VERSION "" hyundai_kia_generic.dbc#L1

NS_ :

BS_:

BU_: IAP ODS _4WD BCM HUD DATC MDPS AAF_Tester AEMC SMK _4WD EPB CUBIS MTS TMU EVP CGW TPMS LPI DI_BOX SPAS EMS LCA TCU IBOX FATC AFLS FPCM SCC AHLS AVM ABS SNV OPI PGS SAS AAF Dummy LDWS_LKAS LVR ESC PSB CLU ECS ACU REA

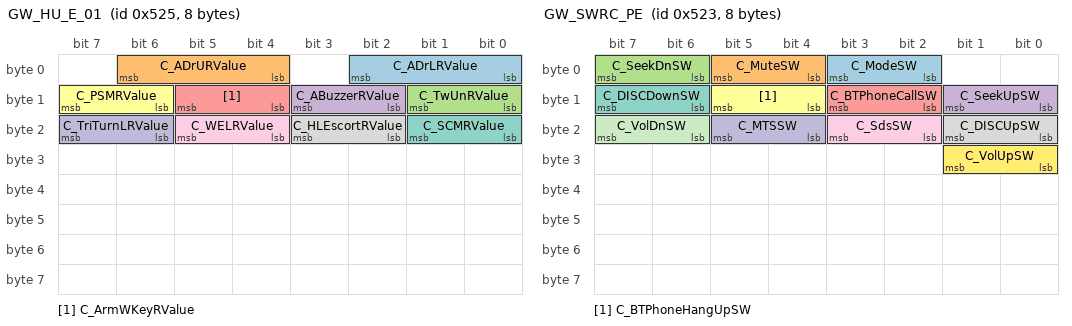
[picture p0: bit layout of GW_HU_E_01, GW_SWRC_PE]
BO_ 1317 GW_HU_E_01: 8 BCM
 SG_ C_ADrLRValue : 0|3@1+ (1.0,0.0) [0.0|7.0] ""  CLU
 SG_ C_ADrURValue : 4|3@1+ (1.0,0.0) [0.0|7.0] ""  CLU
 SG_ C_TwUnRValue : 8|2@1+ (1.0,0.0) [0.0|3.0] ""  CLU
 SG_ C_ABuzzerRValue : 10|2@1+ (1.0,0.0) [0.0|3.0] ""  CLU
 SG_ C_ArmWKeyRValue : 12|2@1+ (1.0,0.0) [0.0|3.0] ""  CLU
 SG_ C_PSMRValue : 14|2@1+ (1.0,0.0) [0.0|3.0] ""  CLU
 SG_ C_SCMRValue : 16|2@1+ (1.0,0.0) [0.0|3.0] ""  CLU
 SG_ C_HLEscortRValue : 18|2@1+ (1.0,0.0) [0.0|3.0] ""  CLU
 SG_ C_WELRValue : 20|2@1+ (1.0,0.0) [0.0|3.0] ""  CLU
 SG_ C_TriTurnLRValue : 22|2@1+ (1.0,0.0) [0.0|3.0] ""  CLU

BO_ 1316 GW_HU_E_00: 8 BCM
 SG_ C_ADrLUNValueConf : 0|2@1+ (1.0,0.0) [0.0|3.0] ""  CLU
 SG_ C_TwUnNValueConf : 2|2@1+ (1.0,0.0) [0.0|3.0] ""  CLU
 SG_ C_AlarmNValueConf : 4|2@1+ (1.0,0.0) [0.0|3.0] ""  CLU
 SG_ C_PSMNValueConf : 6|2@1+ (1.0,0.0) [0.0|3.0] ""  CLU
 SG_ C_SCMNValueConf : 8|2@1+ (1.0,0.0) [0.0|3.0] ""  CLU
 SG_ C_HLEscortNValueConf : 10|2@1+ (1.0,0.0) [0.0|3.0] ""  CLU
 SG_ C_WELNValueConf : 12|2@1+ (1.0,0.0) [0.0|3.0] ""  CLU
 SG_ C_TriTurnLNValueConf : 14|2@1+ (1.0,0.0) [0.0|3.0] ""  CLU

BO_ 1315 GW_SWRC_PE: 8 BCM
 SG_ C_ModeSW : 2|2@1+ (1.0,0.0) [0.0|3.0] ""  CLU
 SG_ C_MuteSW : 4|2@1+ (1.0,0.0) [0.0|3.0] ""  CLU
 SG_ C_SeekDnSW : 6|2@1+ (1.0,0.0) [0.0|3.0] ""  CLU
 SG_ C_SeekUpSW : 8|2@1+ (1.0,0.0) [0.0|3.0] ""  CLU
 SG_ C_BTPhoneCallSW : 10|2@1+ (1.0,0.0) [0.0|3.0] ""  CLU
 SG_ C_BTPhoneHangUpSW : 12|2@1+ (1.0,0.0) [0.0|3.0] ""  CLU
 SG_ C_DISCDownSW : 14|2@1+ (1.0,0.0) [0.0|3.0] ""  CLU
 SG_ C_DISCUpSW : 16|2@1+ (1.0,0.0) [0.0|3.0] ""  CLU
 SG_ C_SdsSW : 18|2@1+ (1.0,0.0) [0.0|3.0] ""  CLU
 SG_ C_MTSSW : 20|2@1+ (1.0,0.0) [0.0|3.0] ""  CLU
 SG_ C_VolDnSW : 22|2@1+ (1.0,0.0) [0.0|3.0] ""  CLU
 SG_ C_VolUpSW : 24|2@1+ (1.0,0.0) [0.0|3.0] ""  CLU

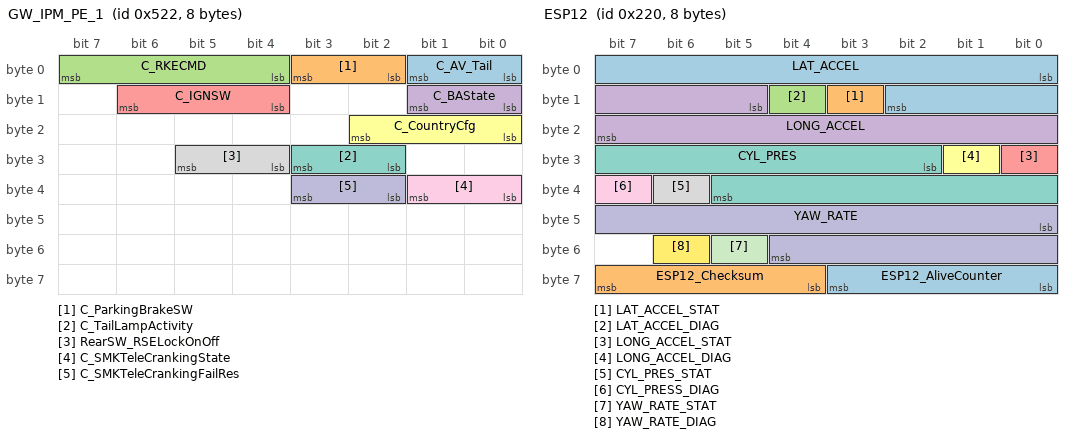
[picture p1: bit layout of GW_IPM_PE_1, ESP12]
BO_ 1314 GW_IPM_PE_1: 8 BCM
 SG_ C_AV_Tail : 0|2@1+ (1.0,0.0) [0.0|3.0] ""  CLU
 SG_ C_ParkingBrakeSW : 2|2@1+ (1.0,0.0) [0.0|3.0] ""  CLU
 SG_ C_RKECMD : 4|4@1+ (1.0,0.0) [0.0|15.0] ""  CLU
 SG_ C_BAState : 8|2@1+ (1.0,0.0) [0.0|3.0] ""  CLU
 SG_ C_IGNSW : 12|3@1+ (1.0,0.0) [0.0|7.0] ""  CLU
 SG_ C_CountryCfg : 16|3@1+ (1.0,0.0) [0.0|7.0] ""  CLU
 SG_ C_TailLampActivity : 26|2@1+ (1.0,0.0) [0.0|3.0] ""  CLU
 SG_ RearSW_RSELockOnOff : 28|2@1+ (1.0,0.0) [0.0|3.0] ""  CLU
 SG_ C_SMKTeleCrankingState : 32|2@1+ (1.0,0.0) [0.0|3.0] ""  CLU
 SG_ C_SMKTeleCrankingFailRes : 34|2@1+ (1.0,0.0) [0.0|3.0] ""  CLU

BO_ 1057 SCC12: 8 SCC
 SG_ CF_VSM_Prefill : 0|1@1+ (1,0) [0|1] "" ESC
 SG_ CF_VSM_DecCmdAct : 1|1@1+ (1,0) [0|1] "" ESC
 SG_ CF_VSM_HBACmd : 2|2@1+ (1,0) [0|3] "" ESC
 SG_ CF_VSM_Warn : 4|2@1+ (1,0) [0|3] "" CLU,ESC,IAP
 SG_ CF_VSM_Stat : 6|2@1+ (1,0) [0|3] "" CLU,ESC,PSB
 SG_ CF_VSM_BeltCmd : 8|3@1+ (1,0) [0|7] "" ESC,PSB
 SG_ ACCFailInfo : 11|2@1+ (1,0) [0|3] "" CLU,CUBIS,ESC,IBOX
 SG_ ACCMode : 13|2@1+ (1,0) [0|3] "" CLU,ESC,IBOX,TCU
 SG_ StopReq : 15|1@1+ (1,0) [0|1] "" EPB,ESC
 SG_ CR_VSM_DecCmd : 16|8@1+ (0.01,0) [0|2.55] "g" ESC
 SG_ TakeOverReq : 35|1@1+ (1,0) [0|1] "" CLU,ESC,TCU
 SG_ PreFill : 36|1@1+ (1,0) [0|1] "" ESC,TCU
 SG_ CF_VSM_ConfMode : 48|2@1+ (1,0) [0|3] "" CLU,ESC
 SG_ AEB_Failinfo : 50|2@1+ (1,0) [0|3] "" CLU,ESC
 SG_ AEB_Status : 52|2@1+ (1,0) [0|3] "" CLU,ESC
 SG_ AEB_CmdAct : 54|1@1+ (1,0) [0|1] "" ESC
 SG_ AEB_StopReq : 55|1@1+ (1,0) [0|1] "" CLU,ESC
 SG_ CR_VSM_Alive : 56|4@1+ (1,0) [0|15] "" ESC,PSB
 SG_ CR_VSM_ChkSum : 60|4@1+ (1,0) [0|15] "" ESC,PSB
 SG_ aReqValue : 37|11@1+ (0.01,-10.23) [-10.23|10.24] "m/s^2" Vector__XXX
 SG_ aReqRaw : 24|11@1+ (0.01,-10.23) [-10.23|10.24] "m/s^2" Vector__XXX

BO_ 1313 GW_DDM_PE: 8 BCM
 SG_ C_DRVDoorStatus : 0|2@1+ (1.0,0.0) [0.0|3.0] ""  CLU
 SG_ C_ASTDoorStatus : 2|2@1+ (1.0,0.0) [0.0|3.0] ""  CLU
 SG_ C_RLDoorStatus : 4|2@1+ (1.0,0.0) [0.0|3.0] ""  CLU
 SG_ C_RRDoorStatus : 6|2@1+ (1.0,0.0) [0.0|3.0] ""  CLU
 SG_ C_TrunkStatus : 8|2@1+ (1.0,0.0) [0.0|3.0] ""  CLU
 SG_ C_OSMirrorStatus : 10|2@1+ (1.0,0.0) [0.0|3.0] ""  CLU

BO_ 1056 SCC11: 8 SCC
 SG_ MainMode_ACC : 0|1@1+ (1,0) [0|1] "" CLU,EMS,ESC
 SG_ SCCInfoDisplay : 1|3@1+ (1,0) [0|7] "" CLU,ESC
 SG_ AliveCounterACC : 4|4@1+ (1,0) [0|15] "" CLU,EMS,ESC,TCU
 SG_ VSetDis : 8|8@1+ (1,0) [0|255] "km/h or MPH" CLU,ESC,TCU
 SG_ ObjValid : 16|1@1+ (1,0) [0|1] "" CLU,ESC,TCU
 SG_ DriverAlertDisplay : 17|2@1+ (1,0) [0|3] "" CLU,ESC
 SG_ TauGapSet : 19|3@1+ (1,0) [0|7] "" CLU,ESC,TCU
 SG_ Navi_SCC_Curve_Status : 56|2@1+ (1,0) [0|3] "" CLU
 SG_ Navi_SCC_Curve_Act : 58|2@1+ (1,0) [0|3] "" CLU
 SG_ Navi_SCC_Camera_Act : 60|2@1+ (1,0) [0|3] "" CLU
 SG_ Navi_SCC_Camera_Status : 62|2@1+ (1,0) [0|3] "" CLU
 SG_ ACC_ObjStatus : 22|2@1+ (1,0) [0|3] "" ABS,ESC
 SG_ ACC_ObjLatPos : 24|9@1+ (0.1,-20) [-20|31.1] "m" ABS,ESC
 SG_ ACC_ObjRelSpd : 44|12@1+ (0.1,-170) [-170|239.5] "m/s" ABS,ESC
 SG_ ACC_ObjDist : 33|11@1+ (0.1,0) [0|204.7] "m" ABS,ESC

BO_ 1312 CGW3: 8 BCM
 SG_ CR_Photosensor_LH : 0|8@1+ (78.125,0.0) [0.0|20000.0] ""  DATC,DATC
 SG_ CR_Photosensor_RH : 10|8@1+ (78.125,0.0) [0.0|20000.0] ""  DATC,DATC
 SG_ CF_Hoodsw_memory : 22|2@1+ (1.0,0.0) [0.0|3.0] ""  EMS,EMS
 SG_ C_MirOutTempSns : 24|8@1+ (0.5,-40.5) [-40.0|60.0] "deg"  AAF,CLU,DATC,EMS,SPAS,AAF,DATC,EMS,SPAS

BO_ 544 ESP12: 8 ESC
 SG_ LAT_ACCEL : 0|11@1+ (0.01,-10.23) [-10.23|10.24] "m/s^2"  _4WD,ECS,IBOX,LCA,LDWS_LKAS,MDPS,PSB,SCC,TCU
 SG_ LAT_ACCEL_STAT : 11|1@1+ (1.0,0.0) [0.0|1.0] ""  _4WD,IBOX,LDWS_LKAS,MDPS,PSB,SCC,TCU
 SG_ LAT_ACCEL_DIAG : 12|1@1+ (1.0,0.0) [0.0|1.0] ""  _4WD,IBOX,LDWS_LKAS,MDPS,PSB,SCC,TCU
 SG_ LONG_ACCEL : 13|11@1+ (0.01,-10.23) [-10.23|10.24] "m/s^2"  _4WD,ECS,EMS,EPB,IBOX,LCA,LDWS_LKAS,PSB,SCC,SPAS,TCU
 SG_ LONG_ACCEL_STAT : 24|1@1+ (1.0,0.0) [0.0|1.0] ""  _4WD,EMS,EPB,IBOX,LDWS_LKAS,PSB,SCC,SPAS,TCU
 SG_ LONG_ACCEL_DIAG : 25|1@1+ (1.0,0.0) [0.0|1.0] ""  _4WD,EMS,EPB,IBOX,LDWS_LKAS,PSB,SCC,SPAS,TCU
 SG_ CYL_PRES : 26|12@1+ (0.1,0.0) [0.0|409.5] "Bar"  _4WD,ECS,EMS,EPB,IBOX,LDWS_LKAS,PSB,SCC,TCU
 SG_ CYL_PRES_STAT : 38|1@1+ (1.0,0.0) [0.0|1.0] ""  _4WD,ECS,EMS,EPB,IBOX,LDWS_LKAS,PSB,SCC,TCU
 SG_ CYL_PRESS_DIAG : 39|1@1+ (1.0,0.0) [0.0|1.0] ""  _4WD,ECS,EMS,EPB,IBOX,PSB,SCC,TCU
 SG_ YAW_RATE : 40|13@1+ (0.01,-40.95) [-40.95|40.96] ""  _4WD,AFLS,IBOX,LCA,LDWS_LKAS,MDPS,PSB,SCC,SPAS,TCU
 SG_ YAW_RATE_STAT : 53|1@1+ (1.0,0.0) [0.0|1.0] ""  _4WD,AFLS,IBOX,LCA,LDWS_LKAS,MDPS,PSB,SCC,SPAS,TCU
 SG_ YAW_RATE_DIAG : 54|1@1+ (1.0,0.0) [0.0|1.0] ""  _4WD,AFLS,IBOX,LCA,LDWS_LKAS,MDPS,PSB,SCC,SPAS,TCU
 SG_ ESP12_AliveCounter : 56|4@1+ (1.0,0.0) [0.0|15.0] ""  _4WD,EMS,LPI,TCU,TMU
 SG_ ESP12_Checksum : 60|4@1+ (1.0,0.0) [0.0|15.0] ""  _4WD,EMS,LPI,TCU,TMU

BO_ 1307 CLU16: 8 CLU
 SG_ CF_Clu_TirePressUnitNValueSet : 0|3@1+ (1.0,0.0) [0.0|7.0] ""  TPMS
 SG_ CF_Clu_SlifNValueSet : 3|2@1+ (1.0,0.0) [0.0|3.0] ""  LDWS_LKAS
 SG_ CF_Clu_RearWiperNValueSet : 12|2@1+ (1.0,0.0) [0.0|3.0] ""  BCM

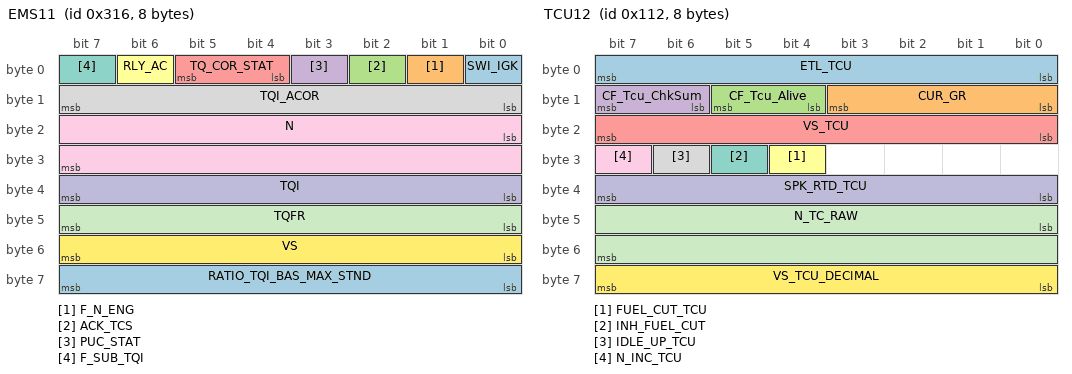
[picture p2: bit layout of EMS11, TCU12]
BO_ 790 EMS11: 8 EMS
 SG_ SWI_IGK : 0|1@1+ (1.0,0.0) [0.0|1.0] ""  _4WD,ABS,ACU,AHLS,CUBIS,DI_BOX,ECS,EPB,ESC,IBOX,LDWS_LKAS,MDPS,REA,SAS,SCC,TCU
 SG_ F_N_ENG : 1|1@1+ (1.0,0.0) [0.0|1.0] ""  _4WD,ACU,AFLS,CLU,CUBIS,DATC,ECS,EPB,ESC,IBOX,MDPS,SCC,TCU
 SG_ ACK_TCS : 2|1@1+ (1.0,0.0) [0.0|1.0] ""  ESC,IBOX
 SG_ PUC_STAT : 3|1@1+ (1.0,0.0) [0.0|1.0] ""  _4WD,CLU,DATC,IBOX,TCU
 SG_ TQ_COR_STAT : 4|2@1+ (1.0,0.0) [0.0|3.0] ""  _4WD,ESC,IBOX,TCU
 SG_ RLY_AC : 6|1@1+ (1.0,0.0) [0.0|1.0] ""  DATC,IBOX,TCU
 SG_ F_SUB_TQI : 7|1@1+ (1.0,0.0) [0.0|1.0] ""  _4WD,ECS,EPB,ESC,IBOX,TCU
 SG_ TQI_ACOR : 8|8@1+ (0.390625,0.0) [0.0|99.6094] "%"  _4WD,EPB,ESC,IBOX,TCU
 SG_ N : 16|16@1+ (0.25,0.0) [0.0|16383.75] "rpm"  _4WD,ACU,AFLS,CLU,CUBIS,DATC,ECS,EPB,ESC,FPCM,IBOX,MDPS,SCC,TCU
 SG_ TQI : 32|8@1+ (0.390625,0.0) [0.0|99.6094] "%"  _4WD,ECS,EPB,ESC,IBOX,TCU
 SG_ TQFR : 40|8@1+ (0.390625,0.0) [0.0|99.6094] "%"  _4WD,EPB,ESC,IBOX,TCU
 SG_ VS : 48|8@1+ (1.0,0.0) [0.0|254.0] "km/h"  _4WD,AAF,ACU,AHLS,BCM,CLU,DATC,ECS,EPB,IBOX,LCA,LDWS_LKAS,LVR,MDPS,ODS,SCC,SMK,SPAS,TCU,TPMS
 SG_ RATIO_TQI_BAS_MAX_STND : 56|8@1+ (0.0078,0.0) [0.0|2.0] ""  _4WD,IBOX,TCU

BO_ 1301 CLU14: 8 CLU
 SG_ CF_Clu_ADrUNValueSet : 0|3@1+ (1.0,0.0) [0.0|7.0] ""  BCM
 SG_ CF_Clu_ADrLNValueSet : 3|3@1+ (1.0,0.0) [0.0|7.0] ""  BCM
 SG_ CF_Clu_EscortHLNValueSet : 6|2@1+ (1.0,0.0) [0.0|3.0] ""  BCM
 SG_ CF_Clu_DoorLSNValueSet : 8|3@1+ (1.0,0.0) [0.0|7.0] ""  BCM
 SG_ CF_Clu_PSMNValueSet : 11|3@1+ (1.0,0.0) [0.0|7.0] ""  BCM
 SG_ CF_Clu_TTUnlockNValueSet : 14|2@1+ (1.0,0.0) [0.0|3.0] ""  BCM
 SG_ CF_Clu_PTGMNValueSet : 16|2@1+ (1.0,0.0) [0.0|3.0] ""  BCM
 SG_ CF_Clu_SCMNValueSet : 18|2@1+ (1.0,0.0) [0.0|3.0] ""  BCM
 SG_ CF_Clu_WlightNValueSet : 20|2@1+ (1.0,0.0) [0.0|3.0] ""  BCM
 SG_ CF_Clu_TempUnitNValueSet : 22|2@1+ (1.0,0.0) [0.0|3.0] ""  BCM,DATC
 SG_ CF_Clu_MoodLpNValueSet : 24|3@1+ (1.0,0.0) [0.0|7.0] ""  BCM
 SG_ CF_Clu_TrfChgSet : 27|2@1+ (1.0,0.0) [0.0|3.0] ""  AFLS
 SG_ CF_Clu_OTTurnNValueSet : 29|3@1+ (1.0,0.0) [0.0|7.0] ""  BCM
 SG_ CF_Clu_LcaNValueSet : 32|2@1+ (1.0,0.0) [0.0|3.0] ""  LCA
 SG_ CF_Clu_RctaNValueSet : 34|2@1+ (1.0,0.0) [0.0|3.0] ""  LCA
 SG_ CF_Clu_RcwNValueSet : 36|2@1+ (1.0,0.0) [0.0|3.0] ""  LCA
 SG_ CF_Clu_EscOffNValueSet : 38|3@1+ (1.0,0.0) [0.0|7.0] ""  ESC
 SG_ CF_Clu_SccNaviCrvNValueSet : 41|2@1+ (1.0,0.0) [0.0|3.0] ""  SCC
 SG_ CF_Clu_SccNaviCamNValueSet : 43|2@1+ (1.0,0.0) [0.0|3.0] ""  SCC
 SG_ CF_Clu_SccAebNValueSet : 45|2@1+ (1.0,0.0) [0.0|3.0] ""  SCC
 SG_ CF_Clu_LkasModeNValueSet : 47|2@1+ (1.0,0.0) [0.0|3.0] ""  LDWS_LKAS
 SG_ CF_Clu_FcwNValueSet : 51|2@1+ (1.0,0.0) [0.0|3.0] ""  LDWS_LKAS
 SG_ CF_Clu_PasSpkrLvNValueSet : 53|3@1+ (1.0,0.0) [0.0|7.0] ""  BCM
 SG_ CF_Clu_SccDrvModeNValueSet : 56|3@1+ (1.0,0.0) [0.0|7.0] ""  SCC
 SG_ CF_Clu_HAnBNValueSet : 59|2@1+ (1.0,0.0) [0.0|3.0] ""  BCM
 SG_ CF_Clu_HfreeTrunkTgNValueSet : 61|3@1+ (1.0,0.0) [0.0|7.0] ""  BCM

BO_ 275 TCU13: 8 TCU
 SG_ N_TGT_LUP : 0|8@1+ (10.0,500.0) [500.0|3040.0] "rpm"  EMS,IBOX
 SG_ SLOPE_TCU : 8|6@1+ (0.5,-16.0) [-16.0|15.5] "%"  CLU,CUBIS,EMS,IBOX
 SG_ CF_Tcu_InhCda : 14|1@1+ (1.0,0.0) [0.0|1.0] ""  EMS,IBOX
 SG_ CF_Tcu_IsgInhib : 15|1@1+ (1.0,0.0) [0.0|1.0] ""  EMS,IBOX
 SG_ CF_Tcu_BkeOnReq : 16|2@1+ (1.0,0.0) [0.0|3.0] ""  EMS,IBOX
 SG_ CF_Tcu_NCStat : 18|2@1+ (1.0,0.0) [0.0|3.0] ""  EMS,IBOX
 SG_ CF_Tcu_TarGr : 20|4@1+ (1.0,0.0) [0.0|15.0] ""  _4WD,CLU,DATC,EMS,EPB,ESC,IBOX,SCC
 SG_ CF_Tcu_ShfPatt : 24|4@1+ (1.0,0.0) [0.0|15.0] ""  CLU,CUBIS,EMS,IBOX
 SG_ CF_Tcu_InhVis : 28|1@1+ (1.0,0.0) [0.0|1.0] ""  EMS,IBOX
 SG_ CF_Tcu_PRelReq : 29|1@1+ (1.0,0.0) [0.0|1.0] ""  IBOX,LVR
 SG_ CF_Tcu_ITPhase : 30|1@1+ (1.0,0.0) [0.0|1.0] ""  EMS,IBOX
 SG_ CF_Tcu_ActEcoRdy : 31|1@1+ (1.0,0.0) [0.0|1.0] ""  EMS,IBOX
 SG_ CF_Tcu_TqGrdLim : 32|8@1+ (10.0,0.0) [0.0|2540.0] "Nm/s"  EMS,IBOX
 SG_ CR_Tcu_IsgTgtRPM : 40|8@1+ (20.0,0.0) [0.0|3500.0] "rpm"  EMS,IBOX
 SG_ CF_Tcu_SptRdy : 48|1@1+ (1.0,0.0) [0.0|1.0] ""  CLU,IBOX
 SG_ CF_Tcu_SbwPInfo : 56|1@1+ (1.0,0.0) [0.0|1.0] ""  EMS,IBOX
 SG_ CF_Tcu_Alive3 : 58|2@1+ (1.0,0.0) [0.0|3.0] ""  EMS,IBOX
 SG_ CF_Tcu_ChkSum3 : 60|4@1+ (1.0,0.0) [0.0|15.0] ""  EMS,IBOX

BO_ 274 TCU12: 8 TCU
 SG_ ETL_TCU : 0|8@1+ (2.0,0.0) [0.0|508.0] "Nm"  EMS,IBOX
 SG_ CUR_GR : 8|4@1+ (1.0,0.0) [0.0|15.0] ""  _4WD,EMS,ESC,IBOX,SCC,TPMS
 SG_ CF_Tcu_Alive : 12|2@1+ (1.0,0.0) [0.0|3.0] ""  EMS,ESC,IBOX,SCC
 SG_ CF_Tcu_ChkSum : 14|2@1+ (1.0,0.0) [0.0|3.0] ""  EMS,ESC,IBOX,SCC
 SG_ VS_TCU : 16|8@1+ (1.0,0.0) [0.0|254.0] "km/h"  BCM,CLU,DATC,EMS,IBOX,LCA,LVR,PGS,SMK,SNV
 SG_ FUEL_CUT_TCU : 28|1@1+ (1.0,0.0) [0.0|1.0] ""  EMS,IBOX
 SG_ INH_FUEL_CUT : 29|1@1+ (1.0,0.0) [0.0|1.0] ""  EMS,IBOX
 SG_ IDLE_UP_TCU : 30|1@1+ (1.0,0.0) [0.0|1.0] ""  EMS,IBOX
 SG_ N_INC_TCU : 31|1@1+ (1.0,0.0) [0.0|1.0] ""  EMS,IBOX
 SG_ SPK_RTD_TCU : 32|8@1+ (0.375,-23.625) [-15.0|15.0] ""  EMS,IBOX
 SG_ N_TC_RAW : 40|16@1+ (0.25,0.0) [0.0|16383.5] "rpm"  EMS,IBOX
 SG_ VS_TCU_DECIMAL : 56|8@1+ (0.0078125,0.0) [0.0|0.9921875] "km/h"  CLU,EMS,IBOX,LCA

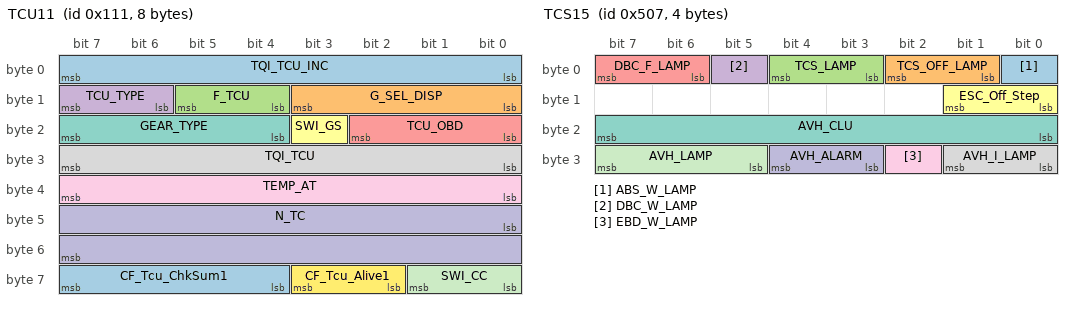
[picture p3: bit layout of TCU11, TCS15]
BO_ 273 TCU11: 8 TCU
 SG_ TQI_TCU_INC : 0|8@1+ (0.390625,0.0) [0.0|99.609375] "%"  EMS,ESC,IBOX
 SG_ G_SEL_DISP : 8|4@1+ (1.0,0.0) [0.0|15.0] ""  _4WD,AFLS,AVM,BCM,CGW,CLU,CUBIS,ECS,EMS,EPB,ESC,IAP,IBOX,LCA,LDWS_LKAS,LVR,MDPS,PGS,SCC,SMK,SNV,SPAS,TPMS
 SG_ F_TCU : 12|2@1+ (1.0,0.0) [0.0|3.0] ""  EMS,ESC,IBOX
 SG_ TCU_TYPE : 14|2@1+ (1.0,0.0) [0.0|3.0] ""  _4WD,EMS,ESC,IBOX
 SG_ TCU_OBD : 16|3@1+ (1.0,0.0) [0.0|7.0] ""  EMS,ESC,IBOX
 SG_ SWI_GS : 19|1@1+ (1.0,0.0) [0.0|1.0] ""  _4WD,EMS,EPB,ESC,IBOX,SCC
 SG_ GEAR_TYPE : 20|4@1+ (1.0,0.0) [0.0|15.0] ""  _4WD,CLU,EMS,ESC,IBOX,SCC
 SG_ TQI_TCU : 24|8@1+ (0.390625,0.0) [0.0|99.609375] "%"  EMS,ESC,IBOX
 SG_ TEMP_AT : 32|8@1+ (1.0,-40.0) [-40.0|214.0] "deg"  AAF,CLU,CUBIS,EMS,ESC,IBOX
 SG_ N_TC : 40|16@1+ (0.25,0.0) [0.0|16383.5] "rpm"  _4WD,EMS,EPB,ESC,IBOX
 SG_ SWI_CC : 56|2@1+ (1.0,0.0) [0.0|3.0] ""  _4WD,CLU,EMS,ESC,IBOX
 SG_ CF_Tcu_Alive1 : 58|2@1+ (1.0,0.0) [0.0|3.0] ""  EMS,IBOX
 SG_ CF_Tcu_ChkSum1 : 60|4@1+ (1.0,0.0) [0.0|15.0] ""  EMS,IBOX

BO_ 16 ACU13: 8 ACU
 SG_ CF_Acu_CshAct : 0|1@1+ (1.0,0.0) [0.0|1.0] ""  CUBIS,IBOX,ODS

BO_ 1040 CGW_USM1: 8 BCM
 SG_ CF_Gway_ATTurnRValue : 0|2@1+ (1.0,0.0) [0.0|3.0] ""  CLU
 SG_ CF_Gway_PTGMRValue : 2|2@1+ (1.0,0.0) [0.0|3.0] ""  CLU
 SG_ CF_Gway_EscortHLRValue : 4|2@1+ (1.0,0.0) [0.0|3.0] ""  CLU
 SG_ CF_Gway_TTUnlockRValue : 6|2@1+ (1.0,0.0) [0.0|3.0] ""  CLU
 SG_ CF_Gway_ADrLRValue : 8|3@1+ (1.0,0.0) [0.0|7.0] ""  CLU
 SG_ CF_Gway_ADrURValue : 11|3@1+ (1.0,0.0) [0.0|7.0] ""  CLU
 SG_ CF_Gway_SCMRValue : 14|2@1+ (1.0,0.0) [0.0|3.0] ""  CLU
 SG_ CF_Gway_WlightRValue : 16|2@1+ (1.0,0.0) [0.0|3.0] ""  CLU
 SG_ CF_Gway_PSMRValue : 18|3@1+ (1.0,0.0) [0.0|7.0] ""  CLU
 SG_ CF_Gway_OTTurnRValue : 21|3@1+ (1.0,0.0) [0.0|7.0] ""  CLU
 SG_ CF_Gway_DrLockSoundRValue : 24|3@1+ (1.0,0.0) [0.0|7.0] ""  CLU
 SG_ CF_Gway_HAnBRValue : 27|3@1+ (1.0,0.0) [0.0|7.0] ""  CLU
 SG_ CF_Gway_MoodLpRValue : 30|2@1+ (1.0,0.0) [0.0|3.0] ""  CLU
 SG_ CF_Gway_HfreeTrunkRValue : 32|3@1+ (1.0,0.0) [0.0|7.0] ""  CLU
 SG_ CF_Gway_AutoLightRValue : 35|3@1+ (1.0,0.0) [0.0|7.0] ""  CLU
 SG_ CF_Gway_RearWiperRValue : 38|2@1+ (1.0,0.0) [0.0|3.0] ""  CLU
 SG_ CF_Gway_PasSpkrLvRValue : 40|3@1+ (1.0,0.0) [0.0|7.0] ""  CLU

BO_ 1292 CLU13: 8 CLU
 SG_ CF_Clu_LowfuelWarn : 0|2@1+ (1.0,0.0) [0.0|3.0] ""  BCM,FPCM,IBOX
 SG_ CF_Clu_RefDetMod : 2|1@1+ (1.0,0.0) [0.0|1.0] ""  IBOX
 SG_ CF_Clu_AvgFCU : 3|2@1+ (1.0,0.0) [0.0|3.0] ""  IBOX
 SG_ CF_Clu_AvsmCur : 5|1@1+ (1.0,0.0) [0.0|1.0] ""  ESC,SCC
 SG_ CF_Clu_AvgFCI : 6|10@1+ (0.1,0.0) [0.0|102.2] ""  IBOX
 SG_ CF_Clu_DrivingModeSwi : 16|2@1+ (1.0,0.0) [0.0|3.0] ""  DATC,ECS,EMS,ESC,IAP,MDPS,TCU
 SG_ CF_Clu_FuelDispLvl : 18|5@1+ (1.0,0.0) [0.0|31.0] ""  CGW,IBOX
 SG_ CF_Clu_FlexSteerSW : 23|1@1+ (1.0,0.0) [0.0|1.0] ""  MDPS
 SG_ CF_Clu_DTE : 24|10@1+ (1.0,0.0) [0.0|1023.0] ""  DATC
 SG_ CF_Clu_TripUnit : 34|2@1+ (1.0,0.0) [0.0|3.0] ""  DATC
 SG_ CF_Clu_SWL_Stat : 36|3@1+ (1.0,0.0) [0.0|7.0] ""  ACU,EMS
 SG_ CF_Clu_ActiveEcoSW : 39|1@1+ (1.0,0.0) [0.0|1.0] ""  DATC,EMS,TCU
 SG_ CF_Clu_EcoDriveInf : 40|3@1+ (1.0,0.0) [0.0|7.0] ""  CUBIS,EMS,IAP,IBOX
 SG_ CF_Clu_IsaMainSW : 43|1@1+ (1.0,0.0) [0.0|1.0] ""  EMS
 SG_ CF_Clu_LdwsLkasSW : 56|1@1+ (1.0,0.0) [0.0|1.0] ""  LDWS_LKAS
 SG_ CF_Clu_AltLStatus : 59|1@1+ (1.0,0.0) [0.0|1.0] ""  BCM,DATC,EMS
 SG_ CF_Clu_AliveCnt2 : 60|4@1+ (1.0,0.0) [0.0|15.0] ""  EMS,LDWS_LKAS

BO_ 1290 SCC13: 8 SCC
 SG_ SCCDrvModeRValue : 0|3@1+ (1,0) [0|7] "" CLU
 SG_ SCC_Equip : 3|1@1+ (1,0) [0|1] "" ESC
 SG_ AebDrvSetStatus : 4|3@1+ (1,0) [0|7] "" CLU,ESC
 SG_ Lead_Veh_Dep_Alert_USM : 13|2@0+ (1,0) [0|3] "" XXX

BO_ 1287 TCS15: 4 ESC
 SG_ ABS_W_LAMP : 0|1@1+ (1.0,0.0) [0.0|1.0] ""  _4WD,CLU,CUBIS,IBOX
 SG_ TCS_OFF_LAMP : 1|2@1+ (1.0,0.0) [0.0|1.0] ""  _4WD,ACU,CLU
 SG_ TCS_LAMP : 3|2@1+ (1.0,0.0) [0.0|3.0] ""  _4WD,ACU,CLU,CUBIS,IBOX,SCC
 SG_ DBC_W_LAMP : 5|1@1+ (1.0,0.0) [0.0|1.0] ""  _4WD,CLU
 SG_ DBC_F_LAMP : 6|2@1+ (1.0,0.0) [0.0|3.0] ""  _4WD,CLU
 SG_ ESC_Off_Step : 8|2@1+ (1.0,0.0) [0.0|3.0] ""  CLU
 SG_ AVH_CLU : 16|8@1+ (1.0,0.0) [0.0|255.0] ""  CLU,EPB
 SG_ AVH_I_LAMP : 24|2@1+ (1.0,0.0) [0.0|3.0] ""  EPB
 SG_ EBD_W_LAMP : 26|1@1+ (1.0,0.0) [0.0|1.0] ""  _4WD,CLU
 SG_ AVH_ALARM : 27|2@1+ (1.0,0.0) [0.0|3.0] ""  CLU
 SG_ AVH_LAMP : 29|3@1+ (1.0,0.0) [0.0|7.0] ""  CLU,EPB,SPAS

BO_ 1282 TCU14: 4 TCU
 SG_ CF_TCU_WarnMsg : 0|3@1+ (1.0,0.0) [0.0|7.0] ""  CLU
 SG_ CF_TCU_WarnImg : 3|1@1+ (1.0,0.0) [0.0|1.0] ""  CLU
 SG_ CF_TCU_WarnSnd : 4|1@1+ (1.0,0.0) [0.0|1.0] ""  CLU
 SG_ CF_Tcu_GSel_BlinkReq : 5|1@1+ (1.0,0.0) [0.0|1.0] ""  CLU,LVR
 SG_ CF_Tcu_StRelStat : 12|1@1+ (1.0,0.0) [0.0|1.0] ""  CLU,EMS,ESC
 SG_ CF_Tcu_DriWarn1 : 13|3@1+ (1.0,0.0) [0.0|7.0] ""  CLU,EMS,ESC
 SG_ CF_Tcu_DriWarn2 : 16|2@1+ (1.0,0.0) [0.0|3.0] ""  CLU,EMS,ESC

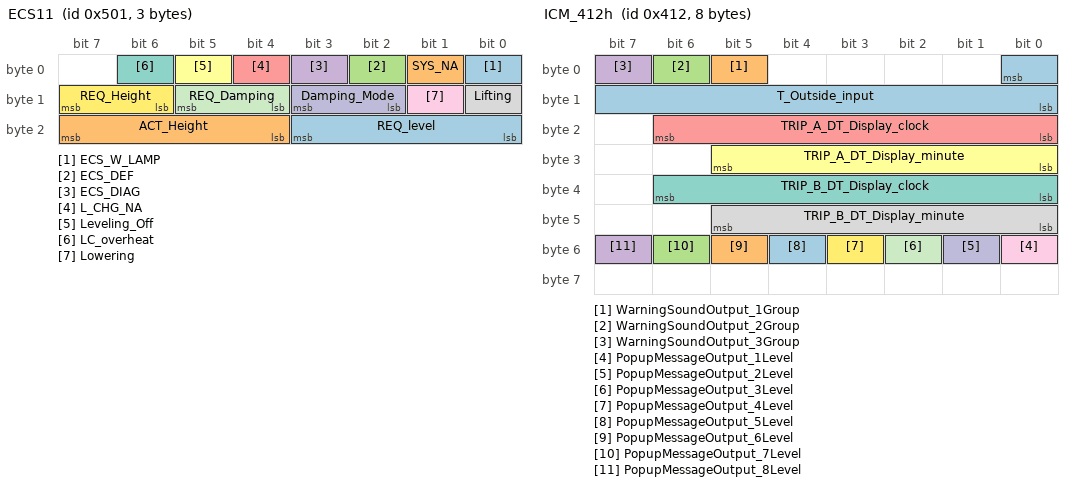
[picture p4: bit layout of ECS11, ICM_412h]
BO_ 1281 ECS11: 3 ECS
 SG_ ECS_W_LAMP : 0|1@1+ (1.0,0.0) [0.0|1.0] ""  CLU,CUBIS,IBOX
 SG_ SYS_NA : 1|1@1+ (1.0,0.0) [0.0|1.0] ""  CLU
 SG_ ECS_DEF : 2|1@1+ (1.0,0.0) [0.0|1.0] ""  CLU
 SG_ ECS_DIAG : 3|1@1+ (1.0,0.0) [0.0|1.0] ""  CLU
 SG_ L_CHG_NA : 4|1@1+ (1.0,0.0) [0.0|1.0] ""  CLU
 SG_ Leveling_Off : 5|1@1+ (1.0,0.0) [0.0|1.0] ""  CLU
 SG_ LC_overheat : 6|1@1+ (1.0,0.0) [0.0|1.0] ""  CLU
 SG_ Lifting : 8|1@1+ (1.0,0.0) [0.0|1.0] ""  CLU
 SG_ Lowering : 9|1@1+ (1.0,0.0) [0.0|1.0] ""  CLU
 SG_ Damping_Mode : 10|2@1+ (1.0,0.0) [0.0|3.0] ""  CLU
 SG_ REQ_Damping : 12|2@1+ (1.0,0.0) [0.0|3.0] ""  CLU
 SG_ REQ_Height : 14|2@1+ (1.0,0.0) [0.0|3.0] ""  CLU
 SG_ REQ_level : 16|4@1+ (1.0,0.0) [0.0|15.0] ""  CLU
 SG_ ACT_Height : 20|4@1+ (1.0,0.0) [0.0|15.0] ""  CLU

BO_ 1024 CLU_CFG11: 2 CLU
 SG_ Vehicle_Type : 0|16@1+ (1.0,0.0) [0.0|65536.0] ""  _4WD

BO_ 1280 ACU14: 1 ACU
 SG_ CF_SWL_Ind : 0|2@1+ (1.0,0.0) [0.0|3.0] ""  CLU
 SG_ CF_TTL_Ind : 2|2@1+ (1.0,0.0) [0.0|3.0] ""  CLU
 SG_ CF_SBR_Ind : 4|2@1+ (1.0,0.0) [0.0|3.0] ""  BCM,CLU

BO_ 512 EMS20: 6 EMS
 SG_ FCO : 0|16@1+ (0.128,0.0) [0.0|8388.48] "ul"  CLU,CUBIS,FPCM,IBOX
 SG_ CF_Ems_PumpTPres : 16|8@1+ (3.137254902,0.0) [0.0|800.0] "kPa"  FPCM,IBOX
 SG_ Split_Stat : 32|1@1+ (1.0,0.0) [0.0|1.0] ""  FPCM

BO_ 909 FCA11: 8 FCA
 SG_ CF_VSM_Prefill : 0|1@1+ (1,0) [0|1] "" ESC
 SG_ CF_VSM_HBACmd : 1|2@1+ (1,0) [0|3] "" ESC
 SG_ CF_VSM_Warn : 3|2@1+ (1,0) [0|3] "" ACU,CLU,ESC
 SG_ CF_VSM_BeltCmd : 5|3@1+ (1,0) [0|7] "" ESC
 SG_ CR_VSM_DecCmd : 8|8@1+ (0.01,0) [0|2.55] "g" ESC
 SG_ FCA_Status : 18|2@1+ (1,0) [0|3] "" ACU,CLU,ESC
 SG_ FCA_CmdAct : 20|1@1+ (1,0) [0|1] "" ESC
 SG_ FCA_StopReq : 21|1@1+ (1,0) [0|1] "" CLU,ESC
 SG_ FCA_DrvSetStatus : 22|3@1+ (1,0) [0|7] "" CLU,ESC
 SG_ CF_VSM_DecCmdAct : 31|1@1+ (1,0) [0|1] "" ESC
 SG_ FCA_Failinfo : 32|3@1+ (1,0) [0|7] "" ACU,CLU,ESC
 SG_ FCA_RelativeVelocity : 39|9@1+ (0.1,-25.5) [-25.5|25.5] "m/s" iBAU
 SG_ FCA_TimetoCollision : 48|8@1+ (10,0) [0|2540] "ms" iBAU
 SG_ CR_FCA_Alive : 56|4@1+ (1,0) [0|15] "" ESC
 SG_ CR_FCA_ChkSum : 60|4@1+ (1,0) [0|15] "" ESC
 SG_ Supplemental_Counter : 35|4@1+ (1,0) [0|15] "" XXX
 SG_ PAINT1_Status : 16|2@1+ (1,0) [0|1] "" XXX

BO_ 1156 HDA11_MFC: 8 XXX
 SG_ Counter : 5|4@0+ (1,0) [0|15] "" XXX
 SG_ NEW_SIGNAL_1 : 1|2@0+ (1,0) [0|255] "" XXX
 SG_ NEW_SIGNAL_2 : 7|2@0+ (1,0) [0|3] "" XXX
 SG_ NEW_SIGNAL_3 : 15|8@0+ (1,0) [0|255] "" XXX
 SG_ NEW_SIGNAL_4 : 16|2@1+ (1,0) [0|3] "" XXX
 SG_ NEW_SIGNAL_5 : 18|14@1+ (1,0) [0|63] "" XXX
 SG_ NEW_SIGNAL_6 : 33|2@0+ (1,0) [0|1] "" XXX
 SG_ NEW_SIGNAL_7 : 34|14@1+ (1,0) [0|16383] "" XXX
 SG_ NEW_SIGNAL_8 : 49|2@0+ (1,0) [0|1] "" XXX
 SG_ NEW_SIGNAL_9 : 50|14@1- (1,-4095) [0|16383] "" XXX

BO_ 1155 FCA12: 8 FCA
 SG_ FCA_USM : 0|3@1+ (1,0) [0|7] "" CGW,CLU,ESC
 SG_ FCA_DrvSetState : 3|3@1+ (1,0) [0|7] "" CGW

BO_ 1186 FRT_RADAR11: 2 FCA
 SG_ CF_FCA_Equip_Front_Radar : 0|3@1+ (1,0) [0|7] "" LDWS_LKAS,LDW_LKA,ESC

BO_ 905 SCC14: 8 SCC
 SG_ ComfortBandUpper : 0|6@1+ (0.0986,-4.14) [0|1.26] "m/s^2" ESC
 SG_ ComfortBandLower : 6|6@1+ (0.0986,-4.14) [0|1.26] "m/s^2" ESC
 SG_ JerkUpperLimit : 12|7@1+ (1,0) [0|12.7] "m/s^3" ESC
 SG_ JerkLowerLimit : 19|7@1+ (0.1,0) [0|12.7] "m/s^3" ESC
 SG_ ACCMode : 32|3@1+ (1,0) [0|7] "" CLU,HUD,LDWS_LKAS,ESC
 SG_ ObjGap : 56|8@1+ (1,0) [0|255] "" CLU,HUD,ESC

BO_ 1157 LFAHDA_MFC: 4 XXX
 SG_ HDA_USM : 0|2@1+ (1,0) [0|3] "" XXX
 SG_ ACTIVE2 : 4|2@0+ (1,0) [0|3] "" XXX
 SG_ LFA_SysWarning : 16|2@1+ (1,0) [0|3] "" XXX
 SG_ ACTIVE : 25|1@1+ (1,0) [0|3] "" XXX
 SG_ LFA_USM : 28|2@1+ (1,0) [0|3] "" XXX

BO_ 913 BCM_PO_11: 8 Vector__XXX
 SG_ BCM_Door_Dri_Status : 5|1@0+ (1,0) [0|1] "" PT_ESC_ABS
 SG_ BCM_Shift_R_MT_SW_Status : 39|2@0+ (1,0) [0|3] "" PT_ESC_ABS

BO_ 1426 LABEL11: 8 XXX
 SG_ CC_React : 34|1@1+ (1,0) [0|1] "" XXX

BO_ 910 WHL_SPD12_FS: 5 iBAU
 SG_ CRC : 0|8@1+ (1,0) [0|0] "" Vector__XXX
 SG_ WHL_SPD12_AliveCounter : 8|4@1+ (1,0) [0|15] "" Vector__XXX
 SG_ WHL_SPD_FL : 12|14@1+ (0.03125,0) [0|511.96875] "km/h" Vector__XXX
 SG_ WHL_SPD_FR : 26|14@1+ (0.03125,0) [0|511.96875] "km/h" Vector__XXX

BO_ 911 WHL_SPD13_FS: 5 iBAU
 SG_ CRC : 0|8@1+ (1,0) [0|0] "" Vector__XXX
 SG_ WHL_SPD13_AliveCounter : 8|4@1+ (1,0) [0|15] "" Vector__XXX
 SG_ WHL_SPD_RL : 12|14@1+ (0.03125,0) [0|511.96875] "km/h" Vector__XXX
 SG_ WHL_SPD_RR : 26|14@1+ (0.03125,0) [0|511.96875] "km/h" Vector__XXX

BO_ 865 ADAS_PRK_11: 8 ADAS_PRK
 SG_ CF_PCA_BrkReq : 24|1@1+ (1,0) [0|0] "" Vector__XXX
 SG_ CF_PCA_DclTrgtVal : 28|4@1+ (0.04,0) [0|0] "g" Vector__XXX
 SG_ PCA_ALIVE_CNT : 40|4@1+ (1,0) [0|0] "" Vector__XXX
 SG_ PCA_CHECK_SUM : 48|8@1+ (1,0) [0|0] "" Vector__XXX

BO_ 882 ELECT_GEAR: 8 XXX
 SG_ Elect_Gear_Shifter : 16|4@1+ (1,0) [0|7] ""  CLU

BO_ 881 E_EMS11: 8 XXX
 SG_ Brake_Pedal_Pos : 0|8@1+ (1,0) [0|127] "" XXX
 SG_ IG_Reactive_Stat : 8|3@1+ (1,0) [0|3] "" XXX
 SG_ Gear_Change : 12|1@0+ (1,0) [0|31] "" XXX
 SG_ Cruise_Limit_Status : 13|1@1+ (1,0) [0|1] "" XXX
 SG_ Cruise_Limit_Target : 23|8@1+ (1,0) [0|15] "" XXX
 SG_ Accel_Pedal_Pos : 31|8@1+ (1,0) [0|7] "" XXX

BO_ 1355 EV_PC6: 8 CGW
 SG_ CF_Vcu_SbwWarnMsg : 16|3@1+ (1,0) [0|7] "" Vector__XXX

BO_ 1430 EV_PC2: 8 CGW
 SG_ CR_Ldc_ActVol_LS_V : 32|8@1+ (0.1,0) [0|0] "V" Vector__XXX

BO_ 1535 EV_PC10: 8 CGW
 SG_ CF_Vcu_EpbRequest : 37|1@1+ (1,0) [0|0] "" Vector__XXX

BO_ 908 RSPA11: 8 RSPA
 SG_ CF_RSPA_State : 0|4@1+ (1,0) [0|15] "" XXX
 SG_ CF_RSPA_Act : 4|2@1+ (1,0) [0|3] "" XXX
 SG_ CF_RSPA_DecCmd : 6|2@1+ (1,0) [0|3] "" XXX
 SG_ CF_RSPA_Trgt_Spd : 8|10@1+ (0.01,0) [0|10.23] "km/h" XXX
 SG_ CF_RSPA_StopReq : 18|1@1+ (1,0) [0|2] "" XXX
 SG_ CR_RSPA_EPB_Req : 22|2@1+ (1,0) [0|3] "" XXX
 SG_ CF_RSPA_ACC_ACT : 50|1@1+ (1,0) [0|2] "" XXX
 SG_ CF_RSPA_AliveCounter : 52|4@1+ (1,0) [0|15] "" XXX
 SG_ CF_RSPA_CRC : 56|8@1+ (1,0) [0|255] "" XXX

BO_ 914 S_MDPS11: 8 XXX
 SG_ CF_Mdps_Stat : 0|4@1+ (1,0) [0|15] "" XXX
 SG_ CR_Mdps_DrvTq : 8|12@1+ (1,0) [0|15] "" XXX
 SG_ CR_Mdps_StrAng : 24|16@1- (1,0) [0|65535] "" XXX
 SG_ CF_Mdps_AliveCnt : 47|8@0+ (1,0) [0|255] "" XXX
 SG_ CF_Mdps_Chksum : 63|8@0+ (1,0) [0|255] "" XXX

BO_ 357 S_MDPS12: 8 XXX
 SG_ NEW_SIGNAL_1 : 0|12@1+ (1,0) [0|4095] "" XXX
 SG_ NEW_SIGNAL_2 : 12|12@1+ (1,0) [0|4095] "" XXX
 SG_ Counter : 48|4@1+ (1,0) [0|15] "" XXX
 SG_ Checksum : 63|8@0+ (1,0) [0|255] "" XXX

BO_ 352 AHB1: 8 iBAU
 SG_ CF_Ahb_SLmp : 0|2@1+ (1,0) [0|3] "" CLU
 SG_ CF_Ahb_Def : 2|2@1+ (1,0) [0|3] "" CGW
 SG_ CF_Ahb_Act : 4|2@1+ (1,0) [0|3] "" Vector__XXX
 SG_ CF_Ahb_Diag : 6|1@1+ (1,0) [0|1] "" Vector__XXX
 SG_ CF_Ahb_WLmp : 7|1@1+ (1,0) [0|1] "" CLU
 SG_ CR_Ahb_StDep_mm : 8|16@1- (0.1,0) [-3276.8|3276.7] "mm" Vector__XXX
 SG_ CF_Ahb_SnsFail : 24|1@1+ (1,0) [0|1] "" Vector__XXX
 SG_ CF_Ahb_PedalCalStat : 25|1@1+ (1,0) [0|1] "" Vector__XXX
 SG_ CF_Ahb_Bzzr : 26|1@1+ (1,0) [0|1] "" Vector__XXX
 SG_ CF_Ahb_ChkSum : 56|8@1+ (1,0) [0|255] "" Vector__XXX

BO_ 1191 4a7MFC: 8 XXX
 SG_ PAINT1 : 0|1@0+ (1,0) [0|1] "" XXX

BO_ 1162 BCA11: 8 BCW
 SG_ CF_BCA_State : 16|3@1+ (1,0) [0|7] "" CLU,iBAU
 SG_ CF_BCA_Warning : 19|2@1+ (1,0) [0|3] "" CLU,iBAU
 SG_ AliveCounter : 21|4@1+ (1,0) [0|15] "" CLU,iBAU
 SG_ RCCA_Brake_Command : 29|1@1+ (1,0) [0|1] "" iBAU
 SG_ Check_Sum : 56|8@1+ (1,0) [0|16] "" iBAU

BO_ 1136 P_STS: 6 CGW
 SG_ HCU1_STS : 6|2@1+ (1,0) [0|3] "" BCW,EPB,FCA,MDPS,SCC,iBAU
 SG_ HCU5_STS : 8|2@1+ (1,0) [0|3] "" EPB,FCA,MDPS,iBAU

BO_ 304 YRS11: 8 ACU
 SG_ CR_Yrs_Yr : 0|16@1+ (0.005,-163.84) [-163.84|163.83] "deg/s" CGW,iBAU
 SG_ CR_Yrs_LatAc : 16|16@1+ (0.000127465,-4.17677312) [-4.17677312|4.17651819] "g" iBAU
 SG_ CF_Yrs_YrStat : 32|4@1+ (1,0) [0|15] "" iBAU
 SG_ CF_Yrs_LatAcStat : 36|4@1+ (1,0) [0|15] "" iBAU
 SG_ CF_Yrs_MCUStat : 40|4@1+ (1,0) [0|15] "" iBAU
 SG_ CR_Yrs_MsgCnt1 : 48|4@1+ (1,0) [0|15] "" iBAU
 SG_ CR_Yrs_Crc1 : 56|8@1+ (1,0) [0|255] "" iBAU

BO_ 320 YRS12: 8 ACU
 SG_ CF_Yrs_LongAcStat : 16|4@1+ (1,0) [0|15] "" iBAU
 SG_ CF_IMU_ResetStat : 20|4@1+ (1,0) [0|15] "" iBAU
 SG_ YRS_Temp : 24|8@1+ (1,-68) [-68|187] "" iBAU
 SG_ YRS_TempStat : 32|4@1+ (1,0) [0|15] "" iBAU
 SG_ CF_Yrs_Type : 36|4@1+ (1,0) [0|15] "" iBAU
 SG_ CR_Yrs_MsgCnt2 : 48|4@1+ (1,0) [0|15] "" iBAU
 SG_ CR_Yrs_Crc2 : 56|8@1+ (1,0) [0|255] "" iBAU
 SG_ CR_Yrs_LongAc : 0|16@1+ (0.000127465,-4.17677312) [-4.17677312|4.17651819] "g" CGW,iBAU

BO_ 1173 YRS13: 8 ACU
 SG_ YRS_SeralNo : 16|48@1+ (1,0) [0|281474976710655] "" iBAU

BO_ 870 366_EMS: 8 EMS
 SG_ N : 7|16@0+ (1,0.25) [0|16383.75] "rpm" XXX
 SG_ EMS_Related : 23|16@0+ (1,0) [0|65535] "" XXX
 SG_ TQFR : 39|8@0+ (0.390625,0) [0|99.6094] "%" XXX
 SG_ VS : 40|8@1+ (1,0) [0|255] "km/h" MDPS
 SG_ SWI_IGK : 48|1@0+ (1,0) [0|1] "" XXX

BO_ 854 356: 8 XXX
 SG_ PAINT1 : 32|1@0+ (1,0) [0|1] "" XXX
 SG_ PAINT2 : 34|2@0+ (1,0) [0|1] "" XXX
 SG_ PAINT3 : 36|2@0+ (1,0) [0|3] "" XXX
 SG_ PAINT4 : 38|1@0+ (1,0) [0|1] "" XXX

BO_ 1042 ICM_412h: 8 ICM
 SG_ T_Outside_input : 0|9@0+ (0.01,0) [0|5] "V" Vector__XXX
 SG_ WarningSoundOutput_1Group : 5|1@0+ (1,0) [0|1] "" Vector__XXX
 SG_ WarningSoundOutput_2Group : 6|1@0+ (1,0) [0|1] "" Vector__XXX
 SG_ WarningSoundOutput_3Group : 7|1@0+ (1,0) [0|1] "" Vector__XXX
 SG_ TRIP_A_DT_Display_clock : 22|7@0+ (1,0) [0|99] "clock" Vector__XXX
 SG_ TRIP_A_DT_Display_minute : 29|6@0+ (1,0) [0|59] "minute" Vector__XXX
 SG_ TRIP_B_DT_Display_clock : 38|7@0+ (1,0) [0|99] "clock" Vector__XXX
 SG_ TRIP_B_DT_Display_minute : 45|6@0+ (1,0) [0|59] "minute" Vector__XXX
 SG_ PopupMessageOutput_1Level : 48|1@0+ (1,0) [0|1] "" Vector__XXX
 SG_ PopupMessageOutput_2Level : 49|1@0+ (1,0) [0|1] "" Vector__XXX
 SG_ PopupMessageOutput_3Level : 50|1@0+ (1,0) [0|1] "" Vector__XXX
 SG_ PopupMessageOutput_4Level : 51|1@0+ (1,0) [0|1] "" Vector__XXX
 SG_ PopupMessageOutput_5Level : 52|1@0+ (1,0) [0|1] "" Vector__XXX
 SG_ PopupMessageOutput_6Level : 53|1@0+ (1,0) [0|1] "" Vector__XXX
 SG_ PopupMessageOutput_7Level : 54|1@0+ (1,0) [0|1] "" Vector__XXX
 SG_ PopupMessageOutput_8Level : 55|1@0+ (1,0) [0|1] "" Vector__XXX

VAL_ 909 CF_VSM_Warn 2 "FCW" 3 "AEB";
############################################################################################################################################################################################################################################################################

VERSION ""  hyundai_i30_2014.dbc

NS_ :

BS_:

BU_: XXX

BO_ 160 EngFrzFrm1: 8 XXX
    SG_ PID_04h : 0|8@1+ (0.392157,0) [0|100] "%" XXX
    SG_ PID_05h : 8|8@1+ (1,-40) [-40|215] "" XXX
    SG_ PID_0Ch : 16|16@1+ (0.25,0) [0|16383.8] "rpm" XXX
    SG_ PID_0Dh : 32|8@1+ (1,0) [0|255] "km/h" XXX
    SG_ PID_11h : 40|8@1+ (0.392157,0) [0|100] "%" XXX
    SG_ PID_03h : 48|16@1+ (1,0) [0|65535] "" XXX

BO_ 161 EngFrzFrm2: 8 XXX
    SG_ PID_06h : 0|8@1+ (0.78125,-100) [-100|99.22] "%" XXX
    SG_ PID_07h : 8|8@1+ (0.78125,-100) [-100|99.22] "%" XXX
    SG_ PID_08h : 16|8@1+ (0.78125,-100) [-100|99.22] "%" XXX
    SG_ PID_09h : 24|8@1+ (0.78125,-100) [-100|99.22] "%" XXX
    SG_ PID_0Bh : 32|8@1+ (1,0) [0|255] "kPa" XXX
    SG_ PID_23h : 40|16@1+ (10,0) [0|655350] "kPa" XXX

BO_ 304 YRS1: 8 XXX
    SG_ CR_Yrs_Yr : 0|16@1+ (0.005,-163.84) [-163.84|163.83] "" XXX
    SG_ CF_Yrs_SnsStat1 : 16|4@1+ (1,0) [0|15] "" XXX
    SG_ CF_Yrs_YrStat : 20|4@1+ (1,0) [0|15] "" XXX
    SG_ CR_Yrs_LatAc : 32|16@1+ (0.000127465,-4.17677) [-4.17677|4.17652] "g" XXX
    SG_ CR_Yrs_MsgCnt1 : 48|4@1+ (1,0) [0|15] "" XXX
    SG_ CF_Yrs_LatAcStat1 : 52|4@1+ (1,0) [0|15] "" XXX
    SG_ CR_Yrs_Crc1 : 56|8@1+ (1,0) [0|255] "" XXX

BO_ 305 YRS3: 8 XXX
    SG_ CR_Yrs_YawAcc : 0|16@1+ (0.125,-4096) [-4096|4095.75] "" XXX
    SG_ CF_Yrs_YawAccStat : 20|4@1+ (1,0) [0|15] "" XXX
    SG_ CR_Yrs_Ax : 32|16@1+ (0.000127465,-4.17677) [-4.17677|4.17652] "g" XXX
    SG_ CR_Yrs_MsgCnt3 : 48|4@1+ (1,0) [0|15] "" XXX
    SG_ CF_Yrs_AxStat : 52|4@1+ (1,0) [0|15] "" XXX
    SG_ CR_Yrs_Crc3 : 56|8@1+ (1,0) [0|255] "" XXX

BO_ 320 YRS2: 8 XXX
    SG_ CF_Yrs_McuStat : 0|8@1+ (1,0) [0|255] "" XXX
    SG_ CF_Yrs_SnsStat2 : 8|8@1+ (1,0) [0|255] "" XXX
    SG_ CF_Yrs_ExtSysStat : 32|8@1+ (1,0) [0|255] "" XXX
    SG_ CR_Yrs_Diag : 40|8@1+ (1,0) [0|255] "" XXX
    SG_ CR_Yrs_MsgCnt2 : 48|4@1+ (1,0) [0|15] "" XXX
    SG_ CF_Yrs_Type : 52|4@1+ (1,0) [0|15] "" XXX
    SG_ CR_Yrs_Crc2 : 56|8@1+ (1,0) [0|255] "" XXX

BO_ 357 VSM2: 8 XXX
    SG_ CR_Mdps_StrTq : 0|12@1+ (0.01,-20.48) [-20.48|20.47] "Nm" XXX
    SG_ CR_Mdps_OutTq : 12|12@1+ (0.1,-204.8) [-204.8|204.7] "" XXX
    SG_ CF_Mdps_Def : 24|1@1+ (1,0) [0|1] "" XXX
    SG_ CF_Mdps_SErr : 25|1@1+ (1,0) [0|1] "" XXX
    SG_ CF_Mdps_AliveCnt : 48|4@1+ (1,0) [0|15] "" XXX
    SG_ CF_Mdps_Chksum : 56|8@1+ (1,0) [0|255] "" XXX

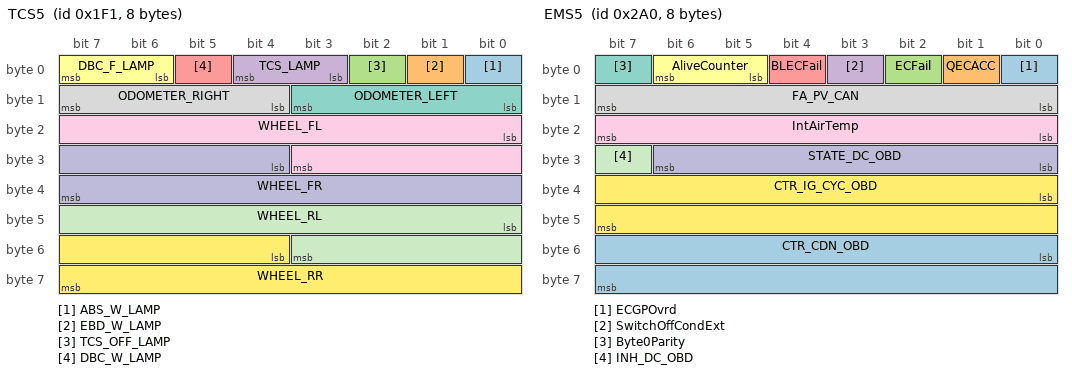
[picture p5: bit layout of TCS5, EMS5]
BO_ 497 TCS5: 8 XXX
    SG_ ABS_W_LAMP : 0|1@1+ (1,0) [0|1] "" XXX
    SG_ EBD_W_LAMP : 1|1@1+ (1,0) [0|1] "" XXX
    SG_ TCS_OFF_LAMP : 2|1@1+ (1,0) [0|1] "" XXX
    SG_ TCS_LAMP : 3|2@1+ (1,0) [0|3] "" XXX
    SG_ DBC_W_LAMP : 5|1@1+ (1,0) [0|1] "" XXX
    SG_ DBC_F_LAMP : 6|2@1+ (1,0) [0|3] "" XXX
    SG_ ODOMETER_LEFT : 8|4@1+ (1,0) [0|15] "m" XXX
    SG_ ODOMETER_RIGHT : 12|4@1+ (1,0) [0|15] "m" XXX
    SG_ WHEEL_FL : 16|12@1+ (0.125,0) [0|511.875] "km/h" XXX
    SG_ WHEEL_FR : 28|12@1+ (0.125,0) [0|511.875] "km/h" XXX
    SG_ WHEEL_RL : 40|12@1+ (0.125,0) [0|511.875] "km/h" XXX
    SG_ WHEEL_RR : 52|12@1+ (0.125,0) [0|511.875] "km/h" XXX

BO_ 544 ESP2: 8 XXX
    SG_ LAT_ACCEL : 0|11@1+ (0.01,-10.23) [-10.23|10.24] "m/s^2" XXX
    SG_ ESP2_AliveCounter_LSB : 11|3@1+ (1,0) [0|7] "" XXX
    SG_ LAT_ACCEL_STAT : 14|1@1+ (1,0) [0|1] "" XXX
    SG_ LAT_ACCEL_DIAG : 15|1@1+ (1,0) [0|1] "" XXX
    SG_ LONG_ACCEL : 16|11@1+ (0.01,-10.23) [-10.23|10.24] "m/s^2" XXX
    SG_ ESP2_AliveCounter_MSB : 27|1@1+ (1,0) [0|1] "" XXX
    SG_ ESP2_Checksum_LSB : 28|2@1+ (1,0) [0|3] "" XXX
    SG_ LONG_ACCEL_STAT : 30|1@1+ (1,0) [0|1] "" XXX
    SG_ LONG_ACCEL_DIAG : 31|1@1+ (1,0) [0|1] "" XXX
    SG_ CYL_PRES : 32|12@1+ (0.1,0) [0|409.5] "Bar" XXX
    SG_ ESP12_Checksum_MSB : 44|2@1+ (1,0) [0|3] "" XXX
    SG_ CYL_PRES_STAT : 46|1@1+ (1,0) [0|1] "" XXX
    SG_ CYL_PRESS_DIAG : 47|1@1+ (1,0) [0|1] "" XXX
    SG_ YAW_RATE : 48|13@1+ (0.01,-40.95) [-40.95|40.96] "" XXX
    SG_ CYL_PRES_FLAG : 61|1@1+ (1,0) [0|1] "" XXX
    SG_ YAW_RATE_STAT : 62|1@1+ (1,0) [0|1] "" XXX
    SG_ YAW_RATE_DIAG : 63|1@1+ (1,0) [0|1] "" XXX

BO_ 672 EMS5: 8 XXX
    SG_ ECGPOvrd : 0|1@1+ (1,0) [0|1] "" XXX
    SG_ QECACC : 1|1@1+ (1,0) [0|1] "" XXX
    SG_ ECFail : 2|1@1+ (1,0) [0|1] "" XXX
    SG_ SwitchOffCondExt : 3|1@1+ (1,0) [0|1] "" XXX
    SG_ BLECFail : 4|1@1+ (1,0) [0|1] "" XXX
    SG_ AliveCounter : 5|2@1+ (1,0) [0|3] "" XXX
    SG_ Byte0Parity : 7|1@1+ (1,0) [0|1] "" XXX
    SG_ FA_PV_CAN : 8|8@1+ (0.3906,0) [0|99.2] "%" XXX
    SG_ IntAirTemp : 16|8@1+ (0.75,-48) [-48|143.25] "" XXX
    SG_ STATE_DC_OBD : 24|7@1+ (1,0) [0|127] "" XXX
    SG_ INH_DC_OBD : 31|1@1+ (1,0) [0|1] "" XXX
    SG_ CTR_IG_CYC_OBD : 32|16@1+ (1,0) [0|65535] "" XXX
    SG_ CTR_CDN_OBD : 48|16@1+ (1,0) [0|65535] "" XXX

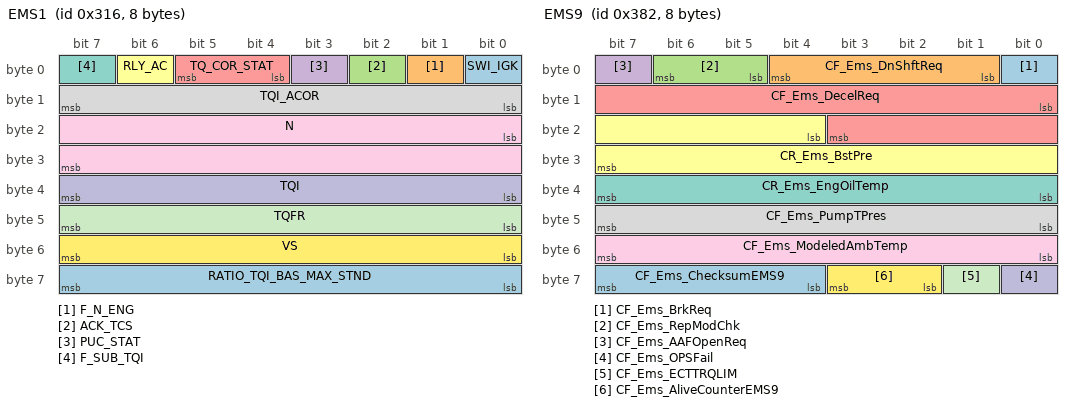
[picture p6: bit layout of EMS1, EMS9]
BO_ 790 EMS1: 8 XXX
    SG_ SWI_IGK : 0|1@1+ (1,0) [0|1] "" XXX
    SG_ F_N_ENG : 1|1@1+ (1,0) [0|1] "" XXX
    SG_ ACK_TCS : 2|1@1+ (1,0) [0|1] "" XXX
    SG_ PUC_STAT : 3|1@1+ (1,0) [0|1] "" XXX
    SG_ TQ_COR_STAT : 4|2@1+ (1,0) [0|3] "" XXX
    SG_ RLY_AC : 6|1@1+ (1,0) [0|1] "" XXX
    SG_ F_SUB_TQI : 7|1@1+ (1,0) [0|1] "" XXX
    SG_ TQI_ACOR : 8|8@1+ (0.390625,0) [0|99.6094] "%" XXX
    SG_ N : 16|16@1+ (0.25,0) [0|16383.8] "rpm" XXX
    SG_ TQI : 32|8@1+ (0.390625,0) [0|99.6094] "%" XXX
    SG_ TQFR : 40|8@1+ (0.390625,0) [0|99.6094] "%" XXX
    SG_ VS : 48|8@1+ (1,0) [0|254] "km/h" XXX
    SG_ RATIO_TQI_BAS_MAX_STND : 56|8@1+ (0.0078,0) [0|2] "" XXX

BO_ 848 FATC: 8 XXX
    SG_ CR_Fatc_TqAcnOut : 0|8@1+ (0.2,0) [0|50.8] "Nm" XXX
    SG_ CF_Fatc_AcnRqSwi : 8|1@1+ (1,0) [0|1] "" XXX
    SG_ CF_Fatc_AcnCltEnRq : 9|1@1+ (1,0) [0|1] "" XXX
    SG_ CF_Fatc_EcvFlt : 10|1@1+ (1,0) [0|1] "" XXX
    SG_ CF_Fatc_BlwrOn : 11|1@1+ (1,0) [0|1] "" XXX
    SG_ CF_FATC_Iden : 12|2@1+ (1,0) [0|3] "" XXX
    SG_ CF_Fatc_BlwrMax : 14|1@1+ (1,0) [0|1] "" XXX
    SG_ CF_Fatc_EngStartReq : 15|1@1+ (1,0) [0|1] "" XXX
    SG_ CF_Fatc_IsgStopReq : 16|1@1+ (1,0) [0|1] "" XXX
    SG_ CF_Fatc_CtrInf : 17|3@1+ (1,0) [0|7] "" XXX
    SG_ CF_Fatc_MsgCnt : 20|4@1+ (1,0) [0|15] "" XXX
    SG_ CR_Fatc_OutTemp : 24|8@1+ (0.5,-40) [-40|60] "" XXX
    SG_ CR_Fatc_OutTempSns : 32|8@1+ (0.5,-40) [-40|60] "" XXX
    SG_ CF_Fatc_Compload : 40|3@1+ (1,0) [0|7] "" XXX
    SG_ CF_Fatc_ActiveEco : 43|1@1+ (1,0) [0|1] "" XXX
    SG_ CF_Fatc_AutoActivation : 44|1@1+ (1,0) [0|1] "" XXX
    SG_ CF_Fatc_DefSw : 45|1@1+ (1,0) [0|1] "" XXX
    SG_ CF_Fatc_PtcRlyStat : 46|1@1+ (1,0) [0|1] "" XXX
    SG_ CF_Fatc_ChkSum : 56|8@1+ (1,0) [0|255] "" XXX

BO_ 880 TCU3: 8 XXX
    SG_ N_TGT_LUP : 0|8@1+ (10,500) [500|3040] "rpm" XXX
    SG_ SLOPE_TCU : 8|6@1+ (0.5,-16) [-16|15.5] "%" XXX
    SG_ CF_Tcu_InhCda : 14|1@1+ (1,0) [0|1] "" XXX
    SG_ CF_Tcu_IsgInhib : 15|1@1+ (1,0) [0|1] "" XXX
    SG_ CF_Tcu_BkeOnReq : 16|2@1+ (1,0) [0|3] "" XXX
    SG_ CF_Tcu_NCStat : 18|2@1+ (1,0) [0|3] "" XXX
    SG_ CF_Tcu_TarGr : 20|4@1+ (1,0) [0|15] "" XXX
    SG_ CF_Tcu_ShfPatt : 24|4@1+ (1,0) [0|15] "" XXX
    SG_ CF_Tcu_InhVis : 28|1@1+ (1,0) [0|1] "" XXX
    SG_ CF_Tcu_PRelReq : 29|1@1+ (1,0) [0|1] "" XXX
    SG_ CF_Tcu_ITPhase : 30|1@1+ (1,0) [0|1] "" XXX
    SG_ CF_Tcu_ActEcoRdy : 31|1@1+ (1,0) [0|1] "" XXX
    SG_ CF_Tcu_TqGrdLim : 32|8@1+ (10,0) [0|2540] "Nm/s" XXX
    SG_ CR_Tcu_IsgTgtRPM : 40|8@1+ (20,0) [0|3500] "rpm" XXX
    SG_ TQI_TCU_INC : 48|8@1+ (0.390625,0) [0|99.6094] "%" XXX
    SG_ CF_Tcu_SbwPInfo : 56|1@1+ (1,0) [0|1] "" XXX
    SG_ CF_Tcu_SptRdy : 57|1@1+ (1,0) [0|1] "" XXX
    SG_ CF_Tcu_Alive3 : 58|2@1+ (1,0) [0|3] "" XXX
    SG_ CF_Tcu_ChkSum3 : 60|4@1+ (1,0) [0|15] "" XXX

BO_ 898 EMS9: 8 XXX
    SG_ CF_Ems_BrkReq : 0|1@1+ (1,0) [0|1] "" XXX
    SG_ CF_Ems_DnShftReq : 1|4@1+ (1,0) [0|14] "" XXX
    SG_ CF_Ems_RepModChk : 5|2@1+ (1,0) [0|3] "" XXX
    SG_ CF_Ems_AAFOpenReq : 7|1@1+ (1,0) [0|1] "" XXX
    SG_ CF_Ems_DecelReq : 8|12@1+ (0.001,-4.094) [-4.094|0] "m/s^2" XXX
    SG_ CR_Ems_BstPre : 20|12@1+ (1.322,0) [0|4094] "hPa" XXX
    SG_ CR_Ems_EngOilTemp : 32|8@1+ (0.75,-40) [0|254] "" XXX
    SG_ CF_Ems_PumpTPres : 40|8@1+ (3.13725,0) [0|800] "kPa" XXX
    SG_ CF_Ems_ModeledAmbTemp : 48|8@1+ (0.5,-41) [-40|60] "" XXX
    SG_ CF_Ems_OPSFail : 56|1@1+ (1,0) [0|1] "" XXX
    SG_ CF_Ems_ECTTRQLIM : 57|1@1+ (1,0) [0|1] "" XXX
    SG_ CF_Ems_AliveCounterEMS9 : 58|2@1+ (1,0) [0|3] "" XXX
    SG_ CF_Ems_ChecksumEMS9 : 60|4@1+ (1,0) [0|15] "" XXX

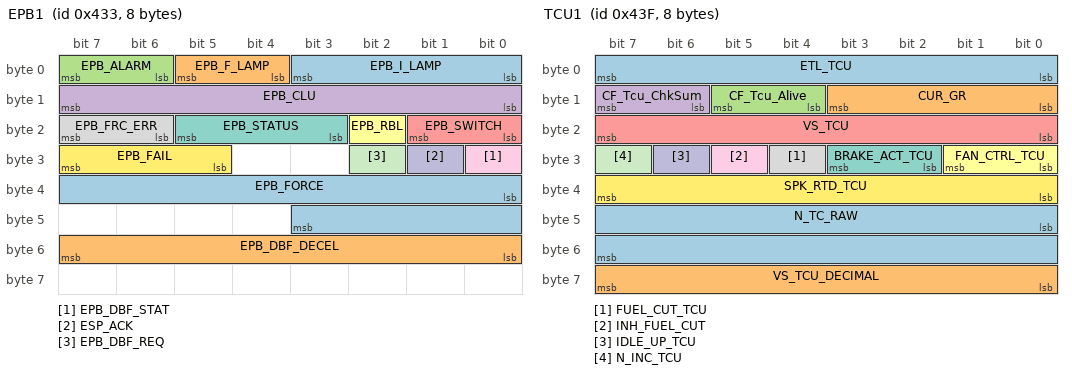
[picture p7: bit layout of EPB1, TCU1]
BO_ 1075 EPB1: 8 XXX
    SG_ EPB_I_LAMP : 0|4@1+ (1,0) [0|15] "" XXX
    SG_ EPB_F_LAMP : 4|2@1+ (1,0) [0|3] "" XXX
    SG_ EPB_ALARM : 6|2@1+ (1,0) [0|3] "" XXX
    SG_ EPB_CLU : 8|8@1+ (1,0) [0|255] "" XXX
    SG_ EPB_SWITCH : 16|2@1+ (1,0) [0|3] "" XXX
    SG_ EPB_RBL : 18|1@1+ (1,0) [0|1] "" XXX
    SG_ EPB_STATUS : 19|3@1+ (1,0) [0|7] "" XXX
    SG_ EPB_FRC_ERR : 22|2@1+ (1,0) [0|3] "" XXX
    SG_ EPB_DBF_STAT : 24|1@1+ (1,0) [0|1] "" XXX
    SG_ ESP_ACK : 25|1@1+ (1,0) [0|1] "" XXX
    SG_ EPB_DBF_REQ : 26|1@1+ (1,0) [0|1] "" XXX
    SG_ EPB_FAIL : 29|3@1+ (1,0) [0|7] "" XXX
    SG_ EPB_FORCE : 32|12@1+ (1,-1000) [-1000|3000] "" XXX
    SG_ EPB_DBF_DECEL : 48|8@1+ (0.01,0) [0|2.54] "g" XXX

BO_ 1087 TCU1: 8 XXX
    SG_ ETL_TCU : 0|8@1+ (2,0) [0|508] "Nm" XXX
    SG_ CUR_GR : 8|4@1+ (1,0) [0|15] "" XXX
    SG_ CF_Tcu_Alive : 12|2@1+ (1,0) [0|3] "" XXX
    SG_ CF_Tcu_ChkSum : 14|2@1+ (1,0) [0|3] "" XXX
    SG_ VS_TCU : 16|8@1+ (1,0) [0|254] "km/h" XXX
    SG_ FAN_CTRL_TCU : 24|2@1+ (1,0) [0|3] "" XXX
    SG_ BRAKE_ACT_TCU : 26|2@1+ (1,0) [0|3] "" XXX
    SG_ FUEL_CUT_TCU : 28|1@1+ (1,0) [0|1] "" XXX
    SG_ INH_FUEL_CUT : 29|1@1+ (1,0) [0|1] "" XXX
    SG_ IDLE_UP_TCU : 30|1@1+ (1,0) [0|1] "" XXX
    SG_ N_INC_TCU : 31|1@1+ (1,0) [0|1] "" XXX
    SG_ SPK_RTD_TCU : 32|8@1+ (0.375,-23.625) [-15|15] "" XXX
    SG_ N_TC_RAW : 40|16@1+ (0.25,0) [0|16383.5] "rpm" XXX
    SG_ VS_TCU_DECIMAL : 56|8@1+ (0.0078125,0) [0|0.992188] "km/h" XXX

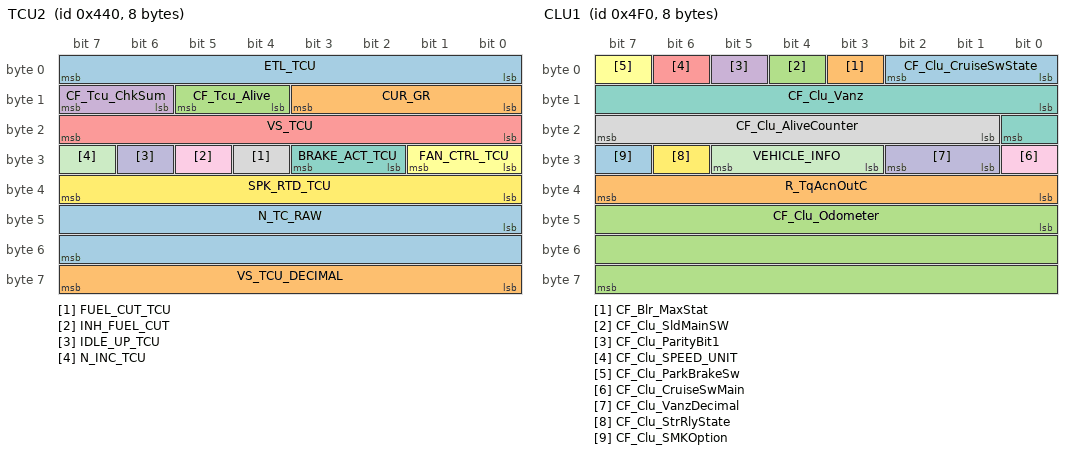
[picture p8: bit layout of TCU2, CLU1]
BO_ 1088 TCU2: 8 XXX
    SG_ ETL_TCU : 0|8@1+ (2,0) [0|508] "Nm" XXX
    SG_ CUR_GR : 8|4@1+ (1,0) [0|15] "" XXX
    SG_ CF_Tcu_Alive : 12|2@1+ (1,0) [0|3] "" XXX
    SG_ CF_Tcu_ChkSum : 14|2@1+ (1,0) [0|3] "" XXX
    SG_ VS_TCU : 16|8@1+ (1,0) [0|254] "km/h" XXX
    SG_ FAN_CTRL_TCU : 24|2@1+ (1,0) [0|3] "" XXX
    SG_ BRAKE_ACT_TCU : 26|2@1+ (1,0) [0|3] "" XXX
    SG_ FUEL_CUT_TCU : 28|1@1+ (1,0) [0|1] "" XXX
    SG_ INH_FUEL_CUT : 29|1@1+ (1,0) [0|1] "" XXX
    SG_ IDLE_UP_TCU : 30|1@1+ (1,0) [0|1] "" XXX
    SG_ N_INC_TCU : 31|1@1+ (1,0) [0|1] "" XXX
    SG_ SPK_RTD_TCU : 32|8@1+ (0.375,-23.625) [-15|15] "" XXX
    SG_ N_TC_RAW : 40|16@1+ (0.25,0) [0|16383.5] "rpm" XXX
    SG_ VS_TCU_DECIMAL : 56|8@1+ (0.0078125,0) [0|0.992188] "km/h" XXX

BO_ 1200 WHL_SPD: 8 XXX
    SG_ WHL_SPD_FL : 0|14@1+ (0.03125,0) [0|511.969] "km/h" XXX
    SG_ WHL_SPD_FR : 16|14@1+ (0.03125,0) [0|511.969] "km/h" XXX
    SG_ WHL_SPD_RL : 32|14@1+ (0.03125,0) [0|511.969] "km/h" XXX
    SG_ WHL_SPD_RR : 48|14@1+ (0.03125,0) [0|511.969] "km/h" XXX

BO_ 1201 WHL_PUL: 8 XXX
    SG_ WHL_PUL_FL : 0|8@1+ (0.5,0) [0|127.5] "pulse count" XXX
    SG_ WHL_PUL_FR : 8|8@1+ (0.5,0) [0|127.5] "pulse count" XXX
    SG_ WHL_PUL_RL : 16|8@1+ (0.5,0) [0|127.5] "pulse count" XXX
    SG_ WHL_PUL_RR : 24|8@1+ (0.5,0) [0|127.5] "pulse count" XXX
    SG_ WHL_DIR_FL : 32|2@1+ (1,0) [0|3] "" XXX
    SG_ WHL_DIR_FR : 34|2@1+ (1,0) [0|3] "" XXX
    SG_ WHL_DIR_RL : 36|2@1+ (1,0) [0|3] "" XXX
    SG_ WHL_DIR_RR : 38|2@1+ (1,0) [0|3] "" XXX
    SG_ WHL_PUL_Chksum : 56|8@1+ (1,0) [0|255] "" XXX

BO_ 1264 CLU1: 8 XXX
    SG_ CF_Clu_CruiseSwState : 0|3@1+ (1,0) [0|7] "" XXX
    SG_ CF_Blr_MaxStat : 3|1@1+ (1,0) [0|1] "" XXX
    SG_ CF_Clu_SldMainSW : 4|1@1+ (1,0) [0|1] "" XXX
    SG_ CF_Clu_ParityBit1 : 5|1@1+ (1,0) [0|1] "pulse count" XXX
    SG_ CF_Clu_SPEED_UNIT : 6|1@1+ (1,0) [0|1] "" XXX
    SG_ CF_Clu_ParkBrakeSw : 7|1@1+ (1,0) [0|1] "" XXX
    SG_ CF_Clu_Vanz : 8|9@1+ (0.5,0) [0|255.5] "km/h or MPH" XXX
    SG_ CF_Clu_AliveCounter : 17|7@1+ (1,0) [0|127] "" XXX
    SG_ CF_Clu_CruiseSwMain : 24|1@1+ (1,0) [0|1] "" XXX
    SG_ CF_Clu_VanzDecimal : 25|2@1+ (1,0) [0|0.375] "" XXX
    SG_ VEHICLE_INFO : 27|3@1+ (1,0) [0|7] "" XXX
    SG_ CF_Clu_StrRlyState : 30|1@1+ (1,0) [0|1] "" XXX
    SG_ CF_Clu_SMKOption : 31|1@1+ (1,0) [0|1] "" XXX
    SG_ R_TqAcnOutC : 32|8@1+ (1,0) [0|51] "Nm" XXX
    SG_ CF_Clu_Odometer : 40|24@1+ (0.1,0) [0|1.67772e+006] "km" XXX

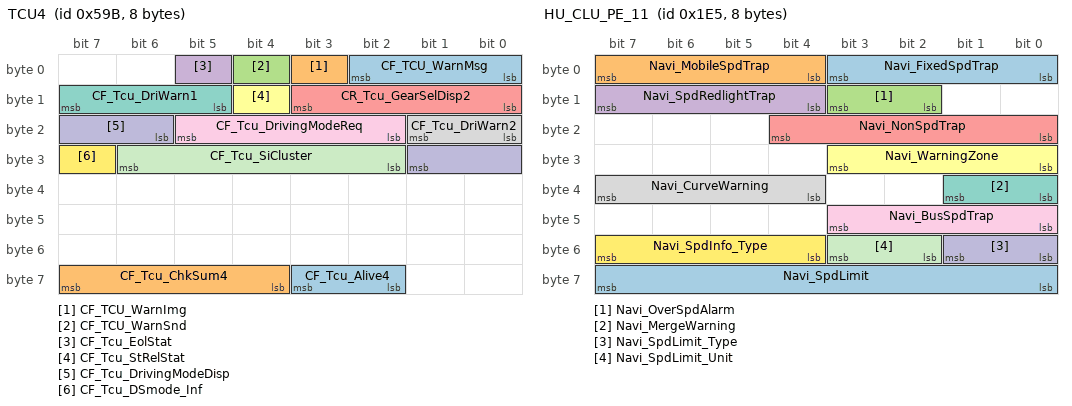
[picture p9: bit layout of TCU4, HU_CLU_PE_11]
BO_ 1435 TCU4: 8 XXX
    SG_ CF_TCU_WarnMsg : 0|3@1+ (1,0) [0|7] "" XXX
    SG_ CF_TCU_WarnImg : 3|1@1+ (1,0) [0|1] "" XXX
    SG_ CF_TCU_WarnSnd : 4|1@1+ (1,0) [0|1] "" XXX
    SG_ CF_Tcu_EolStat : 5|1@1+ (1,0) [0|1] "" XXX
    SG_ CR_Tcu_GearSelDisp2 : 8|4@1+ (1,0) [0|15] "" XXX
    SG_ CF_Tcu_StRelStat : 12|1@1+ (1,0) [0|1] "" XXX
    SG_ CF_Tcu_DriWarn1 : 13|3@1+ (1,0) [0|7] "" XXX
    SG_ CF_Tcu_DriWarn2 : 16|2@1+ (1,0) [0|3] "" XXX
    SG_ CF_Tcu_DrivingModeReq : 18|4@1+ (1,0) [0|0] "" XXX
    SG_ CF_Tcu_DrivingModeDisp : 22|4@1+ (1,0) [0|0] "" XXX
    SG_ CF_Tcu_SiCluster : 26|5@1+ (1,0) [0|0] "" XXX
    SG_ CF_Tcu_DSmode_Inf : 31|1@1+ (1,0) [0|1] "" XXX
    SG_ CF_Tcu_Alive4 : 58|2@1+ (1,0) [0|3] "" XXX
    SG_ CF_Tcu_ChkSum4 : 60|4@1+ (1,0) [0|15] "" XXX

BO_ 1508 MDPS1: 8 XXX
    SG_ CF_Mdps_WLmp : 1|2@1+ (1,0) [0|3] "" XXX
    SG_ CF_Mdps_ALTRequest : 5|1@1+ (1,0) [0|1] "" XXX
    SG_ CF_Mdps_Flex : 8|3@1+ (1,0) [0|7] "" XXX
    SG_ CF_Mdps_FlexDisp : 11|1@1+ (1,0) [0|1] "" XXX
    SG_ CF_Mdps_CurrMode : 12|2@1+ (1,0) [0|3] "" XXX

BO_ 1680 CLU2: 8 XXX
    SG_ CF_Clu_IGNSw : 0|3@1+ (1,0) [0|7] "" XXX
    SG_ RKE_CMD : 3|3@1+ (1,0) [0|7] "" XXX
    SG_ CF_Clu_DrvDrSw : 6|2@1+ (1,0) [0|3] "" XXX
    SG_ CF_Clu_DrvKeyLockSw : 8|1@1+ (1,0) [0|1] "" XXX
    SG_ CF_Clu_DrvKeyUnlockSw : 9|1@1+ (1,0) [0|1] "" XXX
    SG_ PIC_Lock : 10|3@1+ (1,0) [0|7] "" XXX
    SG_ PIC_Unlock : 13|3@1+ (1,0) [0|7] "" XXX
    SG_ CF_Clu_DrvSeatBeltSw : 16|2@1+ (1,0) [0|3] "" XXX
    SG_ CF_Clu_TrunkTgSw : 18|2@1+ (1,0) [0|3] "" XXX
    SG_ CF_Clu_AstSeatBeltSw : 20|2@1+ (1,0) [0|3] "" XXX
    SG_ CF_Clu_HoodSw : 22|2@1+ (1,0) [0|3] "" XXX
    SG_ CF_Clu_TurnSigLh : 24|1@1+ (1,0) [0|1] "" XXX
    SG_ CF_Clu_TurnSigRh : 25|1@1+ (1,0) [0|1] "" XXX
    SG_ CF_Clu_LdwsLkasSW : 26|1@1+ (1,0) [0|1] "" XXX
    SG_ CF_Clu_WiperIntT : 27|3@1+ (1,0) [0|7] "" XXX
    SG_ CF_Clu_WiperIntSW : 30|1@1+ (1,0) [0|1] "" XXX
    SG_ CF_Clu_WiperLow : 31|1@1+ (1,0) [0|1] "" XXX
    SG_ CF_Clu_WiperHigh : 32|1@1+ (1,0) [0|1] "" XXX
    SG_ CF_Clu_WiperAuto : 33|1@1+ (1,0) [0|1] "" XXX
    SG_ CF_Clu_RainSnsStat : 34|3@1+ (1,0) [0|7] "" XXX
    SG_ CF_Clu_HeadLampLow : 37|1@1+ (1,0) [0|1] "" XXX
    SG_ CF_Clu_HeadLampHigh : 38|1@1+ (1,0) [0|1] "" XXX
    SG_ CF_Clu_AltLStatus : 39|1@1+ (1,0) [0|1] "" XXX
    SG_ CF_Clu_EcoDriveInf : 40|3@1+ (1,0) [0|7] "" XXX
    SG_ CF_Clu_SwiGearR : 43|2@1+ (1,0) [0|3] "" XXX
    SG_ CF_Clu_SWL_Stat : 45|3@1+ (1,0) [0|7] "" XXX
    SG_ CF_Clu_ActiveEcoSW : 48|1@1+ (1,0) [0|1] "" XXX
    SG_ CF_Clu_HazardSW : 49|1@1+ (1,0) [0|1] "" XXX
    SG_ CF_Clu_AliveCnt2 : 50|4@1+ (1,0) [0|15] "" XXX
    SG_ CF_Clu_AstDrSw : 54|2@1+ (1,0) [0|3] "" XXX
    SG_ CF_Clu_LkasDispMode : 56|2@1+ (1,0) [0|3] "" XXX
    SG_ CF_Clu_AutoLightLevel : 58|2@1+ (1,0) [0|3] "" XXX
    SG_ CF_Clu_SunRoofOpenState : 60|1@1+ (1,0) [0|1] "" XXX
####################################################################################################################################################################################################################################################

VERSION ""  hyundai_2015_mcan.dbc

NS_ :

BS_:

BU_: CLOCK HUD H_U DATC CCP KMA_TMU CUBIS TMU IPM RSE_R RRC CGW RSE_L AMP EDT SWRC IBOX CLU FHCU ASD MON AVM KBD

BO_ 3221225472 VECTOR__INDEPENDENT_SIG_MSG: 0 Vector__XXX
 SG_ C_WHEEL_FL : 0|12@0+ (1,0) [0|0] "" Vector__XXX
 SG_ C_WHEEL_FR : 0|12@0+ (1,0) [0|0] "" Vector__XXX
 SG_ C_WHEEL_RL : 0|12@0+ (1,0) [0|0] "" Vector__XXX
 SG_ C_WHEEL_RR : 0|12@0+ (1,0) [0|0] "" Vector__XXX

BO_ 2046 TP_EDT_AMP: 8 EDT
 SG_ Byte0_TCP_7FE : 7|8@0+ (1,0) [0|0] ""  AMP
 SG_ Byte1_Data_7FE : 15|8@0+ (1,0) [0|0] ""  AMP
 SG_ Byte2_Data_7FE : 23|8@0+ (1,0) [0|0] ""  AMP
 SG_ Byte3_Data_7FE : 31|8@0+ (1,0) [0|0] ""  AMP
 SG_ Byte4_Data_7FE : 39|8@0+ (1,0) [0|0] ""  AMP
 SG_ Byte5_Data_7FE : 47|8@0+ (1,0) [0|0] ""  AMP
 SG_ Byte6_Data_7FE : 55|8@0+ (1,0) [0|0] ""  AMP
 SG_ Byte7_Data_7FE : 63|8@0+ (1,0) [0|0] ""  AMP

BO_ 251 HU_TMU_E_02: 8 H_U
 SG_ HU_GPS_Year : 7|8@0+ (1,0) [0|0] ""  CUBIS,TMU
 SG_ HU_GPS_Month : 15|8@0+ (1,0) [0|0] ""  CUBIS,TMU
 SG_ HU_GPS_Day : 23|8@0+ (1,0) [0|0] ""  CUBIS,TMU
 SG_ HU_GPS_Hour : 31|8@0+ (1,0) [0|0] ""  CUBIS,TMU
 SG_ HU_GPS_Minute : 39|8@0+ (1,0) [0|0] ""  CUBIS,TMU
 SG_ HU_GPS_Second : 47|8@0+ (1,0) [0|0] ""  CUBIS,TMU

BO_ 250 HU_TMU_E_01: 8 H_U
 SG_ HU_VoiceRecCom : 2|3@0+ (1,0) [0|0] ""  TMU
 SG_ HU_LangChgCom : 5|3@0+ (1,0) [0|0] ""  TMU
 SG_ HU_CallEndCmd : 9|2@0+ (1,0) [0|0] ""  TMU
 SG_ HU_ServiceReqtID : 13|4@0+ (1,0) [0|0] ""  TMU
 SG_ HU_MicReqCmd : 15|2@0+ (1,0) [0|0] ""  TMU
 SG_ HU_SeviceAction : 18|3@0+ (1,0) [0|0] ""  TMU
 SG_ HU_eCallStatus : 20|2@0+ (1,0) [0|0] ""  TMU

BO_ 1269 TP_CLU_ANDAUTO_HU: 8 CLU
 SG_ Byte0_TCP_4F5 : 7|8@0+ (1,0) [0|0] ""  H_U
 SG_ Byte1_Data_4F5 : 15|8@0+ (1,0) [0|0] ""  H_U
 SG_ Byte2_Data_4F5 : 23|8@0+ (1,0) [0|0] ""  H_U
 SG_ Byte3_Data_4F5 : 31|8@0+ (1,0) [0|0] ""  H_U
 SG_ Byte4_Data_4F5 : 39|8@0+ (1,0) [0|0] ""  H_U
 SG_ Byte5_Data_4F5 : 47|8@0+ (1,0) [0|0] ""  H_U
 SG_ Byte6_Data_4F5 : 55|8@0+ (1,0) [0|0] ""  H_U
 SG_ Byte7_Data_4F5 : 63|8@0+ (1,0) [0|0] ""  H_U

BO_ 1267 TP_CLU_CARPLAY_HU: 8 CLU
 SG_ Byte0_TCP_4F3 : 7|8@0+ (1,0) [0|0] ""  H_U
 SG_ Byte1_Data_4F3 : 15|8@0+ (1,0) [0|0] ""  H_U
 SG_ Byte2_Data_4F3 : 23|8@0+ (1,0) [0|0] ""  H_U
 SG_ Byte3_Data_4F3 : 31|8@0+ (1,0) [0|0] ""  H_U
 SG_ Byte4_Data_4F3 : 39|8@0+ (1,0) [0|0] ""  H_U
 SG_ Byte5_Data_4F3 : 47|8@0+ (1,0) [0|0] ""  H_U
 SG_ Byte6_Data_4F3 : 55|8@0+ (1,0) [0|0] ""  H_U
 SG_ Byte7_Data_4F3 : 63|8@0+ (1,0) [0|0] ""  H_U

BO_ 1266 TP_HU_CARPLAY_CLU: 8 H_U
 SG_ Byte0_TCP_4F2 : 7|8@0+ (1,0) [0|0] ""  CLU
 SG_ Byte1_Data_4F2 : 15|8@0+ (1,0) [0|0] ""  CLU
 SG_ Byte2_Data_4F2 : 23|8@0+ (1,0) [0|0] ""  CLU
 SG_ Byte3_Data_4F2 : 31|8@0+ (1,0) [0|0] ""  CLU
 SG_ Byte4_Data_4F2 : 39|8@0+ (1,0) [0|0] ""  CLU
 SG_ Byte5_Data_4F2 : 47|8@0+ (1,0) [0|0] ""  CLU
 SG_ Byte6_Data_4F2 : 55|8@0+ (1,0) [0|0] ""  CLU
 SG_ Byte7_Data_4F2 : 63|8@0+ (1,0) [0|0] ""  CLU

BO_ 1263 TP_CLU_IBOX_HU: 8 CLU
 SG_ Byte0_TCP_4EF : 7|8@0+ (1,0) [0|0] ""  H_U
 SG_ Byte1_Data_4EF : 15|8@0+ (1,0) [0|0] ""  H_U
 SG_ Byte2_Data_4EF : 23|8@0+ (1,0) [0|0] ""  H_U
 SG_ Byte3_Data_4EF : 31|8@0+ (1,0) [0|0] ""  H_U
 SG_ Byte4_Data_4EF : 39|8@0+ (1,0) [0|0] ""  H_U
 SG_ Byte5_Data_4EF : 47|8@0+ (1,0) [0|0] ""  H_U
 SG_ Byte6_Data_4EF : 55|8@0+ (1,0) [0|0] ""  H_U
 SG_ Byte7_Data_4EF : 63|8@0+ (1,0) [0|0] ""  H_U

BO_ 1262 TP_HU_IBOX_CLU: 8 H_U
 SG_ Byte0_TCP_4EE : 7|8@0+ (1,0) [0|0] ""  CLU
 SG_ Byte1_Data_4EE : 15|8@0+ (1,0) [0|0] ""  CLU
 SG_ Byte2_Data_4EE : 23|8@0+ (1,0) [0|0] ""  CLU
 SG_ Byte3_Data_4EE : 31|8@0+ (1,0) [0|0] ""  CLU
 SG_ Byte4_Data_4EE : 39|8@0+ (1,0) [0|0] ""  CLU
 SG_ Byte5_Data_4EE : 47|8@0+ (1,0) [0|0] ""  CLU
 SG_ Byte6_Data_4EE : 55|8@0+ (1,0) [0|0] ""  CLU
 SG_ Byte7_Data_4EE : 63|8@0+ (1,0) [0|0] ""  CLU

BO_ 1261 TP_CLU_DLNA_HU: 8 CLU
 SG_ Byte0_TCP_4ED : 7|8@0+ (1,0) [0|0] ""  H_U
 SG_ Byte1_Data_4ED : 15|8@0+ (1,0) [0|0] ""  H_U
 SG_ Byte2_Data_4ED : 23|8@0+ (1,0) [0|0] ""  H_U
 SG_ Byte3_Data_4ED : 31|8@0+ (1,0) [0|0] ""  H_U
 SG_ Byte4_Data_4ED : 39|8@0+ (1,0) [0|0] ""  H_U
 SG_ Byte5_Data_4ED : 47|8@0+ (1,0) [0|0] ""  H_U
 SG_ Byte6_Data_4ED : 55|8@0+ (1,0) [0|0] ""  H_U
 SG_ Byte7_Data_4ED : 63|8@0+ (1,0) [0|0] ""  H_U

BO_ 1260 TP_HU_DLNA_CLU: 8 H_U
 SG_ Byte0_TCP_4EC : 7|8@0+ (1,0) [0|0] ""  CLU
 SG_ Byte1_Data_4EC : 15|8@0+ (1,0) [0|0] ""  CLU
 SG_ Byte2_Data_4EC : 23|8@0+ (1,0) [0|0] ""  CLU
 SG_ Byte3_Data_4EC : 31|8@0+ (1,0) [0|0] ""  CLU
 SG_ Byte4_Data_4EC : 39|8@0+ (1,0) [0|0] ""  CLU
 SG_ Byte5_Data_4EC : 47|8@0+ (1,0) [0|0] ""  CLU
 SG_ Byte6_Data_4EC : 55|8@0+ (1,0) [0|0] ""  CLU
 SG_ Byte7_Data_4EC : 63|8@0+ (1,0) [0|0] ""  CLU

BO_ 491 GW_DDM_PE: 8 CLU
 SG_ C_DRVDoorStatus : 1|2@0+ (1,0) [0|0] ""  AMP,ASD,AVM,CCP,CGW,CLOCK,CUBIS,DATC,EDT,FHCU,HUD,H_U,IBOX,IPM,KBD,KMA_TMU,MON,RRC,RSE_L,RSE_R,SWRC,TMU
 SG_ C_ASTDoorStatus : 3|2@0+ (1,0) [0|0] ""  AMP,ASD,AVM,CCP,CGW,CLOCK,CUBIS,DATC,EDT,FHCU,HUD,H_U,IBOX,IPM,KBD,KMA_TMU,MON,RRC,RSE_L,RSE_R,SWRC,TMU
 SG_ C_RLDoorStatus : 5|2@0+ (1,0) [0|0] ""  AMP,ASD,AVM,CCP,CGW,CLOCK,CUBIS,DATC,EDT,FHCU,HUD,H_U,IBOX,IPM,KBD,KMA_TMU,MON,RRC,RSE_L,RSE_R,SWRC,TMU
 SG_ C_RRDoorStatus : 7|2@0+ (1,0) [0|0] ""  AMP,ASD,AVM,CCP,CGW,CLOCK,CUBIS,DATC,EDT,FHCU,HUD,H_U,IBOX,IPM,KBD,KMA_TMU,MON,RRC,RSE_L,RSE_R,SWRC,TMU
 SG_ C_TrunkStatus : 9|2@0+ (1,0) [0|0] ""  AMP,ASD,AVM,CCP,CGW,CLOCK,CUBIS,DATC,EDT,FHCU,HUD,H_U,IBOX,IPM,KBD,KMA_TMU,MON,RRC,RSE_L,RSE_R,SWRC,TMU
 SG_ C_OSMirrorStatus : 11|2@0+ (1,0) [0|0] ""  AMP,ASD,AVM,CCP,CGW,CLOCK,CUBIS,DATC,EDT,FHCU,HUD,H_U,IBOX,IPM,KBD,KMA_TMU,MON,RRC,RSE_L,RSE_R,SWRC,TMU

BO_ 1259 TP_CLU_MP_HU: 8 CLU
 SG_ Byte0_TCP_4EB : 7|8@0+ (1,0) [0|0] ""  H_U
 SG_ Byte1_Data_4EB : 15|8@0+ (1,0) [0|0] ""  H_U
 SG_ Byte2_Data_4EB : 23|8@0+ (1,0) [0|0] ""  H_U
 SG_ Byte3_Data_4EB : 31|8@0+ (1,0) [0|0] ""  H_U
 SG_ Byte4_Data_4EB : 39|8@0+ (1,0) [0|0] ""  H_U
 SG_ Byte5_Data_4EB : 47|8@0+ (1,0) [0|0] ""  H_U
 SG_ Byte6_Data_4EB : 55|8@0+ (1,0) [0|0] ""  H_U
 SG_ Byte7_Data_4EB : 63|8@0+ (1,0) [0|0] ""  H_U

BO_ 1258 TP_HU_MP_CLU: 8 H_U
 SG_ Byte0_TCP_4EA : 7|8@0+ (1,0) [0|0] ""  CLU
 SG_ Byte1_Data_4EA : 15|8@0+ (1,0) [0|0] ""  CLU
 SG_ Byte2_Data_4EA : 23|8@0+ (1,0) [0|0] ""  CLU
 SG_ Byte3_Data_4EA : 31|8@0+ (1,0) [0|0] ""  CLU
 SG_ Byte4_Data_4EA : 39|8@0+ (1,0) [0|0] ""  CLU
 SG_ Byte5_Data_4EA : 47|8@0+ (1,0) [0|0] ""  CLU
 SG_ Byte6_Data_4EA : 55|8@0+ (1,0) [0|0] ""  CLU
 SG_ Byte7_Data_4EA : 63|8@0+ (1,0) [0|0] ""  CLU

BO_ 1257 TP_CLU_FM_HU: 8 CLU
 SG_ Byte0_TCP_4E9 : 7|8@0+ (1,0) [0|0] ""  H_U
 SG_ Byte1_Data_4E9 : 15|8@0+ (1,0) [0|0] ""  H_U
 SG_ Byte2_Data_4E9 : 23|8@0+ (1,0) [0|0] ""  H_U
 SG_ Byte3_Data_4E9 : 31|8@0+ (1,0) [0|0] ""  H_U
 SG_ Byte4_Data_4E9 : 39|8@0+ (1,0) [0|0] ""  H_U
 SG_ Byte5_Data_4E9 : 47|8@0+ (1,0) [0|0] ""  H_U
 SG_ Byte6_Data_4E9 : 55|8@0+ (1,0) [0|0] ""  H_U
 SG_ Byte7_Data_4E9 : 63|8@0+ (1,0) [0|0] ""  H_U

BO_ 1256 TP_HU_FM_CLU: 8 H_U
 SG_ Byte0_TCP_4E8 : 7|8@0+ (1,0) [0|0] ""  CLU
 SG_ Byte1_Data_4E8 : 15|8@0+ (1,0) [0|0] ""  CLU
 SG_ Byte2_Data_4E8 : 23|8@0+ (1,0) [0|0] ""  CLU
 SG_ Byte3_Data_4E8 : 31|8@0+ (1,0) [0|0] ""  CLU
 SG_ Byte4_Data_4E8 : 39|8@0+ (1,0) [0|0] ""  CLU
 SG_ Byte5_Data_4E8 : 47|8@0+ (1,0) [0|0] ""  CLU
 SG_ Byte6_Data_4E8 : 55|8@0+ (1,0) [0|0] ""  CLU
 SG_ Byte7_Data_4E8 : 63|8@0+ (1,0) [0|0] ""  CLU

BO_ 1255 TP_CLU_MLT_HU: 8 CLU
 SG_ Byte0_TCP_4E7 : 7|8@0+ (1,0) [0|0] ""  H_U
 SG_ Byte1_Data_4E7 : 15|8@0+ (1,0) [0|0] ""  H_U
 SG_ Byte2_Data_4E7 : 23|8@0+ (1,0) [0|0] ""  H_U
 SG_ Byte3_Data_4E7 : 31|8@0+ (1,0) [0|0] ""  H_U
 SG_ Byte4_Data_4E7 : 39|8@0+ (1,0) [0|0] ""  H_U
 SG_ Byte5_Data_4E7 : 47|8@0+ (1,0) [0|0] ""  H_U
 SG_ Byte6_Data_4E7 : 55|8@0+ (1,0) [0|0] ""  H_U
 SG_ Byte7_Data_4E7 : 63|8@0+ (1,0) [0|0] ""  H_U

BO_ 487 HU_CLU_PE_13: 8 H_U
 SG_ Navi_DistToPoint1_F : 11|4@0+ (1,0) [0|0] ""  CLU,HUD
 SG_ Navi_DistToPoint1_I : 7|12@0+ (1,0) [0|0] ""  CLU,HUD
 SG_ Navi_DistToPoint1_U : 23|4@0+ (1,0) [0|0] ""  CLU,HUD
 SG_ Navi_DistToPoint2_I : 19|12@0+ (1,0) [0|0] ""  CLU,HUD
 SG_ Navi_DistToPoint2_F : 35|4@0+ (1,0) [0|0] ""  CLU,HUD
 SG_ Navi_DistToPoint2_U : 39|4@0+ (1,0) [0|0] ""  CLU,HUD
 SG_ Navi_DistToPoint3_F : 51|4@0+ (1,0) [0|0] ""  CLU,HUD
 SG_ Navi_DistToPoint3_I : 47|12@0+ (1,0) [0|0] ""  CLU,HUD
 SG_ Navi_DistToPoint3_U : 63|4@0+ (1,0) [0|0] ""  CLU,HUD

BO_ 1254 TP_HU_MLT_CLU: 8 H_U
 SG_ Byte0_TCP_4E6 : 7|8@0+ (1,0) [0|0] ""  CLU
 SG_ Byte1_Data_4E6 : 15|8@0+ (1,0) [0|0] ""  CLU
 SG_ Byte2_Data_4E6 : 23|8@0+ (1,0) [0|0] ""  CLU
 SG_ Byte3_Data_4E6 : 31|8@0+ (1,0) [0|0] ""  CLU
 SG_ Byte4_Data_4E6 : 39|8@0+ (1,0) [0|0] ""  CLU
 SG_ Byte5_Data_4E6 : 47|8@0+ (1,0) [0|0] ""  CLU
 SG_ Byte6_Data_4E6 : 55|8@0+ (1,0) [0|0] ""  CLU
 SG_ Byte7_Data_4E6 : 63|8@0+ (1,0) [0|0] ""  CLU

BO_ 486 HU_CLU_PE_12: 8 H_U
 SG_ Navi_DistToDest_I : 7|16@0+ (1,0) [0|0] ""  CLU,HUD
 SG_ Navi_DistToDest_F : 19|4@0+ (1,0) [0|0] ""  CLU,HUD
 SG_ Navi_DistToDest_U : 23|4@0+ (1,0) [0|0] ""  CLU,HUD
 SG_ Navi_EstimHour : 31|8@0+ (1,0) [0|254] "hh"  CLU,HUD
 SG_ Navi_EstimMin : 37|6@0+ (1,0) [0|59] "mm"  CLU,HUD
 SG_ Navi_EstimTimeType : 39|2@0+ (1,0) [0|0] ""  CLU,HUD
 SG_ Navi_Compass : 45|6@0+ (7.5,-7.5) [0|352.5] "Degree"  CLU,HUD

BO_ 229 HU_SYS_E_00: 8 H_U
 SG_ SYS_SW_Ver_Req : 1|2@0+ (1,0) [0|0] ""  AMP,CCP,CGW,CLOCK,CLU,HUD,IBOX,RRC,RSE_L
 SG_ SYS_CAN_Ver_Req : 3|2@0+ (1,0) [0|0] ""  AMP,CCP,CGW,CLOCK,CLU,HUD,IBOX,RRC,RSE_L
 SG_ SYS_HW_Ver_Req : 5|2@0+ (1,0) [0|0] ""  AMP,CCP,CGW,CLOCK,CLU,IBOX,RRC
 SG_ SYS_RBD_Req : 9|2@0+ (1,0) [0|0] ""  AMP,IBOX
 SG_ SYS_MOSTErrorDiag_Req : 11|2@0+ (1,0) [0|0] ""  AMP,IBOX
 SG_ SYS_Reset_Req : 17|2@0+ (1,0) [0|0] ""  AMP,IBOX

BO_ 1253 TP_CLU_VCDC_HU: 8 CLU
 SG_ Byte0_TCP_4E5 : 7|8@0+ (1,0) [0|0] ""  H_U
 SG_ Byte1_Data_4E5 : 15|8@0+ (1,0) [0|0] ""  H_U
 SG_ Byte2_Data_4E5 : 23|8@0+ (1,0) [0|0] ""  H_U
 SG_ Byte3_Data_4E5 : 31|8@0+ (1,0) [0|0] ""  H_U
 SG_ Byte4_Data_4E5 : 39|8@0+ (1,0) [0|0] ""  H_U
 SG_ Byte5_Data_4E5 : 47|8@0+ (1,0) [0|0] ""  H_U
 SG_ Byte6_Data_4E5 : 55|8@0+ (1,0) [0|0] ""  H_U
 SG_ Byte7_Data_4E5 : 63|8@0+ (1,0) [0|0] ""  H_U

BO_ 485 HU_CLU_PE_11: 8 H_U
 SG_ Navi_FixedSpdTrap : 3|4@0+ (10,0) [10|110] "Km/h"  CLU,HUD
 SG_ Navi_MobileSpdTrap : 7|4@0+ (10,0) [10|110] "Km/h"  CLU,HUD
 SG_ Navi_OverSpdAlarm : 11|2@0+ (1,0) [0|0] ""  CGW,CLU,HUD
 SG_ Navi_SpdRedlightTrap : 15|4@0+ (10,0) [10|110] "Km/h"  CLU,HUD
 SG_ Navi_NonSpdTrap : 20|5@0+ (1,0) [0|0] ""  CLU,HUD
 SG_ Navi_WarningZone : 27|4@0+ (1,0) [0|0] ""  CLU,HUD
 SG_ Navi_MergeWarning : 33|2@0+ (1,0) [0|0] ""  CLU,HUD
 SG_ Navi_CurveWarning : 39|4@0+ (1,0) [0|0] ""  CLU,HUD
 SG_ Navi_BusSpdTrap : 43|4@0+ (10,0) [10|110] "Km/h"  CLU,HUD
 SG_ Navi_SpdLimit_Type : 49|2@0+ (1,0) [0|0] ""  CLU,HUD
 SG_ Navi_SpdLimit_Unit : 51|2@0+ (1,0) [0|0] ""  CLU,HUD
 SG_ Navi_SpdInfo_Type : 55|4@0+ (1,0) [0|0] ""  CLU,HUD
 SG_ Navi_SpdLimit : 63|8@0+ (1,0) [1|254] ""  CLU,HUD

BO_ 1252 TP_HU_VCDC_CLU: 8 H_U
 SG_ Byte0_TCP_4E4 : 7|8@0+ (1,0) [0|0] ""  CLU
 SG_ Byte1_Data_4E4 : 15|8@0+ (1,0) [0|0] ""  CLU
 SG_ Byte2_Data_4E4 : 23|8@0+ (1,0) [0|0] ""  CLU
 SG_ Byte3_Data_4E4 : 31|8@0+ (1,0) [0|0] ""  CLU
 SG_ Byte4_Data_4E4 : 39|8@0+ (1,0) [0|0] ""  CLU
 SG_ Byte5_Data_4E4 : 47|8@0+ (1,0) [0|0] ""  CLU
 SG_ Byte6_Data_4E4 : 55|8@0+ (1,0) [0|0] ""  CLU
 SG_ Byte7_Data_4E4 : 63|8@0+ (1,0) [0|0] ""  CLU

BO_ 1251 TP_CLU_JB_HU: 8 CLU
 SG_ Byte0_TCP_4E3 : 7|8@0+ (1,0) [0|0] ""  H_U
 SG_ Byte1_Data_4E3 : 15|8@0+ (1,0) [0|0] ""  H_U
 SG_ Byte2_Data_4E3 : 23|8@0+ (1,0) [0|0] ""  H_U
 SG_ Byte3_Data_4E3 : 31|8@0+ (1,0) [0|0] ""  H_U
 SG_ Byte4_Data_4E3 : 39|8@0+ (1,0) [0|0] ""  H_U
 SG_ Byte5_Data_4E3 : 47|8@0+ (1,0) [0|0] ""  H_U
 SG_ Byte6_Data_4E3 : 55|8@0+ (1,0) [0|0] ""  H_U
 SG_ Byte7_Data_4E3 : 63|8@0+ (1,0) [0|0] ""  H_U

BO_ 1250 TP_HU_JB_CLU: 8 H_U
 SG_ Byte0_TCP_4E2 : 7|8@0+ (1,0) [0|0] ""  CLU
 SG_ Byte1_Data_4E2 : 15|8@0+ (1,0) [0|0] ""  CLU
 SG_ Byte2_Data_4E2 : 23|8@0+ (1,0) [0|0] ""  CLU
 SG_ Byte3_Data_4E2 : 31|8@0+ (1,0) [0|0] ""  CLU
 SG_ Byte4_Data_4E2 : 39|8@0+ (1,0) [0|0] ""  CLU
 SG_ Byte5_Data_4E2 : 47|8@0+ (1,0) [0|0] ""  CLU
 SG_ Byte6_Data_4E2 : 55|8@0+ (1,0) [0|0] ""  CLU
 SG_ Byte7_Data_4E2 : 63|8@0+ (1,0) [0|0] ""  CLU

BO_ 1248 TP_TMU_HU: 8 TMU
 SG_ Byte0_TCP_4E0 : 7|8@0+ (1,0) [0|0] ""  H_U
 SG_ Byte1_Data_4E0 : 15|8@0+ (1,0) [0|0] ""  H_U
 SG_ Byte2_Data_4E0 : 23|8@0+ (1,0) [0|0] ""  H_U
 SG_ Byte3_Data_4E0 : 31|8@0+ (1,0) [0|0] ""  H_U
 SG_ Byte4_Data_4E0 : 39|8@0+ (1,0) [0|0] ""  H_U
 SG_ Byte5_Data_4E0 : 47|8@0+ (1,0) [0|0] ""  H_U
 SG_ Byte6_Data_4E0 : 55|8@0+ (1,0) [0|0] ""  H_U
 SG_ Byte7_Data_4E0 : 63|8@0+ (1,0) [0|0] ""  H_U

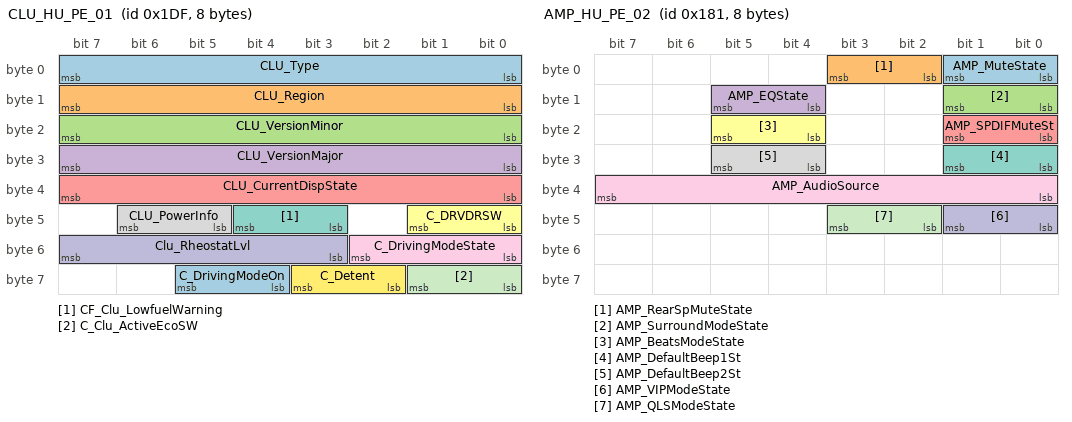
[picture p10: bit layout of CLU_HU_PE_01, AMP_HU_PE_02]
BO_ 479 CLU_HU_PE_01: 8 CLU
 SG_ CLU_Type : 7|8@0+ (1,0) [0|0] ""  H_U
 SG_ CLU_Region : 15|8@0+ (1,0) [0|0] ""  H_U
 SG_ CLU_VersionMinor : 23|8@0+ (1,0) [0|0] ""  H_U
 SG_ CLU_VersionMajor : 31|8@0+ (1,0) [0|0] ""  H_U
 SG_ CLU_CurrentDispState : 39|8@0+ (1,0) [0|0] ""  H_U
 SG_ C_DRVDRSW : 41|2@0+ (1,0) [0|0] ""  H_U
 SG_ CF_Clu_LowfuelWarning : 44|2@0+ (1,0) [0|0] ""  H_U
 SG_ CLU_PowerInfo : 46|2@0+ (1,0) [0|0] ""  H_U
 SG_ C_DrivingModeState : 50|3@0+ (1,0) [0|0] ""  H_U
 SG_ Clu_RheostatLvl : 55|5@0+ (1,0) [0|0] ""  H_U,MON,SWRC
 SG_ C_Clu_ActiveEcoSW : 57|2@0+ (1,0) [0|0] ""  H_U
 SG_ C_Detent : 59|2@0+ (1,0) [0|0] ""  CCP,CLOCK,H_U,KBD,MON,RRC,RSE_L,RSE_R
 SG_ C_DrivingModeOn : 61|2@0+ (1,0) [0|0] ""  H_U

BO_ 2015 TP_EDT_All_Req: 8 EDT
 SG_ Byte0_TCP_7DF : 7|8@0+ (1,0) [0|0] ""  AMP,ASD,AVM,CCP,CGW,CLOCK,CLU,CUBIS,DATC,FHCU,HUD,H_U,IBOX,IPM,KBD,KMA_TMU,MON,RRC,RSE_L,RSE_R,TMU
 SG_ Byte1_Data_7DF : 15|8@0+ (1,0) [0|0] ""  AMP,ASD,AVM,CCP,CGW,CLOCK,CLU,CUBIS,DATC,FHCU,HUD,H_U,IBOX,IPM,KBD,KMA_TMU,MON,RRC,RSE_L,RSE_R,TMU
 SG_ Byte2_Data_7DF : 23|8@0+ (1,0) [0|0] ""  AMP,ASD,AVM,CCP,CGW,CLOCK,CLU,CUBIS,DATC,FHCU,HUD,H_U,IBOX,IPM,KBD,KMA_TMU,MON,RRC,RSE_L,RSE_R,TMU
 SG_ Byte3_Data_7DF : 31|8@0+ (1,0) [0|0] ""  AMP,ASD,AVM,CCP,CGW,CLOCK,CLU,CUBIS,DATC,FHCU,HUD,H_U,IBOX,IPM,KBD,KMA_TMU,MON,RRC,RSE_L,RSE_R,TMU
 SG_ Byte4_Data_7DF : 39|8@0+ (1,0) [0|0] ""  AMP,ASD,AVM,CCP,CGW,CLOCK,CLU,CUBIS,DATC,FHCU,HUD,H_U,IBOX,IPM,KBD,KMA_TMU,MON,RRC,RSE_L,RSE_R,TMU
 SG_ Byte5_Data_7DF : 47|8@0+ (1,0) [0|0] ""  AMP,ASD,AVM,CCP,CGW,CLOCK,CLU,CUBIS,DATC,FHCU,HUD,H_U,IBOX,IPM,KBD,KMA_TMU,MON,RRC,RSE_L,RSE_R,TMU
 SG_ Byte6_Data_7DF : 55|8@0+ (1,0) [0|0] ""  AMP,ASD,AVM,CCP,CGW,CLOCK,CLU,CUBIS,DATC,FHCU,HUD,H_U,IBOX,IPM,KBD,KMA_TMU,MON,RRC,RSE_L,RSE_R,TMU
 SG_ Byte7_Data_7DF : 63|8@0+ (1,0) [0|0] ""  AMP,ASD,AVM,CCP,CGW,CLOCK,CLU,CUBIS,DATC,FHCU,HUD,H_U,IBOX,IPM,KBD,KMA_TMU,MON,RRC,RSE_L,RSE_R,TMU

BO_ 474 CLU_HU_PE_02: 8 CLU
 SG_ CF_Clu_AvgFCU : 1|2@0+ (1,0) [0|0] ""  H_U
 SG_ CF_Clu_AvgFCL : 9|10@0+ (1,0) [0|0] ""  H_U
 SG_ CF_Clu_TermAvgSync : 25|2@0+ (1,0) [0|0] ""  H_U
 SG_ CF_Clu_EcoDriveInf : 36|3@0+ (1,0) [0|0] ""  H_U
 SG_ CR_Clu_TermAvgFCI : 33|10@0+ (1,0) [0|0] ""  H_U
 SG_ CF_CLU_EcoScore : 55|16@0+ (1,0) [0|0] ""  H_U

BO_ 1495 CLU_HU_P_05: 8 CLU
 SG_ Clu_TripUnit : 9|2@0+ (1,0) [0|0] ""  H_U,IBOX
 SG_ Clu_DTEWarn : 11|2@0+ (1,0) [0|0] ""  H_U,IBOX
 SG_ Clu_DTE : 7|12@0+ (1,0) [0|1500] "km"  H_U,IBOX
 SG_ Clu_AFC : 23|10@0+ (0.1,0) [0|99.9] ""  H_U,IBOX
 SG_ Clu_IFC : 29|10@0+ (0.1,0) [0|99.9] ""  H_U,IBOX
 SG_ Clu_Odometer : 47|24@0+ (1,0) [0|999999] ""  H_U,IBOX

BO_ 1494 CLU_HU_P_01: 8 CLU
 SG_ CF_TripUnit : 13|2@0+ (1,0) [0|0] ""  H_U
 SG_ CF_DTE : 7|10@0+ (1,0) [0|0] ""  H_U

BO_ 214 AMP_HU_E_SYS: 8 AMP
 SG_ AMP_SWVerMajor : 7|8@0+ (1,0) [0|254] ""  H_U,IBOX
 SG_ AMP_SWVerMinor : 15|8@0+ (1,0) [0|254] ""  H_U,IBOX
 SG_ AMP_CANVerMajor : 23|8@0+ (1,0) [0|254] ""  H_U,IBOX
 SG_ AMP_CANVerMinor : 31|8@0+ (1,0) [0|254] ""  H_U,IBOX
 SG_ AMP_RBDResult : 34|3@0+ (1,0) [0|0] ""  H_U
 SG_ AMP_MOSTErrorDiagResult : 38|3@0+ (1,0) [0|0] ""  H_U
 SG_ AMP_HWVerMajor : 55|8@0+ (1,0) [0|254] ""  H_U,IBOX
 SG_ AMP_HWVerMinor : 63|8@0+ (1,0) [0|254] ""  H_U,IBOX

BO_ 1489 DATC_P_B_01: 8 CLU
 SG_ C_InhibitR_DATC : 51|1@0+ (1,0) [0|0] "" Vector__XXX
 SG_ C_InhibitP_DATC : 50|1@0+ (1,0) [0|0] "" Vector__XXX
 SG_ C_InhibitN_DATC : 49|1@0+ (1,0) [0|0] "" Vector__XXX
 SG_ C_InhibitD_DATC : 48|1@0+ (1,0) [0|0] "" Vector__XXX

BO_ 465 CLU_HU_PE_03: 8 CLU
 SG_ CF_Clu_EVDTEDisp : 0|9@0+ (1,0) [0|0] ""  H_U,IBOX
 SG_ CF_Clu_GasDTEDisp : 17|10@0+ (1,0) [0|0] ""  H_U,IBOX
 SG_ MM_CR_Clu_TotalDTEDisp : 34|11@0+ (1,0) [0|0] ""  H_U,IBOX
 SG_ CF_Clu_TripUnit : 49|2@0+ (1,0) [0|0] ""  H_U,IBOX

BO_ 1232 TP_HU_TMU: 8 H_U
 SG_ Byte0_TCP_4D0 : 7|8@0+ (1,0) [0|0] ""  TMU
 SG_ Byte1_Data_4D0 : 15|8@0+ (1,0) [0|0] ""  TMU
 SG_ Byte2_Data_4D0 : 23|8@0+ (1,0) [0|0] ""  TMU
 SG_ Byte3_Data_4D0 : 31|8@0+ (1,0) [0|0] ""  TMU
 SG_ Byte4_Data_4D0 : 39|8@0+ (1,0) [0|0] ""  TMU
 SG_ Byte5_Data_4D0 : 47|8@0+ (1,0) [0|0] ""  TMU
 SG_ Byte6_Data_4D0 : 55|8@0+ (1,0) [0|0] ""  TMU
 SG_ Byte7_Data_4D0 : 63|8@0+ (1,0) [0|0] ""  TMU

BO_ 1488 CLU_HU_P_00: 8 CLU
 SG_ MM_CR_Mcu_VehSpd_Kph : 7|8@0+ (1,0) [0|0] ""  H_U
 SG_ MM_CR_Mcu_VehSpdDec_Kph : 15|8@0+ (1,0) [0|0] ""  H_U
 SG_ MM_CR_Bms_Soc_Pc : 23|8@0+ (1,0) [0|0] ""  H_U
 SG_ MM_CR_Vcu_TqMotClu_Pc : 31|8@0+ (1,-127) [0|0] ""  H_U
 SG_ MM_CR_Bms_DrvEnaDist : 39|8@0+ (1,0) [0|0] ""  H_U
 SG_ MM_CR_Clu_Soc_Seg : 44|5@0+ (1,0) [0|0] ""  H_U,IBOX

BO_ 208 CLU_HU_E_SYS: 8 CLU
 SG_ CLU_SWVerMajor : 7|8@0+ (1,0) [0|254] ""  H_U
 SG_ CLU_SWVerMinor : 15|8@0+ (1,0) [0|254] ""  H_U
 SG_ CLU_CANVerMajor : 23|8@0+ (1,0) [0|254] ""  H_U
 SG_ CLU_CANVerMinor : 31|8@0+ (1,0) [0|254] ""  H_U
 SG_ CLU_HWVerMajor : 55|8@0+ (1,0) [0|254] ""  H_U
 SG_ CLU_HWVerMinor : 63|8@0+ (1,0) [0|254] ""  H_U

BO_ 448 HU_DATC_PE_00: 8 H_U
 SG_ DATC_AqsLevelChg : 3|4@0+ (1,0) [0|0] ""  CGW,CLU,DATC,IPM
 SG_ RSELockOnOff : 7|2@0+ (1,0) [0|0] ""  CGW,DATC,IPM,RRC
 SG_ DATC_AqsMode : 9|2@0+ (1,0) [0|0] ""  CGW,CLU,DATC,IPM
 SG_ HU_Graphreset_Info : 17|2@0+ (1,0) [0|0] ""  CGW,CLU,DATC,IPM
 SG_ HU_VRActivity : 33|2@0+ (1,0) [0|0] ""  CGW,CLU,DATC,IPM
 SG_ HU_PhoneActivity : 35|2@0+ (1,0) [0|0] ""  CGW,CLU,DATC,IPM
 SG_ BlowerNoiseControl : 37|2@0+ (1,0) [0|0] ""  CGW,CLU,DATC,IPM

BO_ 1211 TP_HU_TBT_CLU: 8 H_U
 SG_ Byte0_TCP_4BB : 7|8@0+ (1,0) [0|0] ""  CLU
 SG_ Byte1_Data_4BB : 15|8@0+ (1,0) [0|0] ""  CLU
 SG_ Byte2_Data_4BB : 23|8@0+ (1,0) [0|0] ""  CLU
 SG_ Byte3_Data_4BB : 31|8@0+ (1,0) [0|0] ""  CLU
 SG_ Byte4_Data_4BB : 39|8@0+ (1,0) [0|0] ""  CLU
 SG_ Byte5_Data_4BB : 47|8@0+ (1,0) [0|0] ""  CLU
 SG_ Byte6_Data_4BB : 55|8@0+ (1,0) [0|0] ""  CLU
 SG_ Byte7_Data_4BB : 63|8@0+ (1,0) [0|0] ""  CLU

BO_ 1207 TP_HU_DAB_CLU: 8 H_U
 SG_ Byte0_TCP_4B7 : 7|8@0+ (1,0) [0|0] ""  CLU
 SG_ Byte1_Data_4B7 : 15|8@0+ (1,0) [0|0] ""  CLU
 SG_ Byte2_Data_4B7 : 23|8@0+ (1,0) [0|0] ""  CLU
 SG_ Byte3_Data_4B7 : 31|8@0+ (1,0) [0|0] ""  CLU
 SG_ Byte4_Data_4B7 : 39|8@0+ (1,0) [0|0] ""  CLU
 SG_ Byte5_Data_4B7 : 47|8@0+ (1,0) [0|0] ""  CLU
 SG_ Byte6_Data_4B7 : 55|8@0+ (1,0) [0|0] ""  CLU
 SG_ Byte7_Data_4B7 : 63|8@0+ (1,0) [0|0] ""  CLU

BO_ 1206 TP_HU_XM_CLU: 8 H_U
 SG_ Byte0_TCP_4B6 : 7|8@0+ (1,0) [0|0] ""  CLU
 SG_ Byte1_Data_4B6 : 15|8@0+ (1,0) [0|0] ""  CLU
 SG_ Byte2_Data_4B6 : 23|8@0+ (1,0) [0|0] ""  CLU
 SG_ Byte3_Data_4B6 : 31|8@0+ (1,0) [0|0] ""  CLU
 SG_ Byte4_Data_4B6 : 39|8@0+ (1,0) [0|0] ""  CLU
 SG_ Byte5_Data_4B6 : 47|8@0+ (1,0) [0|0] ""  CLU
 SG_ Byte6_Data_4B6 : 55|8@0+ (1,0) [0|0] ""  CLU
 SG_ Byte7_Data_4B6 : 63|8@0+ (1,0) [0|0] ""  CLU

BO_ 1204 TP_HU_DMB_CLU: 8 H_U
 SG_ Byte0_TCP_4B4 : 7|8@0+ (1,0) [0|0] ""  CLU
 SG_ Byte1_Data_4B4 : 15|8@0+ (1,0) [0|0] ""  CLU
 SG_ Byte2_Data_4B4 : 23|8@0+ (1,0) [0|0] ""  CLU
 SG_ Byte3_Data_4B4 : 31|8@0+ (1,0) [0|0] ""  CLU
 SG_ Byte4_Data_4B4 : 39|8@0+ (1,0) [0|0] ""  CLU
 SG_ Byte5_Data_4B4 : 47|8@0+ (1,0) [0|0] ""  CLU
 SG_ Byte6_Data_4B4 : 55|8@0+ (1,0) [0|0] ""  CLU
 SG_ Byte7_Data_4B4 : 63|8@0+ (1,0) [0|0] ""  CLU

BO_ 432 TMU_GW_PE_01: 8 TMU
 SG_ C_DATCOnOffReq : 1|2@0+ (1,0) [0|0] ""  CGW,CLU,DATC,H_U,IPM
 SG_ C_DATCTempUnit : 3|2@0+ (1,0) [0|0] ""  CGW,CLU,DATC,H_U,IPM
 SG_ C_DATCTempSet : 15|8@0+ (1,0) [0|0] ""  CGW,CLU,DATC,H_U,IPM
 SG_ TMU_IVRActivity : 33|2@0+ (1,0) [0|0] ""  CGW,CLU,DATC,H_U,IPM
 SG_ TMU_PhoneActivity : 35|2@0+ (1,0) [0|0] ""  CGW,CLU,DATC,H_U,IPM

BO_ 1195 TP_CLU_TBT_HU: 8 CLU
 SG_ Byte0_TCP_4AB : 7|8@0+ (1,0) [0|0] ""  H_U
 SG_ Byte1_Data_4AB : 15|8@0+ (1,0) [0|0] ""  H_U
 SG_ Byte2_Data_4AB : 23|8@0+ (1,0) [0|0] ""  H_U
 SG_ Byte3_Data_4AB : 31|8@0+ (1,0) [0|0] ""  H_U
 SG_ Byte4_Data_4AB : 39|8@0+ (1,0) [0|0] ""  H_U
 SG_ Byte5_Data_4AB : 47|8@0+ (1,0) [0|0] ""  H_U
 SG_ Byte6_Data_4AB : 55|8@0+ (1,0) [0|0] ""  H_U
 SG_ Byte7_Data_4AB : 63|8@0+ (1,0) [0|0] ""  H_U

BO_ 1191 TP_CLU_DAB_HU: 8 CLU
 SG_ Byte0_TCP_4A7 : 7|8@0+ (1,0) [0|0] ""  H_U
 SG_ Byte1_Data_4A7 : 15|8@0+ (1,0) [0|0] ""  H_U
 SG_ Byte2_Data_4A7 : 23|8@0+ (1,0) [0|0] ""  H_U
 SG_ Byte3_Data_4A7 : 31|8@0+ (1,0) [0|0] ""  H_U
 SG_ Byte4_Data_4A7 : 39|8@0+ (1,0) [0|0] ""  H_U
 SG_ Byte5_Data_4A7 : 47|8@0+ (1,0) [0|0] ""  H_U
 SG_ Byte6_Data_4A7 : 55|8@0+ (1,0) [0|0] ""  H_U
 SG_ Byte7_Data_4A7 : 63|8@0+ (1,0) [0|0] ""  H_U

BO_ 1190 TP_CLU_XM_HU: 8 CLU
 SG_ Byte0_TCP_4A6 : 7|8@0+ (1,0) [0|0] ""  H_U
 SG_ Byte1_Data_4A6 : 15|8@0+ (1,0) [0|0] ""  H_U
 SG_ Byte2_Data_4A6 : 23|8@0+ (1,0) [0|0] ""  H_U
 SG_ Byte3_Data_4A6 : 31|8@0+ (1,0) [0|0] ""  H_U
 SG_ Byte4_Data_4A6 : 39|8@0+ (1,0) [0|0] ""  H_U
 SG_ Byte5_Data_4A6 : 47|8@0+ (1,0) [0|0] ""  H_U
 SG_ Byte6_Data_4A6 : 55|8@0+ (1,0) [0|0] ""  H_U
 SG_ Byte7_Data_4A6 : 63|8@0+ (1,0) [0|0] ""  H_U

BO_ 1188 TP_CLU_DMB_HU: 8 CLU
 SG_ Byte0_TCP_4A4 : 7|8@0+ (1,0) [0|0] ""  H_U
 SG_ Byte1_Data_4A4 : 15|8@0+ (1,0) [0|0] ""  H_U
 SG_ Byte2_Data_4A4 : 23|8@0+ (1,0) [0|0] ""  H_U
 SG_ Byte3_Data_4A4 : 31|8@0+ (1,0) [0|0] ""  H_U
 SG_ Byte4_Data_4A4 : 39|8@0+ (1,0) [0|0] ""  H_U
 SG_ Byte5_Data_4A4 : 47|8@0+ (1,0) [0|0] ""  H_U
 SG_ Byte6_Data_4A4 : 55|8@0+ (1,0) [0|0] ""  H_U
 SG_ Byte7_Data_4A4 : 63|8@0+ (1,0) [0|0] ""  H_U

BO_ 1179 TP_HU_NAVI_CLU: 8 H_U
 SG_ Byte0_TCP_49B : 7|8@0+ (1,0) [0|0] ""  CLU
 SG_ Byte1_Data_49B : 15|8@0+ (1,0) [0|0] ""  CLU
 SG_ Byte2_Data_49B : 23|8@0+ (1,0) [0|0] ""  CLU
 SG_ Byte3_Data_49B : 31|8@0+ (1,0) [0|0] ""  CLU
 SG_ Byte4_Data_49B : 39|8@0+ (1,0) [0|0] ""  CLU
 SG_ Byte5_Data_49B : 47|8@0+ (1,0) [0|0] ""  CLU
 SG_ Byte6_Data_49B : 55|8@0+ (1,0) [0|0] ""  CLU
 SG_ Byte7_Data_49B : 63|8@0+ (1,0) [0|0] ""  CLU

BO_ 1178 TP_CLU_Ipod_HU: 8 CLU
 SG_ Byte0_TCP_49A : 7|8@0+ (1,0) [0|0] ""  H_U
 SG_ Byte1_Data_49A : 15|8@0+ (1,0) [0|0] ""  H_U
 SG_ Byte2_Data_49A : 23|8@0+ (1,0) [0|0] ""  H_U
 SG_ Byte3_Data_49A : 31|8@0+ (1,0) [0|0] ""  H_U
 SG_ Byte4_Data_49A : 39|8@0+ (1,0) [0|0] ""  H_U
 SG_ Byte5_Data_49A : 47|8@0+ (1,0) [0|0] ""  H_U
 SG_ Byte6_Data_49A : 55|8@0+ (1,0) [0|0] ""  H_U
 SG_ Byte7_Data_49A : 63|8@0+ (1,0) [0|0] ""  H_U

BO_ 410 HU_CLU_PE_08: 8 H_U
 SG_ VCDC_SelDiscNo : 11|4@0+ (1,0) [0|0] ""  CLU
 SG_ VCDC_TrackChapterNo : 7|10@0+ (1,0) [0|0] ""  CLU
 SG_ VCDC_PlayTime : 23|24@0+ (1,0) [0|0] ""  CLU
 SG_ MLT_PlayTime : 47|24@0+ (1,0) [0|0] ""  CLU

BO_ 1176 TP_CLU_DVD_HU: 8 CLU
 SG_ Byte0_TCP_498 : 7|8@0+ (1,0) [0|0] ""  H_U
 SG_ Byte1_Data_498 : 15|8@0+ (1,0) [0|0] ""  H_U
 SG_ Byte2_Data_498 : 23|8@0+ (1,0) [0|0] ""  H_U
 SG_ Byte3_Data_498 : 31|8@0+ (1,0) [0|0] ""  H_U
 SG_ Byte4_Data_498 : 39|8@0+ (1,0) [0|0] ""  H_U
 SG_ Byte5_Data_498 : 47|8@0+ (1,0) [0|0] ""  H_U
 SG_ Byte6_Data_498 : 55|8@0+ (1,0) [0|0] ""  H_U
 SG_ Byte7_Data_498 : 63|8@0+ (1,0) [0|0] ""  H_U

BO_ 1175 TP_CLU_USB_HU: 8 CLU
 SG_ Byte0_TCP_497 : 7|8@0+ (1,0) [0|0] ""  H_U
 SG_ Byte1_Data_497 : 15|8@0+ (1,0) [0|0] ""  H_U
 SG_ Byte2_Data_497 : 23|8@0+ (1,0) [0|0] ""  H_U
 SG_ Byte3_Data_497 : 31|8@0+ (1,0) [0|0] ""  H_U
 SG_ Byte4_Data_497 : 39|8@0+ (1,0) [0|0] ""  H_U
 SG_ Byte5_Data_497 : 47|8@0+ (1,0) [0|0] ""  H_U
 SG_ Byte6_Data_497 : 55|8@0+ (1,0) [0|0] ""  H_U
 SG_ Byte7_Data_497 : 63|8@0+ (1,0) [0|0] ""  H_U

BO_ 407 HU_CLU_PE_05: 8 H_U
 SG_ HU_LanguageInfo : 7|8@0+ (1,0) [0|0] ""  CLU,HUD
 SG_ HU_MuteStatus : 9|2@0+ (1,0) [0|0] ""  CLU,HUD
 SG_ HU_VolumeStatus : 15|6@0+ (1,0) [0|0] ""  CLU,HUD
 SG_ HU_NaviDisp : 17|2@0+ (1,0) [0|0] ""  CLU,HUD
 SG_ HU_NaviStatus : 19|2@0+ (1,0) [0|0] ""  CGW,CLU,HUD,IPM
 SG_ HU_DistanceUnit : 21|2@0+ (1,0) [0|0] ""  CLU,HUD
 SG_ HU_Navigation_On_Off : 23|2@0+ (1,0) [0|0] ""  AVM,CGW,CLU,DATC,HUD,IPM

BO_ 1942 TP_AMP_HU_DiagRes: 8 AMP
 SG_ Byte0_TCP_796 : 7|8@0+ (1,0) [0|0] ""  H_U
 SG_ Byte1_Data_796 : 15|8@0+ (1,0) [0|0] ""  H_U
 SG_ Byte2_Data_796 : 23|8@0+ (1,0) [0|0] ""  H_U
 SG_ Byte3_Data_796 : 31|8@0+ (1,0) [0|0] ""  H_U
 SG_ Byte4_Data_796 : 39|8@0+ (1,0) [0|0] ""  H_U
 SG_ Byte5_Data_796 : 47|8@0+ (1,0) [0|0] ""  H_U
 SG_ Byte6_Data_796 : 55|8@0+ (1,0) [0|0] ""  H_U
 SG_ Byte7_Data_796 : 63|8@0+ (1,0) [0|0] ""  H_U

BO_ 406 HU_CLU_PE_04: 8 H_U
 SG_ C_SDARS_ChannelNo : 7|8@0+ (1,0) [0|0] ""  CLU
 SG_ C_NaviRouteGuidance : 11|2@0+ (1,0) [0|0] ""  CLU
 SG_ HD_SPS_ChannelNo : 15|4@0+ (1,0) [0|0] ""  CLU
 SG_ C_SDARS_PresetNo : 19|4@0+ (1,0) [0|0] ""  CLU
 SG_ DAB_ServiceFollowing : 21|2@0+ (1,0) [0|0] ""  CLU
 SG_ SXM_ChannelNo : 25|10@0+ (1,0) [0|999] ""  AMP,CLU,HUD

BO_ 1941 TP_HU_AMP_DiagReq: 8 H_U
 SG_ Byte0_TCP_795 : 7|8@0+ (1,0) [0|0] ""  AMP
 SG_ Byte1_Data_795 : 15|8@0+ (1,0) [0|0] ""  AMP
 SG_ Byte2_Data_795 : 23|8@0+ (1,0) [0|0] ""  AMP
 SG_ Byte3_Data_795 : 31|8@0+ (1,0) [0|0] ""  AMP
 SG_ Byte4_Data_795 : 39|8@0+ (1,0) [0|0] ""  AMP
 SG_ Byte5_Data_795 : 47|8@0+ (1,0) [0|0] ""  AMP
 SG_ Byte6_Data_795 : 55|8@0+ (1,0) [0|0] ""  AMP
 SG_ Byte7_Data_795 : 63|8@0+ (1,0) [0|0] ""  AMP

BO_ 1173 TP_CLU_CD_HU: 8 CLU
 SG_ Byte0_TCP_495 : 7|8@0+ (1,0) [0|0] ""  H_U
 SG_ Byte1_Data_495 : 15|8@0+ (1,0) [0|0] ""  H_U
 SG_ Byte2_Data_495 : 23|8@0+ (1,0) [0|0] ""  H_U
 SG_ Byte3_Data_495 : 31|8@0+ (1,0) [0|0] ""  H_U
 SG_ Byte4_Data_495 : 39|8@0+ (1,0) [0|0] ""  H_U
 SG_ Byte5_Data_495 : 47|8@0+ (1,0) [0|0] ""  H_U
 SG_ Byte6_Data_495 : 55|8@0+ (1,0) [0|0] ""  H_U
 SG_ Byte7_Data_495 : 63|8@0+ (1,0) [0|0] ""  H_U

BO_ 405 HU_CLU_PE_03: 8 H_U
 SG_ HU_IntegPresetNum : 7|8@0+ (1,0) [0|0] ""  AMP,CLU,HUD
 SG_ Radio_Area : 10|8@0+ (1,0) [0|0] ""  CLU
 SG_ DMB_PresetNo : 29|5@0+ (1,0) [0|0] ""  CLU
 SG_ RADIO_PresetNo : 18|5@0+ (1,0) [0|0] ""  CLU
 SG_ HU_Opstate_DIS2 : 38|7@0+ (1,0) [0|0] ""  AMP,CLU,HUD

BO_ 1936 TP_HU_All_Req: 8 H_U
 SG_ Byte0_TCP_790 : 7|8@0+ (1,0) [0|0] ""  AMP,ASD,AVM,CCP,CGW,CLOCK,CLU,CUBIS,DATC,EDT,FHCU,HUD,IBOX,IPM,KBD,KMA_TMU,MON,RRC,RSE_L,RSE_R,SWRC,TMU
 SG_ Byte1_Data_790 : 15|8@0+ (1,0) [0|0] ""  AMP,ASD,AVM,CCP,CGW,CLOCK,CLU,CUBIS,DATC,EDT,FHCU,HUD,IBOX,IPM,KBD,KMA_TMU,MON,RRC,RSE_L,RSE_R,SWRC,TMU
 SG_ Byte2_Data_790 : 23|8@0+ (1,0) [0|0] ""  AMP,ASD,AVM,CCP,CGW,CLOCK,CLU,CUBIS,DATC,EDT,FHCU,HUD,IBOX,IPM,KBD,KMA_TMU,MON,RRC,RSE_L,RSE_R,SWRC,TMU
 SG_ Byte3_Data_790 : 31|8@0+ (1,0) [0|0] ""  AMP,ASD,AVM,CCP,CGW,CLOCK,CLU,CUBIS,DATC,EDT,FHCU,HUD,IBOX,IPM,KBD,KMA_TMU,MON,RRC,RSE_L,RSE_R,SWRC,TMU
 SG_ Byte4_Data_790 : 39|8@0+ (1,0) [0|0] ""  AMP,ASD,AVM,CCP,CGW,CLOCK,CLU,CUBIS,DATC,EDT,FHCU,HUD,IBOX,IPM,KBD,KMA_TMU,MON,RRC,RSE_L,RSE_R,SWRC,TMU
 SG_ Byte5_Data_790 : 47|8@0+ (1,0) [0|0] ""  AMP,ASD,AVM,CCP,CGW,CLOCK,CLU,CUBIS,DATC,EDT,FHCU,HUD,IBOX,IPM,KBD,KMA_TMU,MON,RRC,RSE_L,RSE_R,SWRC,TMU
 SG_ Byte6_Data_790 : 55|8@0+ (1,0) [0|0] ""  AMP,ASD,AVM,CCP,CGW,CLOCK,CLU,CUBIS,DATC,EDT,FHCU,HUD,IBOX,IPM,KBD,KMA_TMU,MON,RRC,RSE_L,RSE_R,SWRC,TMU
 SG_ Byte7_Data_790 : 63|8@0+ (1,0) [0|0] ""  AMP,ASD,AVM,CCP,CGW,CLOCK,CLU,CUBIS,DATC,EDT,FHCU,HUD,IBOX,IPM,KBD,KMA_TMU,MON,RRC,RSE_L,RSE_R,SWRC,TMU

BO_ 1167 TP_HU_Ipod_CLU: 8 H_U
 SG_ Byte0_TCP_48F : 7|8@0+ (1,0) [0|0] ""  CLU
 SG_ Byte1_Data_48F : 15|8@0+ (1,0) [0|0] ""  CLU
 SG_ Byte2_Data_48F : 23|8@0+ (1,0) [0|0] ""  CLU
 SG_ Byte3_Data_48F : 31|8@0+ (1,0) [0|0] ""  CLU
 SG_ Byte4_Data_48F : 39|8@0+ (1,0) [0|0] ""  CLU
 SG_ Byte5_Data_48F : 47|8@0+ (1,0) [0|0] ""  CLU
 SG_ Byte6_Data_48F : 55|8@0+ (1,0) [0|0] ""  CLU
 SG_ Byte7_Data_48F : 63|8@0+ (1,0) [0|0] ""  CLU

BO_ 1166 TP_HU_DVD_CLU: 8 H_U
 SG_ Byte0_TCP_48E : 7|8@0+ (1,0) [0|0] ""  CLU
 SG_ Byte1_Data_48E : 15|8@0+ (1,0) [0|0] ""  CLU
 SG_ Byte2_Data_48E : 23|8@0+ (1,0) [0|0] ""  CLU
 SG_ Byte3_Data_48E : 31|8@0+ (1,0) [0|0] ""  CLU
 SG_ Byte4_Data_48E : 39|8@0+ (1,0) [0|0] ""  CLU
 SG_ Byte5_Data_48E : 47|8@0+ (1,0) [0|0] ""  CLU
 SG_ Byte6_Data_48E : 55|8@0+ (1,0) [0|0] ""  CLU
 SG_ Byte7_Data_48E : 63|8@0+ (1,0) [0|0] ""  CLU

BO_ 1165 TP_HU_CD_CLU: 8 H_U
 SG_ Byte0_TCP_48D : 7|8@0+ (1,0) [0|0] ""  CLU
 SG_ Byte1_Data_48D : 15|8@0+ (1,0) [0|0] ""  CLU
 SG_ Byte2_Data_48D : 23|8@0+ (1,0) [0|0] ""  CLU
 SG_ Byte3_Data_48D : 31|8@0+ (1,0) [0|0] ""  CLU
 SG_ Byte4_Data_48D : 39|8@0+ (1,0) [0|0] ""  CLU
 SG_ Byte5_Data_48D : 47|8@0+ (1,0) [0|0] ""  CLU
 SG_ Byte6_Data_48D : 55|8@0+ (1,0) [0|0] ""  CLU
 SG_ Byte7_Data_48D : 63|8@0+ (1,0) [0|0] ""  CLU

BO_ 1164 TP_CLU_NAVI_HU: 8 CLU
 SG_ Byte0_TCP_48C : 7|8@0+ (1,0) [0|0] ""  H_U
 SG_ Byte1_Data_48C : 15|8@0+ (1,0) [0|0] ""  H_U
 SG_ Byte2_Data_48C : 23|8@0+ (1,0) [0|0] ""  H_U
 SG_ Byte3_Data_48C : 31|8@0+ (1,0) [0|0] ""  H_U
 SG_ Byte4_Data_48C : 39|8@0+ (1,0) [0|0] ""  H_U
 SG_ Byte5_Data_48C : 47|8@0+ (1,0) [0|0] ""  H_U
 SG_ Byte6_Data_48C : 55|8@0+ (1,0) [0|0] ""  H_U
 SG_ Byte7_Data_48C : 63|8@0+ (1,0) [0|0] ""  H_U

BO_ 139 AMP_HU_E_12: 8 AMP
 SG_ AMP_Beep2VolumeState : 7|8@0+ (1,0) [0|0] ""  H_U
 SG_ AMP_Beep2FrequencyState : 15|16@0+ (1,0) [0|0] ""  H_U
 SG_ AMP_Beep2OutputMaskState : 31|16@0+ (1,0) [0|0] ""  H_U
 SG_ AMP_Beep2DOnState : 47|8@0+ (1,0) [0|0] ""  H_U
 SG_ AMP_Beep2DOffState : 55|8@0+ (1,0) [0|0] ""  H_U
 SG_ AMP_Beep2NOfCycleState : 63|8@0+ (1,0) [0|0] ""  H_U

BO_ 138 AMP_HU_E_11: 8 AMP
 SG_ AMP_Beep1VolumeState : 7|8@0+ (1,0) [0|0] ""  H_U
 SG_ AMP_Beep1FrequencyState : 15|16@0+ (1,0) [0|0] ""  H_U
 SG_ AMP_Beep1OutputMaskState : 31|16@0+ (1,0) [0|0] ""  H_U
 SG_ AMP_Beep1DOnState : 47|8@0+ (1,0) [0|0] ""  H_U
 SG_ AMP_Beep1DOffState : 55|8@0+ (1,0) [0|0] ""  H_U
 SG_ AMP_Beep1NOfCycleState : 63|8@0+ (1,0) [0|0] ""  H_U

BO_ 137 AMP_HU_E_10: 8 AMP
 SG_ AMP_MTSOutputMaskSupport : 1|2@0+ (1,0) [0|0] ""  H_U
 SG_ AMP_MTSMuteMaskSupport : 5|2@0+ (1,0) [0|0] ""  H_U
 SG_ AMP_HFOutputMaskSupport : 9|2@0+ (1,0) [0|0] ""  H_U
 SG_ AMP_HFMuteMaskSupport : 13|2@0+ (1,0) [0|0] ""  H_U
 SG_ AMP_NaviOutputMaskSupport : 17|2@0+ (1,0) [0|0] ""  H_U
 SG_ AMP_NaviMuteMaskSupport : 21|2@0+ (1,0) [0|0] ""  H_U

BO_ 1928 TP_HU_PhyRes: 8 H_U
 SG_ Byte0_TCP_788 : 7|8@0+ (1,0) [0|0] ""  EDT
 SG_ Byte1_Data_788 : 15|8@0+ (1,0) [0|0] ""  EDT
 SG_ Byte2_Data_788 : 23|8@0+ (1,0) [0|0] ""  EDT
 SG_ Byte3_Data_788 : 31|8@0+ (1,0) [0|0] ""  EDT
 SG_ Byte4_Data_788 : 39|8@0+ (1,0) [0|0] ""  EDT
 SG_ Byte5_Data_788 : 47|8@0+ (1,0) [0|0] ""  EDT
 SG_ Byte6_Data_788 : 55|8@0+ (1,0) [0|0] ""  EDT
 SG_ Byte7_Data_788 : 63|8@0+ (1,0) [0|0] ""  EDT

BO_ 136 AMP_HU_E_09: 8 AMP
 SG_ AMP_MaxBeep2VolumeState : 7|8@0+ (1,0) [0|0] ""  H_U
 SG_ AMP_MaxBeep2Freq_State : 15|16@0+ (1,0) [0|0] ""  H_U
 SG_ AMP_Beep2OutputMaskSup : 33|2@0+ (1,0) [0|0] ""  H_U
 SG_ AMP_MaxBeep2DOnState : 47|8@0+ (1,0) [0|0] ""  H_U
 SG_ AMP_MaxBeep2DOffState : 55|8@0+ (1,0) [0|0] ""  H_U
 SG_ AMP_MaxBeep2NOfCycleState : 63|8@0+ (1,0) [0|0] ""  H_U

BO_ 135 AMP_HU_E_08: 8 AMP
 SG_ AMP_MaxBeep1VolumeState : 7|8@0+ (1,0) [0|0] ""  H_U
 SG_ AMP_MaxBeep1Freq_State : 15|16@0+ (1,0) [0|0] ""  H_U
 SG_ AMP_Beep1OutputMaskSup : 33|2@0+ (1,0) [0|0] ""  H_U
 SG_ AMP_MaxBeep1DOnState : 47|8@0+ (1,0) [0|0] ""  H_U
 SG_ AMP_MaxBeep1DOffState : 55|8@0+ (1,0) [0|0] ""  H_U
 SG_ AMP_MaxBeep1NOfCycleState : 63|8@0+ (1,0) [0|0] ""  H_U

BO_ 134 AMP_HU_E_07: 8 AMP
 SG_ ASD_SetValue : 2|3@0+ (1,0) [0|0] ""  H_U,IBOX
 SG_ ASD_Version : 15|8@0+ (1,0) [0|0] ""  H_U,IBOX

BO_ 1157 TP_HU_CLU_HF: 8 H_U
 SG_ Byte0_TCP_485 : 7|8@0+ (1,0) [0|0] ""  CLU
 SG_ Byte1_Data_485 : 15|8@0+ (1,0) [0|0] ""  CLU
 SG_ Byte2_Data_485 : 23|8@0+ (1,0) [0|0] ""  CLU
 SG_ Byte3_Data_485 : 31|8@0+ (1,0) [0|0] ""  CLU
 SG_ Byte4_Data_485 : 39|8@0+ (1,0) [0|0] ""  CLU
 SG_ Byte5_Data_485 : 47|8@0+ (1,0) [0|0] ""  CLU
 SG_ Byte6_Data_485 : 55|8@0+ (1,0) [0|0] ""  CLU
 SG_ Byte7_Data_485 : 63|8@0+ (1,0) [0|0] ""  CLU

BO_ 133 AMP_HU_E_06: 8 AMP
 SG_ AMP_MaxVolumeStep : 7|8@0+ (1,0) [0|0] ""  H_U
 SG_ AMP_MaxBalanceStep : 15|8@0+ (1,0) [0|0] ""  H_U
 SG_ AMP_MaxFadeStep : 23|8@0+ (1,0) [0|0] ""  H_U
 SG_ AMP_MaxBassStep : 31|8@0+ (1,0) [0|0] ""  H_U
 SG_ AMP_MaxMidStep : 39|8@0+ (1,0) [0|0] ""  H_U
 SG_ AMP_MaxTrebleStep : 47|8@0+ (1,0) [0|0] ""  H_U
 SG_ AMP_ASDMajorVer : 55|8@0+ (1,0) [0|0] ""  H_U
 SG_ AMP_ASDMinorVer : 63|8@0+ (1,0) [0|0] ""  H_U

BO_ 389 AMP_HU_PE_05: 8 AMP
 SG_ AMP_EngOrderC2Setting : 7|8@0+ (1,0) [0|0] ""  H_U
 SG_ AMP_EngOrderC4Setting : 15|8@0+ (1,0) [0|0] ""  H_U
 SG_ AMP_EngOrderC6Setting : 23|8@0+ (1,0) [0|0] ""  H_U
 SG_ AMP_APSBand0Setting : 31|8@0+ (1,0) [0|0] ""  H_U
 SG_ AMP_APSBand1Setting : 39|8@0+ (1,0) [0|0] ""  H_U
 SG_ AMP_APSBand2Setting : 47|8@0+ (1,0) [0|0] ""  H_U
 SG_ AMP_APSBand3Setting : 55|8@0+ (1,0) [0|0] ""  H_U
 SG_ AMP_APSBand4Setting : 63|8@0+ (1,0) [0|0] ""  H_U

BO_ 132 AMP_HU_E_05: 8 AMP
 SG_ AMP_HFVolumeState : 7|8@0+ (1,0) [0|0] ""  H_U
 SG_ AMP_HFAudioCutState : 15|8@0+ (1,0) [0|0] ""  H_U
 SG_ AMP_HFOutputMaskState : 23|16@0+ (1,0) [0|0] ""  H_U
 SG_ AMP_HFMuteMaskState : 39|16@0+ (1,0) [0|0] ""  H_U
 SG_ AMP_MaxHFVolumeState : 55|8@0+ (1,0) [0|0] ""  H_U
 SG_ AMP_MaxHFAudioCutState : 63|8@0+ (1,0) [0|0] ""  H_U

BO_ 388 AMP_HU_PE_04: 8 AMP
 SG_ AMP_PESSModeState : 1|2@0+ (1,0) [0|0] ""  H_U
 SG_ AMP_PESSDesignSetting : 4|3@0+ (1,0) [0|0] ""  H_U
 SG_ AMP_PESSAPSSetting : 7|3@0+ (1,0) [0|0] ""  H_U
 SG_ AMP_PESSVolumeSetting : 15|8@0+ (1,0) [0|0] ""  H_U

BO_ 1156 TP_CLU_HF_HU: 8 CLU
 SG_ Byte0_TCP_484 : 7|8@0+ (1,0) [0|0] ""  H_U
 SG_ Byte1_Data_484 : 15|8@0+ (1,0) [0|0] ""  H_U
 SG_ Byte2_Data_484 : 23|8@0+ (1,0) [0|0] ""  H_U
 SG_ Byte3_Data_484 : 31|8@0+ (1,0) [0|0] ""  H_U
 SG_ Byte4_Data_484 : 39|8@0+ (1,0) [0|0] ""  H_U
 SG_ Byte5_Data_484 : 47|8@0+ (1,0) [0|0] ""  H_U
 SG_ Byte6_Data_484 : 55|8@0+ (1,0) [0|0] ""  H_U
 SG_ Byte7_Data_484 : 63|8@0+ (1,0) [0|0] ""  H_U

BO_ 131 AMP_HU_E_04: 8 AMP
 SG_ AMP_MTSVolumeState : 7|8@0+ (1,0) [0|0] ""  H_U
 SG_ AMP_MTSAudioCutState : 15|8@0+ (1,0) [0|0] ""  H_U
 SG_ AMP_MTSOutputMaskState : 23|16@0+ (1,0) [0|0] ""  H_U
 SG_ AMP_MTSMuteMaskState : 39|16@0+ (1,0) [0|0] ""  H_U
 SG_ AMP_MaxMTSVolumeState : 55|8@0+ (1,0) [0|0] ""  H_U
 SG_ AMP_MaxMTSAudioCutState : 63|8@0+ (1,0) [0|0] ""  H_U

BO_ 130 AMP_HU_E_03: 8 AMP
 SG_ AMP_NaviVolumeState : 7|8@0+ (1,0) [0|0] ""  H_U
 SG_ AMP_NaviAudioCutState : 15|8@0+ (1,0) [0|0] ""  H_U
 SG_ AMP_NaviOutputMaskState : 23|16@0+ (1,0) [0|0] ""  H_U
 SG_ AMP_NaviMuteMaskState : 39|16@0+ (1,0) [0|0] ""  H_U
 SG_ AMP_MaxNaviVolumeState : 55|8@0+ (1,0) [0|0] ""  H_U
 SG_ AMP_MaxNaviAudioCutState : 63|8@0+ (1,0) [0|0] ""  H_U

BO_ 385 AMP_HU_PE_02: 8 AMP
 SG_ AMP_MuteState : 1|2@0+ (1,0) [0|0] ""  H_U
 SG_ AMP_RearSpMuteState : 3|2@0+ (1,0) [0|0] ""  H_U
 SG_ AMP_SurroundModeState : 9|2@0+ (1,0) [0|0] ""  H_U
 SG_ AMP_EQState : 13|2@0+ (1,0) [0|0] ""  H_U
 SG_ AMP_SPDIFMuteSt : 17|2@0+ (1,0) [0|0] ""  H_U
 SG_ AMP_BeatsModeState : 21|2@0+ (1,0) [0|0] ""  H_U
 SG_ AMP_DefaultBeep1St : 25|2@0+ (1,0) [0|0] ""  H_U
 SG_ AMP_DefaultBeep2St : 29|2@0+ (1,0) [0|0] ""  H_U
 SG_ AMP_AudioSource : 39|8@0+ (1,0) [0|0] ""  H_U
 SG_ AMP_VIPModeState : 41|2@0+ (1,0) [0|0] ""  H_U
 SG_ AMP_QLSModeState : 43|2@0+ (1,0) [0|0] ""  H_U

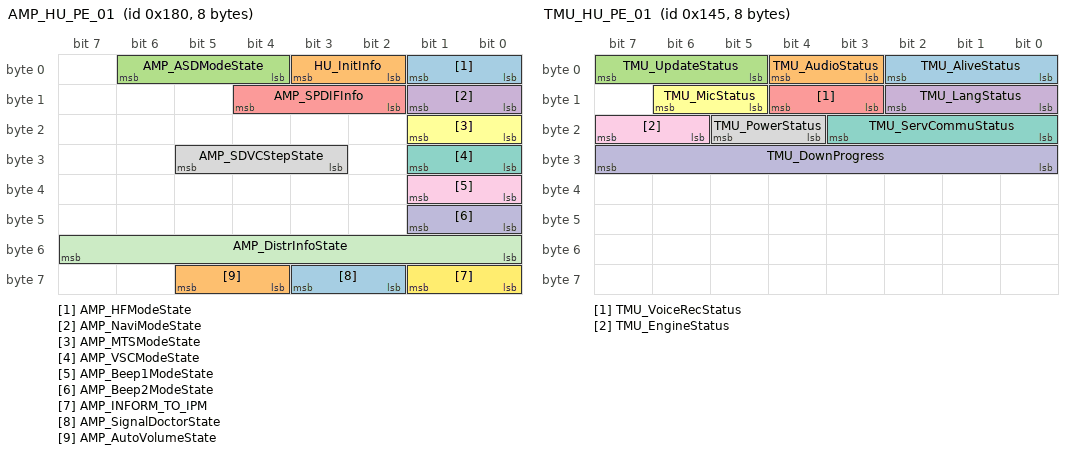
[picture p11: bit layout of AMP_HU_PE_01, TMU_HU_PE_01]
BO_ 384 AMP_HU_PE_01: 8 AMP
 SG_ AMP_HFModeState : 1|2@0+ (1,0) [0|0] ""  CLU,H_U
 SG_ HU_InitInfo : 3|2@0+ (1,0) [0|0] ""  CLU,H_U
 SG_ AMP_ASDModeState : 6|3@0+ (1,0) [0|0] ""  CLU,H_U
 SG_ AMP_NaviModeState : 9|2@0+ (1,0) [0|0] ""  CLU,H_U
 SG_ AMP_SPDIFInfo : 12|3@0+ (1,0) [0|0] ""  CLU,H_U
 SG_ AMP_MTSModeState : 17|2@0+ (1,0) [0|0] ""  CLU,H_U
 SG_ AMP_VSCModeState : 25|2@0+ (1,0) [0|0] ""  CLU,H_U
 SG_ AMP_SDVCStepState : 29|3@0+ (1,0) [0|0] ""  CLU,H_U
 SG_ AMP_Beep1ModeState : 33|2@0+ (1,0) [0|0] ""  CLU,H_U
 SG_ AMP_Beep2ModeState : 41|2@0+ (1,0) [0|0] ""  CLU,H_U
 SG_ AMP_DistrInfoState : 55|8@0+ (1,0) [0|0] ""  CLU,H_U
 SG_ AMP_INFORM_TO_IPM : 57|2@0+ (1,0) [0|0] ""  CGW,CLU,DATC,H_U,IPM
 SG_ AMP_SignalDoctorState : 59|2@0+ (1,0) [0|0] ""  H_U
 SG_ AMP_AutoVolumeState : 61|2@0+ (1,0) [0|0] ""  H_U

BO_ 1408 AMP_HU_P_01: 8 AMP
 SG_ AMP_SupportMute : 1|2@0+ (1,0) [0|0] ""  H_U
 SG_ AMP_SupportHFMode : 3|2@0+ (1,0) [0|0] ""  H_U
 SG_ AMP_SupportCfgBeep1 : 5|2@0+ (1,0) [0|0] ""  H_U
 SG_ AMP_SupportCfgBeep2 : 7|2@0+ (1,0) [0|0] ""  H_U
 SG_ AMP_SupportSpeedAdjust : 9|2@0+ (1,0) [0|0] ""  H_U
 SG_ AMP_SupportSurroundMode : 11|2@0+ (1,0) [0|0] ""  H_U
 SG_ AMP_SupportNaviMode : 13|2@0+ (1,0) [0|0] ""  H_U
 SG_ AMP_SupportMTSMode : 15|2@0+ (1,0) [0|0] ""  H_U
 SG_ AMP_SupportTopState : 17|2@0+ (1,0) [0|0] ""  H_U
 SG_ AMP_SupportBothLHDandRHD : 19|2@0+ (1,0) [0|0] ""  H_U
 SG_ AMP_SupportEQState : 21|2@0+ (1,0) [0|0] ""  H_U
 SG_ AMP_SupportVehicleID : 23|2@0+ (1,0) [0|0] ""  H_U
 SG_ AMP_SupportAudioSource : 25|2@0+ (1,0) [0|0] ""  H_U
 SG_ AMP_SupportSPDIFModeState : 27|2@0+ (1,0) [0|0] ""  H_U
 SG_ AMP_SupportRearSpMute : 29|2@0+ (1,0) [0|0] ""  H_U
 SG_ AMP_SupportVEQMode : 31|2@0+ (1,0) [0|0] ""  H_U
 SG_ AMP_MakerID : 39|8@0+ (1,0) [0|0] ""  H_U
 SG_ AMP_SupportASDMode : 41|2@0+ (1,0) [0|0] ""  H_U
 SG_ AMP_SupportBeatsMode : 43|2@0+ (1,0) [0|0] ""  H_U
 SG_ AMP_SupportVIPMode : 45|2@0+ (1,0) [0|0] ""  H_U
 SG_ AMP_SupportQLS : 47|2@0+ (1,0) [0|0] ""  H_U
 SG_ AMP_SupportSignalDoctor : 49|2@0+ (1,0) [0|0] ""  H_U
 SG_ AMP_SupportAutoVolume : 51|2@0+ (1,0) [0|0] ""  H_U
 SG_ AMP_SupportPESSMode : 53|2@0+ (1,0) [0|0] ""  H_U

BO_ 1920 TP_HU_PhyReq: 8 EDT
 SG_ Byte0_TCP_780 : 7|8@0+ (1,0) [0|0] ""  H_U
 SG_ Byte1_Data_780 : 15|8@0+ (1,0) [0|0] ""  H_U
 SG_ Byte2_Data_780 : 23|8@0+ (1,0) [0|0] ""  H_U
 SG_ Byte3_Data_780 : 31|8@0+ (1,0) [0|0] ""  H_U
 SG_ Byte4_Data_780 : 39|8@0+ (1,0) [0|0] ""  H_U
 SG_ Byte5_Data_780 : 47|8@0+ (1,0) [0|0] ""  H_U
 SG_ Byte6_Data_780 : 55|8@0+ (1,0) [0|0] ""  H_U
 SG_ Byte7_Data_780 : 63|8@0+ (1,0) [0|0] ""  H_U

BO_ 371 HU_TMU_PE_01: 8 H_U
 SG_ HU_AliveStatus : 1|2@0+ (1,0) [0|0] ""  CLU,CGW,TMU
 SG_ HU_DeviceType : 5|4@0+ (1,0) [0|0] ""  TMU
 SG_ HU_DistanceUnit : 7|2@0+ (1,0) [0|0] ""  TMU
 SG_ HU_AudAllocStatus : 9|2@0+ (1,0) [0|0] ""  TMU
 SG_ HU_PowerStatus : 12|3@0+ (1,0) [0|0] ""  TMU
 SG_ HU_BTCallStatus : 15|3@0+ (1,0) [0|0] ""  TMU
 SG_ HU_VoiceRecStatus : 17|2@0+ (1,0) [0|0] ""  TMU
 SG_ HU_LangStatus : 20|3@0+ (1,0) [0|0] ""  TMU

BO_ 369 HU_Car_PE_01: 8 H_U
 SG_ HU_VehiclePwr : 3|4@0+ (1,0) [0|0] ""  AMP,ASD,AVM,CCP,CLOCK,CLU,CUBIS,DATC,FHCU,IPM,KBD,KMA_TMU,MON,RRC,RSE_L,RSE_R,TMU

BO_ 1392 HU_TMU_P_01: 8 H_U
 SG_ HU_GPS_Signal : 7|64@0+ (1,0) [0|0] ""  TMU

BO_ 112 HU_AMP_E_09: 8 H_U
 SG_ AMP_Beep1VolumeStep : 7|8@0+ (1,0) [0|0] ""  AMP
 SG_ AMP_Beep1Frequency : 15|16@0+ (1,0) [0|0] ""  AMP
 SG_ AMP_Beep1Ch_OutputMask : 31|16@0+ (1,0) [0|0] ""  AMP
 SG_ AMP_Beep1DurationOn : 47|8@0+ (1,0) [0|0] ""  AMP
 SG_ AMP_Beep1DurationOff : 55|8@0+ (1,0) [0|0] ""  AMP
 SG_ AMP_Beep1NumberOfCycles : 63|8@0+ (1,0) [0|0] ""  AMP

BO_ 1390 GW_CLU_P: 8 CLU
 SG_ C_VehicleSpeed : 7|8@0+ (1,0) [0|254] ""  H_U,IBOX
 SG_ C_Odometer : 15|24@0+ (1,0) [0|999999] ""  H_U,IBOX

BO_ 363 GW_IPM_PE_2: 8 CLU
 SG_ C_DRVUnlockState : 1|2@0+ (1,0) [0|0] ""  CUBIS,TMU
 SG_ C_ASTUnlockState : 3|2@0+ (1,0) [0|0] ""  CUBIS,TMU
 SG_ C_RLUnlockstate : 5|2@0+ (1,0) [0|0] ""  CUBIS,TMU
 SG_ C_RRUnlockState : 7|2@0+ (1,0) [0|0] ""  CUBIS,TMU
 SG_ C_VehicleInfoTMU : 9|2@0+ (1,0) [0|0] ""  CUBIS,TMU
 SG_ C_Engine_Status : 11|2@0+ (1,0) [0|0] ""  CUBIS,TMU
 SG_ C_TMULockFeedBack : 23|2@0+ (1,0) [0|0] ""  CUBIS,TMU

BO_ 362 GW_IPM_PE_1: 8 CLU
 SG_ C_AV_Tail : 1|2@0+ (1,0) [0|0] ""  AMP,CCP,CLOCK,CLU,HUD,H_U,IBOX,RRC,RSE_L
 SG_ C_ParkingBrakeSW : 3|2@0+ (1,0) [0|0] ""  H_U
 SG_ C_RKECMD : 7|4@0+ (1,0) [0|0] ""  H_U
 SG_ C_BAState : 9|2@0+ (1,0) [0|0] ""  H_U,IBOX
 SG_ C_IGNSW : 14|3@0+ (1,0) [0|0] ""  AMP,AVM,CUBIS,EDT,H_U,MON,RRC,SWRC
 SG_ C_CountryCfg : 18|3@0+ (1,0) [0|0] ""  AVM,H_U
 SG_ C_AltL : 25|2@0+ (1,0) [0|0] ""  H_U
 SG_ C_TailLampActivity : 27|2@0+ (1,0) [0|0] ""  AMP,CCP,CLOCK,HUD,H_U,IBOX,RRC,RSE_L,SWRC
 SG_ RearSW_RSELockOnOff : 29|2@0+ (1,0) [0|0] ""  H_U,IBOX
 SG_ C_TMULockFeedBack : 31|2@0+ (1,0) [0|0] ""  CUBIS,TMU
 SG_ C_SMKTeleCrankingState : 33|2@0+ (1,0) [0|0] ""  H_U,IBOX
 SG_ C_SMKTeleCrankingFailRes : 35|2@0+ (1,0) [0|0] ""  H_U,IBOX
 SG_ C_RKECMD_GEN2 : 39|3@0+ (1,0) [0|0] ""  H_U,IBOX
 SG_ C_Acu_CshAct : 41|2@0+ (1,0) [0|0] ""  H_U,IBOX
 SG_ C_IntTailAct : 43|2@0+ (1,0) [0|0] ""  AMP,CCP,CLOCK,CLU,HUD,H_U,IBOX,RRC,RSE_L
 SG_ C_PassiveAccessUnlock : 47|3@0+ (1,0) [0|0] ""  H_U,IBOX
 SG_ Lca_IndLeft : 49|2@0+ (1,0) [0|0] ""  H_U
 SG_ FL_SndWarn : 51|2@0+ (1,0) [0|0] ""  AMP
 SG_ FR_SndWarn : 53|2@0+ (1,0) [0|0] ""  AMP
 SG_ Lca_IndRight : 55|2@0+ (1,0) [0|0] ""  H_U
 SG_ RCTA_IndLeft : 57|2@0+ (1,0) [0|0] ""  H_U
 SG_ RL_SndWarn : 59|2@0+ (1,0) [0|0] ""  AMP
 SG_ RR_SndWarn : 61|2@0+ (1,0) [0|0] ""  AMP
 SG_ RCTA_IndRight : 63|2@0+ (1,0) [0|0] ""  H_U

BO_ 361 GW_CHASSIS_PE_1: 8 CLU
 SG_ C_Inhibit_State : 3|4@0+ (1,0) [0|0] ""  AVM,H_U
 SG_ C_P_BrakeStatus : 5|2@0+ (1,0) [0|0] ""  AVM,H_U
 SG_ C_Clu_AltLStatus : 7|2@0+ (1,0) [0|0] ""  AVM,H_U

BO_ 359 GW_WARNING_PE_01: 8 CLU
 SG_ Spas_BEEP_Alarm : 3|4@0+ (1,0) [0|0] ""  AMP
 SG_ Spas_Audio_VolumeDown : 5|2@0+ (1,0) [0|0] ""  AMP
 SG_ Spas_Spkr_Flh_Alarm : 9|2@0+ (1,0) [0|0] ""  AMP,H_U
 SG_ Spas_Spkr_Fcnt_Alarm : 11|2@0+ (1,0) [0|0] ""  AMP,H_U
 SG_ Spas_Spkr_Frh_Alarm : 13|2@0+ (1,0) [0|0] ""  AMP,H_U
 SG_ Spas_Spkr_Rlh_Alarm : 17|2@0+ (1,0) [0|0] ""  AMP,H_U
 SG_ Spas_Spkr_Rcnt_Alarm : 19|2@0+ (1,0) [0|0] ""  AMP,H_U
 SG_ Spas_Spkr_Rrh_Alarm : 21|2@0+ (1,0) [0|0] ""  AMP,H_U
 SG_ Lkas_SysStatus : 27|4@0+ (1,0) [0|0] ""  AMP,H_U
 SG_ Lkas_LH_Warning : 29|2@0+ (1,0) [0|0] ""  AMP,H_U
 SG_ Lkas_RH_Warning : 31|2@0+ (1,0) [0|0] ""  AMP,H_U
 SG_ Spas_Spkr_Level : 35|3@0+ (1,0) [0|0] ""  AMP
 SG_ Lkas_Audio_VolumeDown : 37|2@0+ (1,0) [0|0] ""  AMP,H_U
 SG_ Audio_VolumeDown : 39|2@0+ (1,0) [0|0] ""  AMP,H_U
 SG_ Pas_BEEP_Alarm : 43|4@0+ (1,0) [0|0] ""  AMP
 SG_ Pas_Audio_VolumeDown : 45|2@0+ (1,0) [0|0] ""  AMP,H_U
 SG_ Pas_Spkr_Level : 32|3@0+ (1,0) [0|0] ""  AMP
 SG_ Pas_Spkr_Flh_Alarm : 49|2@0+ (1,0) [0|0] ""  AMP,H_U
 SG_ Pas_Spkr_Fcnt_Alarm : 51|2@0+ (1,0) [0|0] ""  AMP,H_U
 SG_ Pas_Spkr_Frh_Alarm : 53|2@0+ (1,0) [0|0] ""  AMP,H_U
 SG_ Pas_Spkr_Rlh_Alarm : 57|2@0+ (1,0) [0|0] ""  AMP,H_U
 SG_ Pas_Spkr_Rcnt_Alarm : 59|2@0+ (1,0) [0|0] ""  AMP,H_U
 SG_ Pas_Spkr_Rrh_Alarm : 61|2@0+ (1,0) [0|0] ""  AMP,H_U

BO_ 1376 HU_TMU_P_02: 8 H_U
 SG_ HU_GPS_Signal2 : 7|8@0+ (2,0) [0|0] "Degree"  TMU
 SG_ HU_GPS_Signal3 : 9|2@0+ (1,0) [0|0] ""  TMU
 SG_ HU_GPS_Signal4 : 12|3@0+ (1,0) [0|0] ""  TMU

BO_ 93 DATC_HU_E_SYS: 8 CLU
 SG_ DATC_SWVerMajor : 7|8@0+ (1,0) [0|254] ""  H_U
 SG_ DATC_SWVerMinor : 15|8@0+ (1,0) [0|254] ""  H_U
 SG_ DATC_CANVerMajor : 23|8@0+ (1,0) [0|254] ""  H_U
 SG_ DATC_CANVerMinor : 31|8@0+ (1,0) [0|254] ""  H_U

BO_ 344 GW_CLU_PE: 8 CLU
 SG_ C_InhibitP : 1|2@0+ (1,0) [0|0] ""  H_U,IBOX
 SG_ C_InhibitR : 3|2@0+ (1,0) [0|0] ""  H_U,IBOX
 SG_ C_InhibitN : 5|2@0+ (1,0) [0|0] ""  H_U,IBOX
 SG_ C_InhibitD : 7|2@0+ (1,0) [0|0] ""  H_U,IBOX
 SG_ C_P_BrakeStatus : 9|2@0+ (1,0) [0|0] ""  H_U,IBOX
 SG_ C_Clu_AltLStatus : 11|2@0+ (1,0) [0|0] ""  H_U,IBOX
 SG_ CF_Clu_LowfuelWarning : 13|2@0+ (1,0) [0|0] ""  H_U,IBOX
 SG_ C_InhibitRMT : 15|2@0+ (1,0) [0|0] ""  H_U
 SG_ CF_SMKRKECmd : 18|3@0+ (1,0) [0|0] ""  H_U

BO_ 87 HU_E_02: 8 H_U
 SG_ NaviValidity : 1|2@0+ (1,0) [0|0] ""  CGW,CLU

BO_ 343 GW_WARNING_PE_02: 8 CLU
 SG_ CF_Lkas_TsrSlifOpt : 1|2@0+ (1,0) [0|3] ""  H_U
 SG_ CF_Lkas_TsrStatus : 3|2@0+ (1,0) [0|3] ""  H_U
 SG_ CF_Lkas_TsrAddinfo_Disp : 7|2@0+ (1,0) [0|3] ""  H_U
 SG_ CF_Lkas_TsrSpeed_Display : 15|8@0+ (1,0) [0|255] ""  H_U

BO_ 75 HU_AMP_E_12: 8 H_U
 SG_ AMP_EngOrderC2GainSet : 7|8@0+ (1,0) [0|0] ""  AMP
 SG_ AMP_EngOrderC4GainSet : 15|8@0+ (1,0) [0|0] ""  AMP
 SG_ AMP_EngOrderC6GainSet : 23|8@0+ (1,0) [0|0] ""  AMP
 SG_ AMP_APSBand0GainSet : 31|8@0+ (1,0) [0|0] ""  AMP
 SG_ AMP_APSBand1GainSet : 39|8@0+ (1,0) [0|0] ""  AMP
 SG_ AMP_APSBand2GainSet : 47|8@0+ (1,0) [0|0] ""  AMP
 SG_ AMP_APSBand3GainSet : 55|8@0+ (1,0) [0|0] ""  AMP
 SG_ AMP_APSBand4GainSet : 63|8@0+ (1,0) [0|0] ""  AMP

BO_ 74 HU_AMP_E_11: 8 H_U
 SG_ AMP_PESSMode : 1|2@0+ (1,0) [0|0] ""  AMP
 SG_ AMP_PESSDesignSet : 4|3@0+ (1,0) [0|0] ""  AMP
 SG_ AMP_PESSAPSSet : 7|3@0+ (1,0) [0|0] ""  AMP
 SG_ AMP_PESSVolumeSet : 15|8@0+ (1,0) [0|0] ""  AMP

BO_ 1864 TP_AMP_EDT: 8 AMP
 SG_ Byte0_TCP_748 : 7|8@0+ (1,0) [0|0] ""  EDT
 SG_ Byte1_Data_748 : 15|8@0+ (1,0) [0|0] ""  EDT
 SG_ Byte2_Data_748 : 23|8@0+ (1,0) [0|0] ""  EDT
 SG_ Byte3_Data_748 : 31|8@0+ (1,0) [0|0] ""  EDT
 SG_ Byte4_Data_748 : 39|8@0+ (1,0) [0|0] ""  EDT
 SG_ Byte5_Data_748 : 47|8@0+ (1,0) [0|0] ""  EDT
 SG_ Byte6_Data_748 : 55|8@0+ (1,0) [0|0] ""  EDT
 SG_ Byte7_Data_748 : 63|8@0+ (1,0) [0|0] ""  EDT

BO_ 327 TMU_HU_PE_03: 8 TMU
 SG_ TMU_TbT_TurnIcon : 7|8@0+ (1,0) [0|0] ""  H_U
 SG_ TMU_TbT_CountDownBar : 11|4@0+ (1,0) [0|0] ""  H_U
 SG_ TMU_TbT_Distance_Unit : 13|2@0+ (1,0) [0|0] ""  H_U
 SG_ TMU_TbT_DestDistance_Unit : 15|2@0+ (1,0) [0|0] ""  H_U
 SG_ TMU_TbT_DistanceLo : 27|4@0+ (1,0) [0|0] ""  H_U
 SG_ TMU_TbT_DistanceHi : 23|12@0+ (1,0) [0|0] ""  H_U
 SG_ TMU_TbT_DestDistanceLo : 43|4@0+ (1,0) [0|0] ""  H_U
 SG_ TMU_TbT_DestDistanceHi : 39|12@0+ (1,0) [0|0] ""  H_U
 SG_ TMU_TbT_ExpectRemainHour : 55|8@0+ (1,0) [0|0] ""  H_U
 SG_ TMU_TbT_ExpectRemainMin : 61|6@0+ (1,0) [0|0] ""  H_U

BO_ 326 TMU_HU_PE_02: 8 TMU
 SG_ TMU_CallStatus : 3|4@0+ (1,0) [0|0] ""  H_U
 SG_ TMU_CallType : 6|3@0+ (1,0) [0|0] ""  H_U
 SG_ TMU_CDMA_Streng : 11|4@0+ (1,0) [0|0] ""  H_U
 SG_ TMU_PacketStatus : 13|2@0+ (1,0) [0|0] ""  H_U
 SG_ TMU_TalkTimeHour : 20|5@0+ (1,0) [0|0] ""  H_U
 SG_ TMU_TalkTimeMinute : 29|6@0+ (1,0) [0|0] ""  H_U
 SG_ TMU_TalkTimeSecond : 37|6@0+ (1,0) [0|0] ""  H_U

BO_ 325 TMU_HU_PE_01: 8 TMU
 SG_ TMU_AliveStatus : 2|3@0+ (1,0) [0|0] ""  H_U
 SG_ TMU_AudioStatus : 4|2@0+ (1,0) [0|0] ""  H_U
 SG_ TMU_UpdateStatus : 7|3@0+ (1,0) [0|0] ""  H_U
 SG_ TMU_LangStatus : 10|3@0+ (1,0) [0|0] ""  H_U
 SG_ TMU_VoiceRecStatus : 12|2@0+ (1,0) [0|0] ""  H_U
 SG_ TMU_MicStatus : 14|2@0+ (1,0) [0|0] ""  H_U
 SG_ TMU_ServCommuStatus : 19|4@0+ (1,0) [0|0] ""  H_U
 SG_ TMU_PowerStatus : 21|2@0+ (1,0) [0|0] ""  H_U
 SG_ TMU_EngineStatus : 23|2@0+ (1,0) [0|0] ""  H_U
 SG_ TMU_DownProgress : 31|8@0+ (1,0) [0|0] ""  H_U

BO_ 69 TMU_HU_E_04: 8 TMU
 SG_ TMU_eCall : 1|2@0+ (1,0) [0|0] ""  H_U

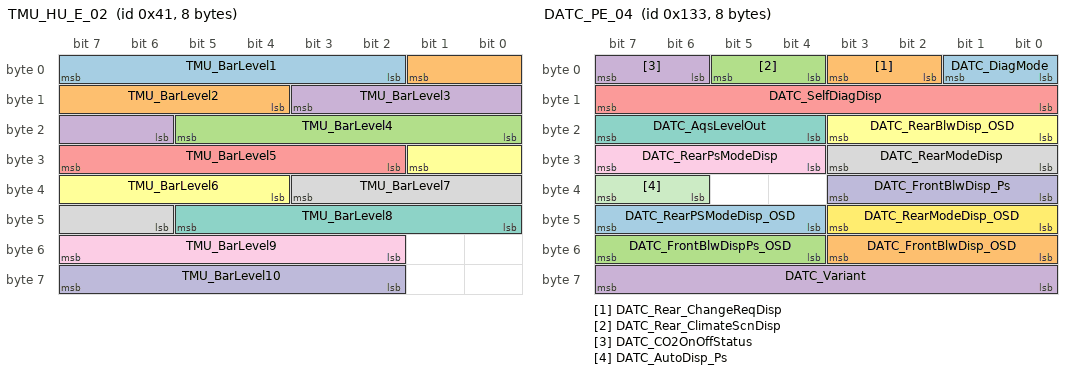
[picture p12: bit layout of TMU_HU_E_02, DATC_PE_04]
BO_ 65 TMU_HU_E_02: 8 TMU
 SG_ TMU_BarLevel1 : 7|6@0+ (1,0) [0|0] ""  H_U
 SG_ TMU_BarLevel2 : 1|6@0+ (1,0) [0|0] ""  H_U
 SG_ TMU_BarLevel4 : 21|6@0+ (1,0) [0|0] ""  H_U
 SG_ TMU_BarLevel3 : 11|6@0+ (1,0) [0|0] ""  H_U
 SG_ TMU_BarLevel5 : 31|6@0+ (1,0) [0|0] ""  H_U
 SG_ TMU_BarLevel6 : 25|6@0+ (1,0) [0|0] ""  H_U
 SG_ TMU_BarLevel8 : 45|6@0+ (1,0) [0|0] ""  H_U
 SG_ TMU_BarLevel7 : 35|6@0+ (1,0) [0|0] ""  H_U
 SG_ TMU_BarLevel9 : 55|6@0+ (1,0) [0|0] ""  H_U
 SG_ TMU_BarLevel10 : 63|6@0+ (1,0) [0|0] ""  H_U

BO_ 1344 TMU_HU_P_01: 8 TMU
 SG_ TMU_Arrow : 3|2@0+ (1,0) [0|0] ""  H_U
 SG_ TMU_ReFill_Info : 5|2@0+ (1,0) [0|0] ""  H_U
 SG_ TMU_AverageMPG : 1|10@0+ (1,0) [0|0] ""  H_U
 SG_ TMU_TotalMPG : 23|10@0+ (1,0) [0|0] ""  H_U
 SG_ TMU_RewardStar : 37|14@0+ (1,0) [0|0] ""  H_U

BO_ 62 HU_Navi_E_00: 8 H_U
 SG_ Navi_SLIF_SpdUnit : 1|2@0+ (1,0) [0|0] ""  CGW,CLU,HUD
 SG_ Navi_SLIF_Frwinfo : 4|3@0+ (1,0) [0|0] ""  CGW,CLU,HUD
 SG_ Navi_SLIF_LinkClass : 7|3@0+ (1,0) [0|0] ""  CGW,CLU,HUD
 SG_ Navi_SLIF_SpdLimit : 15|8@0+ (1,0) [1|254] ""  CGW,CLU,HUD
 SG_ Navi_SLIFMapSource : 29|4@0+ (1,0) [0|8] ""  CGW,CLU,HUD
 SG_ Navi_SLIF_CountryCode : 23|10@0+ (1,0) [0|0] ""  CGW,CLU,HUD

BO_ 52 HU_DATC_E_02: 8 H_U
 SG_ HU_DATC_DrTempUpDn : 1|2@0+ (1,0) [0|0] ""  CGW,CLU,DATC,IPM
 SG_ HU_DATC_PsTempUpDn : 3|2@0+ (1,0) [0|0] ""  CGW,CLU,DATC,IPM
 SG_ HU_DATC_RlTempUpDn : 5|2@0+ (1,0) [0|0] ""  CGW,CLU,DATC,IPM
 SG_ HU_DATC_RrTempUpDn : 7|2@0+ (1,0) [0|0] ""  CGW,CLU,DATC,IPM
 SG_ HU_DATC_MainBlower : 11|4@0+ (1,0) [0|0] ""  CGW,CLU,DATC,IPM
 SG_ HU_DATC_SubBlower : 15|4@0+ (1,0) [0|0] ""  CGW,CLU,DATC,IPM
 SG_ HU_DATC_RearBlower : 19|4@0+ (1,0) [0|0] ""  CGW,CLU,DATC,IPM
 SG_ HU_DATCRearPsModeSet : 23|4@0+ (1,0) [0|0] ""  CGW,CLU
 SG_ HU_DATC_FrontModeSet : 27|4@0+ (1,0) [0|0] ""  CGW,CLU,DATC,IPM
 SG_ HU_DATC_RearModeSet : 31|4@0+ (1,0) [0|0] ""  CGW,CLU,DATC,IPM
 SG_ HU_DATC_AutoSet : 33|2@0+ (1,0) [0|0] ""  CGW,CLU,DATC,IPM
 SG_ HU_DATC_OffReq : 35|2@0+ (1,0) [0|0] ""  CGW,CLU,DATC,IPM
 SG_ HU_DATC_IntakeSet : 37|2@0+ (1,0) [0|0] ""  CGW,CLU,DATC,IPM
 SG_ HU_DATC_RearOnOffSet : 39|2@0+ (1,0) [0|0] ""  CGW,CLU,DATC,IPM
 SG_ HU_DATC_AcSet : 41|2@0+ (1,0) [0|0] ""  CGW,CLU,DATC,IPM
 SG_ HU_DATC_AqsSet : 43|2@0+ (1,0) [0|0] ""  CGW,CLU,DATC,IPM
 SG_ HU_DATC_FrontDefog : 45|2@0+ (1,0) [0|0] ""  CGW,CLU,DATC,IPM
 SG_ HU_DATC_RearDefog : 47|2@0+ (1,0) [0|0] ""  CGW,CLU,DATC,IPM
 SG_ HU_DATC_ZoneControl : 49|2@0+ (1,0) [0|0] ""  CGW,CLU,DATC,IPM
 SG_ HU_DATC_CO2Set : 51|2@0+ (1,0) [0|0] ""  CGW,CLU,DATC,IPM
 SG_ DATC_SmartVentOnOffSet : 53|2@0+ (1,0) [0|0] ""  CGW,CLU,DATC,IPM
 SG_ DATC_ADSOnOffSet : 55|2@0+ (1,0) [0|0] ""  CGW,CLU
 SG_ HU_DATC_RearAutoDisp : 57|2@0+ (1,0) [0|0] ""  CGW,CLU
 SG_ HU_DATC_RearOffDisp : 59|2@0+ (1,0) [0|0] ""  CGW,CLU

BO_ 308 DATC_PE_05: 8 CLU
 SG_ DATC_PwrInfo : 3|4@0+ (1,0) [0|0] ""  AMP,AVM,CUBIS,H_U,MON
 SG_ DATC_AltL : 5|2@0+ (1,0) [0|0] ""  H_U,MON
 SG_ DATC_CarInfo : 7|2@0+ (1,0) [0|0] ""  H_U
 SG_ DATC_ParkingBrake : 9|2@0+ (1,0) [0|0] ""  H_U
 SG_ DATC_LowFuelWarn : 11|2@0+ (1,0) [0|0] ""  H_U
 SG_ DATC_Rear_Off_Disp : 13|2@0+ (1,0) [0|0] ""  H_U,MON
 SG_ DATC_Rear_AutoDisp : 15|2@0+ (1,0) [0|0] ""  H_U,MON
 SG_ DATC_Rear_BlowerDisp : 19|4@0+ (1,0) [0|0] ""  H_U,MON
 SG_ DATC_DrSeatWarmerDisp : 22|3@0+ (1,0) [0|0] ""  H_U,MON
 SG_ DATC_SyncDisp : 27|4@0+ (1,0) [0|0] ""  H_U,MON
 SG_ DATC_RearDispCtrl : 31|4@0+ (1,0) [0|0] ""  H_U,MON
 SG_ DATC_RearDrModeDisp : 35|4@0+ (1,0) [0|0] ""  H_U
 SG_ DATC_PsSeatWarmerDisp : 38|3@0+ (1,0) [0|0] ""  H_U,MON
 SG_ DATC_DrVentSeatDisp : 42|3@0+ (1,0) [0|0] ""  H_U,MON
 SG_ DATC_PSVentSeatDisp : 46|3@0+ (1,0) [0|0] ""  H_U,MON
 SG_ DATC_RrDefLed : 49|2@0+ (1,0) [0|0] ""  H_U,MON
 SG_ DATC_SmartVentOnOffStatus : 51|2@0+ (1,0) [0|0] ""  H_U
 SG_ DATC_ADSOnOffStatus : 53|2@0+ (1,0) [0|0] ""  H_U
 SG_ DATC_AcDisp_OSD : 55|2@0+ (1,0) [0|0] ""  H_U
 SG_ DATC_PsModeDisp_OSD : 59|4@0+ (1,0) [0|0] ""  H_U
 SG_ DATC_ModeDisp_OSD : 63|4@0+ (1,0) [0|0] ""  H_U

BO_ 307 DATC_PE_04: 8 CLU
 SG_ DATC_DiagMode : 1|2@0+ (1,0) [0|0] ""  H_U,IBOX,MON
 SG_ DATC_Rear_ChangeReqDisp : 3|2@0+ (1,0) [0|0] ""  H_U,IBOX,MON
 SG_ DATC_Rear_ClimateScnDisp : 5|2@0+ (1,0) [0|0] ""  H_U,IBOX,MON
 SG_ DATC_CO2OnOffStatus : 7|2@0+ (1,0) [0|0] ""  H_U
 SG_ DATC_SelfDiagDisp : 15|8@0+ (1,0) [0|0] ""  H_U,IBOX,MON
 SG_ DATC_RearBlwDisp_OSD : 19|4@0+ (1,0) [0|0] ""  H_U
 SG_ DATC_AqsLevelOut : 23|4@0+ (1,0) [0|0] ""  H_U,IBOX,MON
 SG_ DATC_RearModeDisp : 27|4@0+ (1,0) [0|0] ""  H_U
 SG_ DATC_RearPsModeDisp : 31|4@0+ (1,0) [0|0] ""  H_U
 SG_ DATC_FrontBlwDisp_Ps : 35|4@0+ (1,0) [0|0] ""  H_U
 SG_ DATC_AutoDisp_Ps : 39|2@0+ (1,0) [0|0] ""  H_U
 SG_ DATC_RearModeDisp_OSD : 43|4@0+ (1,0) [0|0] ""  H_U
 SG_ DATC_RearPSModeDisp_OSD : 47|4@0+ (1,0) [0|0] ""  H_U
 SG_ DATC_FrontBlwDisp_OSD : 51|4@0+ (1,0) [0|0] ""  H_U
 SG_ DATC_FrontBlwDispPs_OSD : 55|4@0+ (1,0) [0|0] ""  H_U
 SG_ DATC_Variant : 63|8@0+ (1,0) [0|0] ""  H_U,IBOX,MON

BO_ 306 DATC_PE_03: 8 CLU
 SG_ DATC_ModeDisp : 3|4@0+ (1,0) [0|0] ""  H_U,IBOX
 SG_ DATC_TempUnit : 5|2@0+ (1,0) [0|0] ""  H_U,IBOX
 SG_ DATC_AutoDisp : 9|2@0+ (1,0) [0|0] ""  H_U,IBOX
 SG_ DATC_IntakeDisp : 11|2@0+ (1,0) [0|0] ""  H_U,IBOX
 SG_ DATC_ChangeReqDisp : 13|2@0+ (1,0) [0|0] ""  H_U,IBOX
 SG_ DATC_AcDisp : 17|2@0+ (1,0) [0|0] ""  H_U,IBOX
 SG_ DATC_AqsDisp : 19|2@0+ (1,0) [0|0] ""  H_U,IBOX
 SG_ DATC_ClimateScnDisp : 21|2@0+ (1,0) [0|0] ""  H_U,IBOX
 SG_ DATC_DualDisp : 25|2@0+ (1,0) [0|0] ""  H_U,IBOX
 SG_ DATC_OffDisp : 27|2@0+ (1,0) [0|0] ""  H_U,IBOX
 SG_ DATC_OpSts : 30|3@0+ (1,0) [0|0] ""  H_U,IBOX
 SG_ DATC_RearManual : 33|2@0+ (1,0) [0|0] ""  H_U,MON
 SG_ DATC_FrDefLed : 37|2@0+ (1,0) [0|0] ""  H_U
 SG_ DATC_SmartVentDisp : 39|2@0+ (1,0) [0|0] ""  H_U
 SG_ DATC_AutoDefogBlink : 41|2@0+ (1,0) [0|0] ""  H_U,IBOX
 SG_ DATC_ADSDisp : 43|2@0+ (1,0) [0|0] ""  H_U
 SG_ DATC_IonClean : 45|2@0+ (1,0) [0|0] ""  H_U,IBOX
 SG_ DATC_CO2Warning : 47|2@0+ (1,0) [0|0] ""  H_U,IBOX
 SG_ DATC_SubBlowerDisp : 51|4@0+ (1,0) [0|0] ""  H_U,MON
 SG_ DATC_BeepReq : 55|4@0+ (1,0) [0|0] ""  H_U,KBD,MON
 SG_ DATC_MainBlowerDisp : 59|4@0+ (1,0) [0|0] ""  H_U,IBOX
 SG_ DATC_PsModeDisp : 63|4@0+ (1,0) [0|0] ""  H_U,IBOX

BO_ 1329 DATC_P_02: 8 CLU
 SG_ DATC_AmbientTemp_C : 7|8@0+ (1,0) [0|0] ""  H_U,MON
 SG_ DATC_AmbientTemp_F : 23|8@0+ (1,0) [0|0] ""  H_U,MON

BO_ 305 DATC_PE_02: 8 CLU
 SG_ DATC_DrTempDispC : 7|8@0+ (0.5,14) [15|32] "C"  H_U,IBOX,MON
 SG_ DATC_Rear_DrTempDispC : 15|8@0+ (0.5,14) [15|32] "C"  H_U,IBOX,MON
 SG_ DATC_DrTempDispF : 23|8@0+ (1,56) [58|90] "F"  H_U,IBOX,MON
 SG_ DATC_Rear_DrTempDispF : 31|8@0+ (1,56) [58|90] "F"  H_U,IBOX,MON
 SG_ DATC_PsTempDispC : 39|8@0+ (0.5,14) [15|32] "C"  H_U,IBOX,MON
 SG_ Datc_RearPsTempDispC : 47|8@0+ (0.5,14) [15|32] "C"  H_U,IBOX,MON
 SG_ DATC_PsTempDispF : 55|8@0+ (1,56) [58|90] "F"  H_U,IBOX,MON
 SG_ DATC_RearPsTempDispF : 63|8@0+ (1,56) [58|90] "F"  H_U,IBOX,MON

BO_ 304 DATC_PE_01: 8 CLU
 SG_ DATC_Type : 7|8@0+ (1,0) [0|0] ""  H_U,MON
 SG_ DATC_VerMMMajor : 15|8@0+ (1,0) [0|0] ""  H_U,MON
 SG_ DATC_VerMMMinor : 23|8@0+ (1,0) [0|0] ""  H_U,MON
 SG_ DATC_VerBDFMajor : 31|8@0+ (1,0) [0|0] ""  H_U,MON
 SG_ DATC_VerBDMinor : 39|8@0+ (1,0) [0|0] ""  H_U,MON
 SG_ DATC_VerCSMajor : 47|8@0+ (1,0) [0|0] ""  H_U,MON
 SG_ DATC_VerCSMinor : 55|8@0+ (1,0) [0|0] ""  H_U,MON

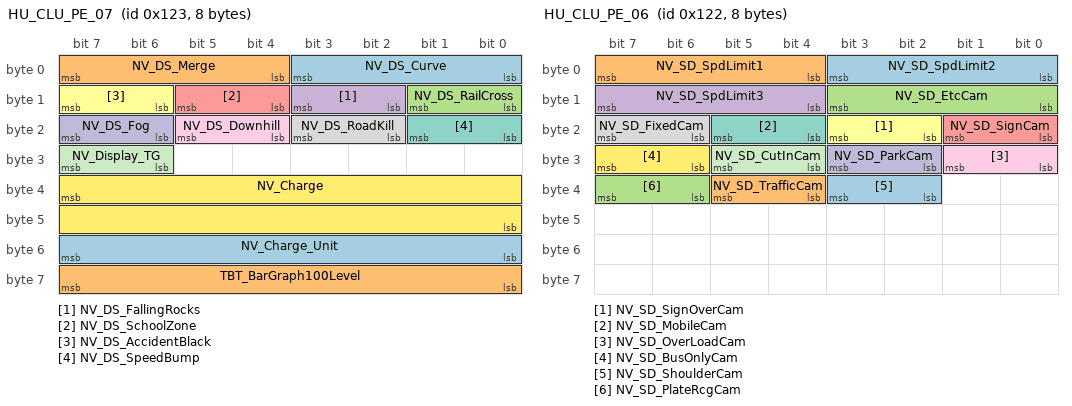
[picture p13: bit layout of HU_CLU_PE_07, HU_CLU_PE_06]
BO_ 291 HU_CLU_PE_07: 8 H_U
 SG_ NV_DS_Curve : 3|4@0+ (1,0) [0|0] ""  CLU
 SG_ NV_DS_Merge : 7|4@0+ (1,0) [0|0] ""  CLU
 SG_ NV_DS_RailCross : 9|2@0+ (1,0) [0|0] ""  CLU
 SG_ NV_DS_FallingRocks : 11|2@0+ (1,0) [0|0] ""  CLU
 SG_ NV_DS_SchoolZone : 13|2@0+ (1,0) [0|0] ""  CLU
 SG_ NV_DS_AccidentBlack : 15|2@0+ (1,0) [0|0] ""  CLU
 SG_ NV_DS_SpeedBump : 17|2@0+ (1,0) [0|0] ""  CLU
 SG_ NV_DS_RoadKill : 19|2@0+ (1,0) [0|0] ""  CLU
 SG_ NV_DS_Downhill : 21|2@0+ (1,0) [0|0] ""  CLU
 SG_ NV_DS_Fog : 23|2@0+ (1,0) [0|0] ""  CLU
 SG_ NV_Display_TG : 31|2@0+ (1,0) [0|0] ""  CLU,HUD
 SG_ NV_Charge : 39|16@0+ (1,0) [0|0] ""  CLU,HUD
 SG_ NV_Charge_Unit : 55|8@0+ (1,0) [0|0] ""  CLU,HUD
 SG_ TBT_BarGraph100Level : 63|8@0+ (1,0) [0|100] "%"  CLU,HUD

BO_ 290 HU_CLU_PE_06: 8 H_U
 SG_ NV_SD_SpdLimit2 : 3|4@0+ (10,0) [0|0] "km/h"  CLU
 SG_ NV_SD_SpdLimit1 : 7|4@0+ (10,0) [0|0] "km/h"  CLU
 SG_ NV_SD_EtcCam : 11|4@0+ (1,0) [0|0] ""  CLU
 SG_ NV_SD_SpdLimit3 : 15|4@0+ (10,0) [0|0] "km/h"  CLU
 SG_ NV_SD_SignCam : 17|2@0+ (1,0) [0|0] ""  CLU
 SG_ NV_SD_SignOverCam : 19|2@0+ (1,0) [0|0] ""  CLU
 SG_ NV_SD_MobileCam : 21|2@0+ (1,0) [0|0] ""  CLU
 SG_ NV_SD_FixedCam : 23|2@0+ (1,0) [0|0] ""  CLU
 SG_ NV_SD_OverLoadCam : 25|2@0+ (1,0) [0|0] ""  CLU
 SG_ NV_SD_ParkCam : 27|2@0+ (1,0) [0|0] ""  CLU
 SG_ NV_SD_CutInCam : 29|2@0+ (1,0) [0|0] ""  CLU
 SG_ NV_SD_BusOnlyCam : 31|2@0+ (1,0) [0|0] ""  CLU
 SG_ NV_SD_ShoulderCam : 35|2@0+ (1,0) [0|0] ""  CLU
 SG_ NV_SD_TrafficCam : 37|2@0+ (1,0) [0|0] ""  CLU
 SG_ NV_SD_PlateRcgCam : 39|2@0+ (1,0) [0|0] ""  CLU

BO_ 286 HU_CLU_PE_10: 8 H_U
 SG_ Navi_TBTInfo : 63|8@0+ (1,0) [0|0] ""  CGW,CLU

BO_ 29 CLU_HU_E_00: 8 CLU
 SG_ SYS_CLUVer : 7|16@0+ (1,0) [0|0] ""  CUBIS,H_U
 SG_ CLU_ClockInfoReq : 17|2@0+ (1,0) [0|0] ""  H_U
 SG_ CLU_DateInfoReq : 19|2@0+ (1,0) [0|0] ""  H_U

BO_ 27 AMP_HU_E_00: 8 AMP
 SG_ SYS_AMPVer : 7|16@0+ (1,0) [0|0] ""  H_U

BO_ 23 HU_IPM_E_00: 8 H_U
 SG_ C_ADrLNValueSet : 2|3@0+ (1,0) [0|0] ""  DATC,IPM
 SG_ C_ADrUNValueSet : 5|3@0+ (1,0) [0|0] ""  DATC,IPM
 SG_ SYS_Ver_Req : 7|2@0+ (1,0) [0|0] ""  AMP,AVM,CLU,CUBIS,DATC,IPM
 SG_ C_IMSRValueReq : 9|2@0+ (1,0) [0|0] ""  DATC,IPM
 SG_ C_PSMNValueSet : 11|2@0+ (1,0) [0|0] ""  DATC,IPM
 SG_ C_SCMNValueSet : 13|2@0+ (1,0) [0|0] ""  DATC,IPM
 SG_ C_ADrLURValueReq : 15|2@0+ (1,0) [0|0] ""  DATC,IPM
 SG_ C_ABuzzerNValueSet : 17|2@0+ (1,0) [0|0] ""  DATC,IPM
 SG_ C_AlarmRValueReq : 19|2@0+ (1,0) [0|0] ""  DATC,IPM
 SG_ C_ArmWKeyNValueSet : 21|2@0+ (1,0) [0|0] ""  DATC,IPM
 SG_ C_TwUnRValueReq : 23|2@0+ (1,0) [0|0] ""  DATC,IPM
 SG_ C_TwUnNValueSet : 25|2@0+ (1,0) [0|0] ""  DATC,IPM
 SG_ C_AutoMRFoldRValueReq : 27|2@0+ (1,0) [0|0] ""  DATC,IPM
 SG_ C_AutoMRFoldNValueSet : 29|2@0+ (1,0) [0|0] ""  DATC,IPM
 SG_ C_ADrLRValueReq : 31|2@0+ (1,0) [0|0] ""  DATC,IPM
 SG_ C_ArmWKeyRValueReq : 33|2@0+ (1,0) [0|0] ""  DATC,IPM
 SG_ C_ABuzzerRValueReq : 35|2@0+ (1,0) [0|0] ""  DATC,IPM
 SG_ C_ADrURValueReq : 37|2@0+ (1,0) [0|0] ""  DATC,IPM
 SG_ C_PSMRValueReq : 39|2@0+ (1,0) [0|0] ""  DATC,IPM
 SG_ C_SCMRValueReq : 47|2@0+ (1,0) [0|0] ""  DATC,IPM

BO_ 277 HU_CLU_PE_02: 8 H_U
 SG_ TBT_Display_Type : 7|8@0+ (1,0) [0|0] ""  CLU,HUD
 SG_ TBT_Side_Street : 15|16@0+ (1,0) [0|0] ""  CLU,HUD
 SG_ TBT_Direction : 31|8@0+ (1,0) [0|0] ""  CLU,HUD
 SG_ TBT_Distance_Turn_Point : 39|16@0+ (1,0) [0|0] "m"  CLU,HUD
 SG_ TBT_Combined_Side_Street : 51|4@0+ (1,0) [0|0] ""  CLU,HUD
 SG_ TBT_Scale : 55|4@0+ (1,0) [0|0] ""  CLU,HUD
 SG_ TBT_DistancetoTurnPoint : 59|4@0+ (1,0) [0|0] "times"  CLU,HUD
 SG_ TBT_Bar_Graph_Level : 63|4@0+ (10,0) [0|100] ""  CLU,HUD

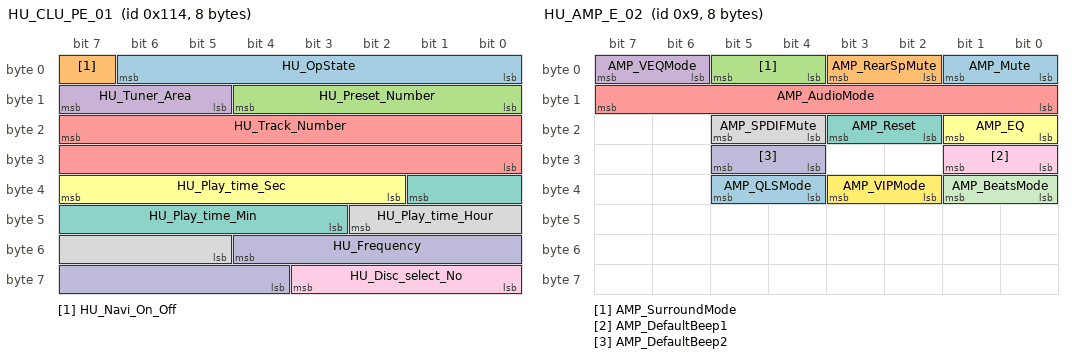
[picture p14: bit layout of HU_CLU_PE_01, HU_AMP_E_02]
BO_ 276 HU_CLU_PE_01: 8 H_U
 SG_ HU_OpState : 6|7@0+ (1,0) [0|0] ""  AMP,CLU
 SG_ HU_Navi_On_Off : 7|1@0+ (1,0) [0|0] ""  CLU,HUD
 SG_ HU_Preset_Number : 12|5@0+ (1,1) [1|30] ""  AMP,CLU
 SG_ HU_Tuner_Area : 15|3@0+ (1,0) [0|0] ""  AMP,CLU
 SG_ HU_Track_Number : 23|16@0+ (1,0) [0|0] ""  CLU
 SG_ HU_Play_time_Sec : 39|6@0+ (1,0) [0|0] ""  CLU
 SG_ HU_Play_time_Min : 33|7@0+ (1,0) [0|0] ""  CLU
 SG_ HU_Play_time_Hour : 42|6@0+ (1,0) [0|0] ""  CLU
 SG_ HU_Disc_select_No : 59|4@0+ (1,0) [0|0] ""  CLU
 SG_ HU_Frequency : 52|9@0+ (1,0) [0|0] ""  AMP,CLU

BO_ 17 HU_AMP_E_10: 8 H_U
 SG_ AMP_Beep2VolumeStep : 7|8@0+ (1,0) [0|0] ""  AMP
 SG_ AMP_Beep2Frequency : 15|16@0+ (1,0) [0|0] ""  AMP
 SG_ AMP_Beep2Ch_OutputMask : 31|16@0+ (1,0) [0|0] ""  AMP
 SG_ AMP_Beep2DurationOn : 47|8@0+ (1,0) [0|0] ""  AMP
 SG_ AMP_Beep2DurationOff : 55|8@0+ (1,0) [0|0] ""  AMP
 SG_ AMP_Beep2NumberOfCycles : 63|8@0+ (1,0) [0|0] ""  AMP

BO_ 15 HU_AMP_E_08: 8 H_U
 SG_ AMP_MainVolumeSet : 7|8@0+ (1,0) [0|0] ""  AMP
 SG_ AMP_BalanceSet : 15|8@0+ (1,0) [0|0] ""  AMP
 SG_ AMP_FadeSet : 23|8@0+ (1,0) [0|0] ""  AMP
 SG_ AMP_BassSet : 31|8@0+ (1,0) [0|0] ""  AMP
 SG_ AMP_MidSet : 39|8@0+ (1,0) [0|0] ""  AMP
 SG_ AMP_TrebleSet : 47|8@0+ (1,0) [0|0] ""  AMP

BO_ 14 HU_AMP_E_07: 8 H_U
 SG_ AMP_HFVolumeStep : 7|8@0+ (1,0) [0|0] ""  AMP
 SG_ AMP_HFMainAudioCut : 15|8@0+ (1,0) [0|0] ""  AMP
 SG_ AMP_HFChannelOutputMask : 23|16@0+ (1,0) [0|0] ""  AMP
 SG_ AMP_HFChannelMuteMask : 39|16@0+ (1,0) [0|0] ""  AMP

BO_ 13 HU_AMP_E_06: 8 H_U
 SG_ AMP_MTSVolumeStep : 7|8@0+ (1,0) [0|0] ""  AMP
 SG_ AMP_MTSMainAudioCut : 15|8@0+ (1,0) [0|0] ""  AMP
 SG_ AMP_MTSChannelOutputMask : 23|16@0+ (1,0) [0|0] ""  AMP
 SG_ AMP_MTSChannelMuteMask : 39|16@0+ (1,0) [0|0] ""  AMP

BO_ 12 HU_AMP_E_05: 8 H_U
 SG_ AMP_NaviVolumeStep : 7|8@0+ (1,0) [0|0] ""  AMP
 SG_ AMP_NaviMainAudioCut : 15|8@0+ (1,0) [0|0] ""  AMP
 SG_ AMP_NaviChannelOutputMask : 23|16@0+ (1,0) [0|0] ""  AMP
 SG_ AMP_NaviChannelMuteMask : 39|16@0+ (1,0) [0|0] ""  AMP

BO_ 11 HU_AMP_E_04: 8 H_U
 SG_ AMP_Drive : 1|2@0+ (1,0) [0|0] ""  AMP
 SG_ AMP_ConvertibleTop : 5|2@0+ (1,0) [0|0] ""  AMP

BO_ 10 HU_AMP_E_03: 8 H_U
 SG_ AMP_CrtVehicleID : 7|8@0+ (1,0) [0|0] ""  AMP
 SG_ AMP_SPDIFMode : 11|4@0+ (1,0) [0|0] ""  AMP
 SG_ AMP_VersionReq : 17|2@0+ (1,0) [0|0] ""  AMP
 SG_ AMP_UpdateStart : 25|2@0+ (1,0) [0|0] ""  AMP
 SG_ AMP_UpdateEnd : 33|2@0+ (1,0) [0|0] ""  AMP

BO_ 9 HU_AMP_E_02: 8 H_U
 SG_ AMP_Mute : 1|2@0+ (1,0) [0|0] ""  AMP
 SG_ AMP_RearSpMute : 3|2@0+ (1,0) [0|0] ""  AMP
 SG_ AMP_SurroundMode : 5|2@0+ (1,0) [0|0] ""  AMP
 SG_ AMP_VEQMode : 7|2@0+ (1,0) [0|0] ""  AMP
 SG_ AMP_AudioMode : 15|8@0+ (1,0) [0|0] ""  AMP
 SG_ AMP_EQ : 17|2@0+ (1,0) [0|0] ""  AMP
 SG_ AMP_Reset : 19|2@0+ (1,0) [0|0] ""  AMP
 SG_ AMP_SPDIFMute : 21|2@0+ (1,0) [0|0] ""  AMP
 SG_ AMP_DefaultBeep1 : 25|2@0+ (1,0) [0|0] ""  AMP
 SG_ AMP_DefaultBeep2 : 29|2@0+ (1,0) [0|0] ""  AMP
 SG_ AMP_BeatsMode : 33|2@0+ (1,0) [0|0] ""  AMP
 SG_ AMP_VIPMode : 35|2@0+ (1,0) [0|0] ""  AMP
 SG_ AMP_QLSMode : 37|2@0+ (1,0) [0|0] ""  AMP

BO_ 1288 HU_CLU_P_02: 8 H_U
 SG_ NV_TIME_TYPE : 3|4@0+ (1,0) [0|0] ""  CLU
 SG_ NV_Hour : 15|8@0+ (1,0) [0|0] ""  CLU
 SG_ NV_Min : 23|8@0+ (1,0) [0|0] ""  CLU

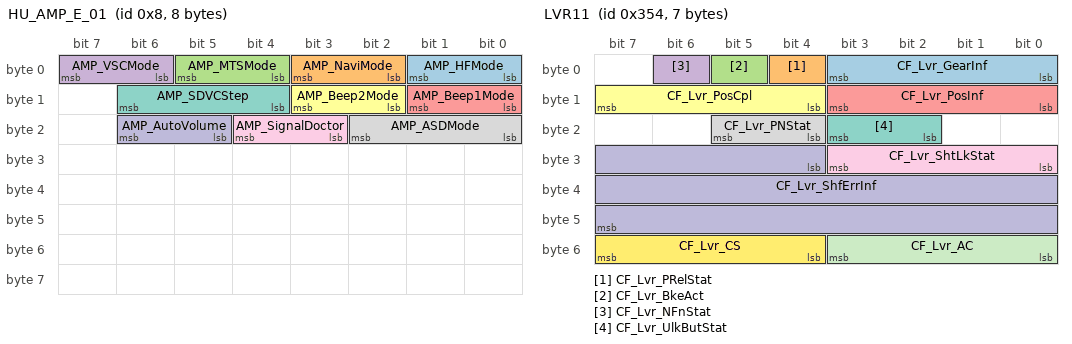
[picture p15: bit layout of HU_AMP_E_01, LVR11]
BO_ 8 HU_AMP_E_01: 8 H_U
 SG_ AMP_HFMode : 1|2@0+ (1,0) [0|0] ""  AMP
 SG_ AMP_NaviMode : 3|2@0+ (1,0) [0|0] ""  AMP
 SG_ AMP_MTSMode : 5|2@0+ (1,0) [0|0] ""  AMP
 SG_ AMP_VSCMode : 7|2@0+ (1,0) [0|0] ""  AMP
 SG_ AMP_Beep1Mode : 9|2@0+ (1,0) [0|0] ""  AMP
 SG_ AMP_Beep2Mode : 11|2@0+ (1,0) [0|0] ""  AMP
 SG_ AMP_SDVCStep : 14|3@0+ (1,0) [0|0] ""  AMP
 SG_ AMP_ASDMode : 18|3@0+ (1,0) [0|0] ""  AMP
 SG_ AMP_SignalDoctor : 20|2@0+ (1,0) [0|0] ""  AMP
 SG_ AMP_AutoVolume : 22|2@0+ (1,0) [0|0] ""  AMP

BO_ 1287 HU_CLU_P_01: 8 H_U
 SG_ NV_DistToTurn_F1 : 3|4@0+ (1,0) [0|0] ""  CLU
 SG_ NV_DistToTurn_Unit : 7|4@0+ (1,0) [0|0] ""  CLU
 SG_ NV_DistToTurn_F3 : 11|4@0+ (1,0) [0|0] ""  CLU
 SG_ NV_DistToTurn_F2 : 15|4@0+ (1,0) [0|0] ""  CLU
 SG_ NV_DistToTurn_I1 : 23|16@0+ (1,0) [0|0] ""  CLU
 SG_ NV_DistToTurn_I2 : 39|16@0+ (1,0) [0|0] ""  CLU
 SG_ NV_DistToTurn_I3 : 55|16@0+ (1,0) [0|0] ""  CLU

BO_ 1286 HU_CLU_P_00: 8 H_U
 SG_ NV_EstDist_F : 3|4@0+ (1,0) [0|0] ""  CLU,HUD
 SG_ NV_EstDist_Unit : 7|4@0+ (1,0) [0|0] ""  CLU,HUD
 SG_ NV_EstHour : 15|8@0+ (1,0) [0|0] ""  CLU,HUD
 SG_ NV_EstMin : 23|8@0+ (1,0) [0|0] ""  CLU,HUD
 SG_ NV_Azimuth : 31|8@0+ (1,0) [0|0] ""  CLU,HUD
 SG_ NV_EstDist_I : 39|16@0+ (1,0) [0|0] ""  CLU,HUD
 SG_ NV_EstimTimeType : 49|2@0+ (1,0) [0|0] ""  CGW,CLU,HUD
 SG_ NV_EstimTimeFormat : 51|2@0+ (1,0) [0|0] ""  CGW,CLU,HUD

BO_ 1284 HU_AMP_P_01: 8 H_U
 SG_ HU_VehicleSpeed : 7|8@0+ (1,0) [0|0] ""  AMP
 SG_ AMP_SetMaxMainVolStep : 9|2@0+ (1,0) [0|0] ""  AMP
 SG_ AMP_LKASWarningOn : 21|2@0+ (1,0) [0|0] ""  AMP
 SG_ AMP_BSDWarningOn : 23|2@0+ (1,0) [0|0] ""  AMP

BO_ 256 HU_MON_PE_01: 8 H_U
 SG_ HU_Type : 7|8@0+ (1,0) [0|0] ""  AMP,CGW,CLU,HUD,KMA_TMU
 SG_ HU_VerMajor : 15|8@0+ (1,0) [0|0] ""  AMP,CLU,KMA_TMU,MON
 SG_ HU_VerMinor : 23|8@0+ (1,0) [0|0] ""  AMP,CLU,KMA_TMU,MON
 SG_ HU_DistributeInfo : 31|8@0+ (1,0) [0|0] ""  AMP,CGW,CLU,KMA_TMU,MON,RRC
 SG_ HU_SubVerMajor : 39|8@0+ (1,0) [0|0] ""  AMP,MON
 SG_ HU_SubVerMinor : 47|8@0+ (1,0) [0|0] ""  AMP,MON
 SG_ HU_SDARSVersion : 55|8@0+ (1,0) [0|0] ""  AMP,MON
 SG_ HU_AdasSupport : 58|3@0+ (1,0) [0|0] ""  CGW,CLU

BO_ 1092 NM_CLOCK: 8 CLOCK
 SG_ Destination_CLOCK : 7|8@0+ (1,0) [0|0] ""  HUD,H_U,DATC,CCP,KMA_TMU,CUBIS,TMU,IPM,RSE_R,RRC,CGW,RSE_L,AMP,EDT,SWRC,IBOX,CLU,FHCU,ASD,MON,AVM,KBD
 SG_ NMSleepFlag_CLOCK : 13|2@0+ (1,0) [0|0] ""  HUD,H_U,DATC,CCP,KMA_TMU,CUBIS,TMU,IPM,RSE_R,RRC,CGW,RSE_L,AMP,EDT,SWRC,IBOX,CLU,FHCU,ASD,MON,AVM,KBD
 SG_ NMCommandCode_CLOCK : 10|3@0+ (1,0) [0|0] ""  HUD,H_U,DATC,CCP,KMA_TMU,CUBIS,TMU,IPM,RSE_R,RRC,CGW,RSE_L,AMP,EDT,SWRC,IBOX,CLU,FHCU,ASD,MON,AVM,KBD

BO_ 1108 NM_HUD: 8 HUD
 SG_ Destination_HUD : 7|8@0+ (1,0) [0|0] ""  CLOCK,H_U,DATC,CCP,KMA_TMU,CUBIS,TMU,IPM,RSE_R,RRC,CGW,RSE_L,AMP,EDT,SWRC,IBOX,CLU,FHCU,ASD,MON,AVM,KBD
 SG_ NMSleepFlag_HUD : 13|2@0+ (1,0) [0|0] ""  CLOCK,H_U,DATC,CCP,KMA_TMU,CUBIS,TMU,IPM,RSE_R,RRC,CGW,RSE_L,AMP,EDT,SWRC,IBOX,CLU,FHCU,ASD,MON,AVM,KBD
 SG_ NMCommandCode_HUD : 10|3@0+ (1,0) [0|0] ""  CLOCK,H_U,DATC,CCP,KMA_TMU,CUBIS,TMU,IPM,RSE_R,RRC,CGW,RSE_L,AMP,EDT,SWRC,IBOX,CLU,FHCU,ASD,MON,AVM,KBD

BO_ 1088 NM_H_U: 8 H_U
 SG_ Destination_H_U : 7|8@0+ (1,0) [0|0] ""  CLOCK,HUD,DATC,CCP,KMA_TMU,CUBIS,TMU,IPM,RSE_R,RRC,CGW,RSE_L,AMP,EDT,SWRC,IBOX,CLU,FHCU,ASD,MON,AVM,KBD
 SG_ NMSleepFlag_H_U : 13|2@0+ (1,0) [0|0] ""  CLOCK,HUD,DATC,CCP,KMA_TMU,CUBIS,TMU,IPM,RSE_R,RRC,CGW,RSE_L,AMP,EDT,SWRC,IBOX,CLU,FHCU,ASD,MON,AVM,KBD
 SG_ NMCommandCode_H_U : 10|3@0+ (1,0) [0|0] ""  CLOCK,HUD,DATC,CCP,KMA_TMU,CUBIS,TMU,IPM,RSE_R,RRC,CGW,RSE_L,AMP,EDT,SWRC,IBOX,CLU,FHCU,ASD,MON,AVM,KBD

BO_ 1091 NM_DATC: 8 DATC
 SG_ Destination_DATC : 7|8@0+ (1,0) [0|0] ""  CLOCK,HUD,H_U,CCP,KMA_TMU,CUBIS,TMU,IPM,RSE_R,RRC,CGW,RSE_L,AMP,EDT,SWRC,IBOX,CLU,FHCU,ASD,MON,AVM,KBD
 SG_ NMSleepFlag_DATC : 13|2@0+ (1,0) [0|0] ""  CLOCK,HUD,H_U,CCP,KMA_TMU,CUBIS,TMU,IPM,RSE_R,RRC,CGW,RSE_L,AMP,EDT,SWRC,IBOX,CLU,FHCU,ASD,MON,AVM,KBD
 SG_ NMCommandCode_DATC : 10|3@0+ (1,0) [0|0] ""  CLOCK,HUD,H_U,CCP,KMA_TMU,CUBIS,TMU,IPM,RSE_R,RRC,CGW,RSE_L,AMP,EDT,SWRC,IBOX,CLU,FHCU,ASD,MON,AVM,KBD

BO_ 1105 NM_CCP: 8 CCP
 SG_ Destination_CCP : 7|8@0+ (1,0) [0|0] ""  CLOCK,HUD,H_U,DATC,KMA_TMU,CUBIS,TMU,IPM,RSE_R,RRC,CGW,RSE_L,AMP,EDT,SWRC,IBOX,CLU,FHCU,ASD,MON,AVM,KBD
 SG_ NMSleepFlag_CCP : 13|2@0+ (1,0) [0|0] ""  CLOCK,HUD,H_U,DATC,KMA_TMU,CUBIS,TMU,IPM,RSE_R,RRC,CGW,RSE_L,AMP,EDT,SWRC,IBOX,CLU,FHCU,ASD,MON,AVM,KBD
 SG_ NMCommandCode_CCP : 10|3@0+ (1,0) [0|0] ""  CLOCK,HUD,H_U,DATC,KMA_TMU,CUBIS,TMU,IPM,RSE_R,RRC,CGW,RSE_L,AMP,EDT,SWRC,IBOX,CLU,FHCU,ASD,MON,AVM,KBD

BO_ 1100 NM_KMA_TMU: 8 KMA_TMU
 SG_ Destination_KMA_TMU : 7|8@0+ (1,0) [0|0] ""  CLOCK,HUD,H_U,DATC,CCP,CUBIS,TMU,IPM,RSE_R,RRC,CGW,RSE_L,AMP,EDT,SWRC,IBOX,CLU,FHCU,ASD,MON,AVM,KBD
 SG_ NMSleepFlag_KMA_TMU : 13|2@0+ (1,0) [0|0] ""  CLOCK,HUD,H_U,DATC,CCP,CUBIS,TMU,IPM,RSE_R,RRC,CGW,RSE_L,AMP,EDT,SWRC,IBOX,CLU,FHCU,ASD,MON,AVM,KBD
 SG_ NMCommandCode_KMA_TMU : 10|3@0+ (1,0) [0|0] ""  CLOCK,HUD,H_U,DATC,CCP,CUBIS,TMU,IPM,RSE_R,RRC,CGW,RSE_L,AMP,EDT,SWRC,IBOX,CLU,FHCU,ASD,MON,AVM,KBD

BO_ 1098 NM_CUBIS: 8 CUBIS
 SG_ Destination_CUBIS : 7|8@0+ (1,0) [0|0] ""  CLOCK,HUD,H_U,DATC,CCP,KMA_TMU,TMU,IPM,RSE_R,RRC,CGW,RSE_L,AMP,EDT,SWRC,IBOX,CLU,FHCU,ASD,MON,AVM,KBD
 SG_ NMSleepFlag_CUBIS : 13|2@0+ (1,0) [0|0] ""  CLOCK,HUD,H_U,DATC,CCP,KMA_TMU,TMU,IPM,RSE_R,RRC,CGW,RSE_L,AMP,EDT,SWRC,IBOX,CLU,FHCU,ASD,MON,AVM,KBD
 SG_ NMCommandCode_CUBIS : 10|3@0+ (1,0) [0|0] ""  CLOCK,HUD,H_U,DATC,CCP,KMA_TMU,TMU,IPM,RSE_R,RRC,CGW,RSE_L,AMP,EDT,SWRC,IBOX,CLU,FHCU,ASD,MON,AVM,KBD

BO_ 1099 NM_TMU: 8 TMU
 SG_ Destination_TMU : 7|8@0+ (1,0) [0|0] ""  CLOCK,HUD,H_U,DATC,CCP,KMA_TMU,CUBIS,IPM,RSE_R,RRC,CGW,RSE_L,AMP,EDT,SWRC,IBOX,CLU,FHCU,ASD,MON,AVM,KBD
 SG_ NMSleepFlag_TMU : 13|2@0+ (1,0) [0|0] ""  CLOCK,HUD,H_U,DATC,CCP,KMA_TMU,CUBIS,IPM,RSE_R,RRC,CGW,RSE_L,AMP,EDT,SWRC,IBOX,CLU,FHCU,ASD,MON,AVM,KBD
 SG_ NMCommandCode_TMU : 10|3@0+ (1,0) [0|0] ""  CLOCK,HUD,H_U,DATC,CCP,KMA_TMU,CUBIS,IPM,RSE_R,RRC,CGW,RSE_L,AMP,EDT,SWRC,IBOX,CLU,FHCU,ASD,MON,AVM,KBD

BO_ 1095 NM_IPM: 8 IPM
 SG_ Destination_IPM : 7|8@0+ (1,0) [0|0] ""  CLOCK,HUD,H_U,DATC,CCP,KMA_TMU,CUBIS,TMU,RSE_R,RRC,CGW,RSE_L,AMP,EDT,SWRC,IBOX,CLU,FHCU,ASD,MON,AVM,KBD
 SG_ NMSleepFlag_IPM : 13|2@0+ (1,0) [0|0] ""  CLOCK,HUD,H_U,DATC,CCP,KMA_TMU,CUBIS,TMU,RSE_R,RRC,CGW,RSE_L,AMP,EDT,SWRC,IBOX,CLU,FHCU,ASD,MON,AVM,KBD
 SG_ NMCommandCode_IPM : 10|3@0+ (1,0) [0|0] ""  CLOCK,HUD,H_U,DATC,CCP,KMA_TMU,CUBIS,TMU,RSE_R,RRC,CGW,RSE_L,AMP,EDT,SWRC,IBOX,CLU,FHCU,ASD,MON,AVM,KBD

BO_ 1107 NM_RSE_R: 8 RSE_R
 SG_ Destination_RSE_R : 7|8@0+ (1,0) [0|0] ""  CLOCK,HUD,H_U,DATC,CCP,KMA_TMU,CUBIS,TMU,IPM,RRC,CGW,RSE_L,AMP,EDT,SWRC,IBOX,CLU,FHCU,ASD,MON,AVM,KBD
 SG_ NMSleepFlag_RSE_R : 13|2@0+ (1,0) [0|0] ""  CLOCK,HUD,H_U,DATC,CCP,KMA_TMU,CUBIS,TMU,IPM,RRC,CGW,RSE_L,AMP,EDT,SWRC,IBOX,CLU,FHCU,ASD,MON,AVM,KBD
 SG_ NMCommandCode_RSE_R : 10|3@0+ (1,0) [0|0] ""  CLOCK,HUD,H_U,DATC,CCP,KMA_TMU,CUBIS,TMU,IPM,RRC,CGW,RSE_L,AMP,EDT,SWRC,IBOX,CLU,FHCU,ASD,MON,AVM,KBD

BO_ 1093 NM_RRC: 8 RRC
 SG_ Destination_RRC : 7|8@0+ (1,0) [0|0] ""  CLOCK,HUD,H_U,DATC,CCP,KMA_TMU,CUBIS,TMU,IPM,RSE_R,CGW,RSE_L,AMP,EDT,SWRC,IBOX,CLU,FHCU,ASD,MON,AVM,KBD
 SG_ NMSleepFlag_RRC : 13|2@0+ (1,0) [0|0] ""  CLOCK,HUD,H_U,DATC,CCP,KMA_TMU,CUBIS,TMU,IPM,RSE_R,CGW,RSE_L,AMP,EDT,SWRC,IBOX,CLU,FHCU,ASD,MON,AVM,KBD
 SG_ NMCommandCode_RRC : 10|3@0+ (1,0) [0|0] ""  CLOCK,HUD,H_U,DATC,CCP,KMA_TMU,CUBIS,TMU,IPM,RSE_R,CGW,RSE_L,AMP,EDT,SWRC,IBOX,CLU,FHCU,ASD,MON,AVM,KBD

BO_ 1109 NM_CGW: 8 CGW
 SG_ Destination_CGW : 7|8@0+ (1,0) [0|0] ""  CLOCK,HUD,H_U,DATC,CCP,KMA_TMU,CUBIS,TMU,IPM,RSE_R,RRC,RSE_L,AMP,EDT,SWRC,IBOX,CLU,FHCU,ASD,MON,AVM,KBD
 SG_ NMSleepFlag_CGW : 13|2@0+ (1,0) [0|0] ""  CLOCK,HUD,H_U,DATC,CCP,KMA_TMU,CUBIS,TMU,IPM,RSE_R,RRC,RSE_L,AMP,EDT,SWRC,IBOX,CLU,FHCU,ASD,MON,AVM,KBD
 SG_ NMCommandCode_CGW : 10|3@0+ (1,0) [0|0] ""  CLOCK,HUD,H_U,DATC,CCP,KMA_TMU,CUBIS,TMU,IPM,RSE_R,RRC,RSE_L,AMP,EDT,SWRC,IBOX,CLU,FHCU,ASD,MON,AVM,KBD

BO_ 1106 NM_RSE_L: 8 RSE_L
 SG_ Destination_RSE_L : 7|8@0+ (1,0) [0|0] ""  CLOCK,HUD,H_U,DATC,CCP,KMA_TMU,CUBIS,TMU,IPM,RSE_R,RRC,CGW,AMP,EDT,SWRC,IBOX,CLU,FHCU,ASD,MON,AVM,KBD
 SG_ NMSleepFlag_RSE_L : 13|2@0+ (1,0) [0|0] ""  CLOCK,HUD,H_U,DATC,CCP,KMA_TMU,CUBIS,TMU,IPM,RSE_R,RRC,CGW,AMP,EDT,SWRC,IBOX,CLU,FHCU,ASD,MON,AVM,KBD
 SG_ NMCommandCode_RSE_L : 10|3@0+ (1,0) [0|0] ""  CLOCK,HUD,H_U,DATC,CCP,KMA_TMU,CUBIS,TMU,IPM,RSE_R,RRC,CGW,AMP,EDT,SWRC,IBOX,CLU,FHCU,ASD,MON,AVM,KBD

BO_ 1096 NM_AMP: 8 AMP
 SG_ Destination_AMP : 7|8@0+ (1,0) [0|0] ""  CLOCK,HUD,H_U,DATC,CCP,KMA_TMU,CUBIS,TMU,IPM,RSE_R,RRC,CGW,RSE_L,EDT,SWRC,IBOX,CLU,FHCU,ASD,MON,AVM,KBD
 SG_ NMSleepFlag_AMP : 13|2@0+ (1,0) [0|0] ""  CLOCK,HUD,H_U,DATC,CCP,KMA_TMU,CUBIS,TMU,IPM,RSE_R,RRC,CGW,RSE_L,EDT,SWRC,IBOX,CLU,FHCU,ASD,MON,AVM,KBD
 SG_ NMCommandCode_AMP : 10|3@0+ (1,0) [0|0] ""  CLOCK,HUD,H_U,DATC,CCP,KMA_TMU,CUBIS,TMU,IPM,RSE_R,RRC,CGW,RSE_L,EDT,SWRC,IBOX,CLU,FHCU,ASD,MON,AVM,KBD

BO_ 1103 NM_EDT: 8 EDT
 SG_ Destination_EDT : 7|8@0+ (1,0) [0|0] ""  CLOCK,HUD,H_U,DATC,CCP,KMA_TMU,CUBIS,TMU,IPM,RSE_R,RRC,CGW,RSE_L,AMP,SWRC,IBOX,CLU,FHCU,ASD,MON,AVM,KBD
 SG_ NMSleepFlag_EDT : 13|2@0+ (1,0) [0|0] ""  CLOCK,HUD,H_U,DATC,CCP,KMA_TMU,CUBIS,TMU,IPM,RSE_R,RRC,CGW,RSE_L,AMP,SWRC,IBOX,CLU,FHCU,ASD,MON,AVM,KBD
 SG_ NMCommandCode_EDT : 10|3@0+ (1,0) [0|0] ""  CLOCK,HUD,H_U,DATC,CCP,KMA_TMU,CUBIS,TMU,IPM,RSE_R,RRC,CGW,RSE_L,AMP,SWRC,IBOX,CLU,FHCU,ASD,MON,AVM,KBD

BO_ 1110 NM_SWRC: 8 SWRC
 SG_ Destination_SWRC : 7|8@0+ (1,0) [0|0] ""  CLOCK,HUD,H_U,DATC,CCP,KMA_TMU,CUBIS,TMU,IPM,RSE_R,RRC,CGW,RSE_L,AMP,EDT,IBOX,CLU,FHCU,ASD,MON,AVM,KBD
 SG_ NMSleepFlag_SWRC : 13|2@0+ (1,0) [0|0] ""  CLOCK,HUD,H_U,DATC,CCP,KMA_TMU,CUBIS,TMU,IPM,RSE_R,RRC,CGW,RSE_L,AMP,EDT,IBOX,CLU,FHCU,ASD,MON,AVM,KBD
 SG_ NMCommandCode_SWRC : 10|3@0+ (1,0) [0|0] ""  CLOCK,HUD,H_U,DATC,CCP,KMA_TMU,CUBIS,TMU,IPM,RSE_R,RRC,CGW,RSE_L,AMP,EDT,IBOX,CLU,FHCU,ASD,MON,AVM,KBD

BO_ 1102 NM_IBOX: 8 IBOX
 SG_ Destination_IBOX : 7|8@0+ (1,0) [0|0] ""  CLOCK,HUD,H_U,DATC,CCP,KMA_TMU,CUBIS,TMU,IPM,RSE_R,RRC,CGW,RSE_L,AMP,EDT,SWRC,CLU,FHCU,ASD,MON,AVM,KBD
 SG_ NMSleepFlag_IBOX : 13|2@0+ (1,0) [0|0] ""  CLOCK,HUD,H_U,DATC,CCP,KMA_TMU,CUBIS,TMU,IPM,RSE_R,RRC,CGW,RSE_L,AMP,EDT,SWRC,CLU,FHCU,ASD,MON,AVM,KBD
 SG_ NMCommandCode_IBOX : 10|3@0+ (1,0) [0|0] ""  CLOCK,HUD,H_U,DATC,CCP,KMA_TMU,CUBIS,TMU,IPM,RSE_R,RRC,CGW,RSE_L,AMP,EDT,SWRC,CLU,FHCU,ASD,MON,AVM,KBD

BO_ 1101 NM_CLU: 8 CLU
 SG_ Destination_CLU : 7|8@0+ (1,0) [0|0] ""  CLOCK,HUD,H_U,DATC,CCP,KMA_TMU,CUBIS,TMU,IPM,RSE_R,RRC,CGW,RSE_L,AMP,EDT,SWRC,IBOX,FHCU,ASD,MON,AVM,KBD
 SG_ NMSleepFlag_CLU : 13|2@0+ (1,0) [0|0] ""  CLOCK,HUD,H_U,DATC,CCP,KMA_TMU,CUBIS,TMU,IPM,RSE_R,RRC,CGW,RSE_L,AMP,EDT,SWRC,IBOX,FHCU,ASD,MON,AVM,KBD
 SG_ NMCommandCode_CLU : 10|3@0+ (1,0) [0|0] ""  CLOCK,HUD,H_U,DATC,CCP,KMA_TMU,CUBIS,TMU,IPM,RSE_R,RRC,CGW,RSE_L,AMP,EDT,SWRC,IBOX,FHCU,ASD,MON,AVM,KBD

BO_ 1097 NM_FHCU: 8 FHCU
 SG_ Destination_FHCU : 7|8@0+ (1,0) [0|0] ""  CLOCK,HUD,H_U,DATC,CCP,KMA_TMU,CUBIS,TMU,IPM,RSE_R,RRC,CGW,RSE_L,AMP,EDT,SWRC,IBOX,CLU,ASD,MON,AVM,KBD
 SG_ NMSleepFlag_FHCU : 13|2@0+ (1,0) [0|0] ""  CLOCK,HUD,H_U,DATC,CCP,KMA_TMU,CUBIS,TMU,IPM,RSE_R,RRC,CGW,RSE_L,AMP,EDT,SWRC,IBOX,CLU,ASD,MON,AVM,KBD
 SG_ NMCommandCode_FHCU : 10|3@0+ (1,0) [0|0] ""  CLOCK,HUD,H_U,DATC,CCP,KMA_TMU,CUBIS,TMU,IPM,RSE_R,RRC,CGW,RSE_L,AMP,EDT,SWRC,IBOX,CLU,ASD,MON,AVM,KBD

BO_ 1094 NM_ASD: 8 ASD
 SG_ Destination_ASD : 7|8@0+ (1,0) [0|0] ""  CLOCK,HUD,H_U,DATC,CCP,KMA_TMU,CUBIS,TMU,IPM,RSE_R,RRC,CGW,RSE_L,AMP,EDT,SWRC,IBOX,CLU,FHCU,MON,AVM,KBD
 SG_ NMSleepFlag_ASD : 13|2@0+ (1,0) [0|0] ""  CLOCK,HUD,H_U,DATC,CCP,KMA_TMU,CUBIS,TMU,IPM,RSE_R,RRC,CGW,RSE_L,AMP,EDT,SWRC,IBOX,CLU,FHCU,MON,AVM,KBD
 SG_ NMCommandCode_ASD : 10|3@0+ (1,0) [0|0] ""  CLOCK,HUD,H_U,DATC,CCP,KMA_TMU,CUBIS,TMU,IPM,RSE_R,RRC,CGW,RSE_L,AMP,EDT,SWRC,IBOX,CLU,FHCU,MON,AVM,KBD

BO_ 1089 NM_MON: 8 MON
 SG_ Destination_MON : 7|8@0+ (1,0) [0|0] ""  CLOCK,HUD,H_U,DATC,CCP,KMA_TMU,CUBIS,TMU,IPM,RSE_R,RRC,CGW,RSE_L,AMP,EDT,SWRC,IBOX,CLU,FHCU,ASD,AVM,KBD
 SG_ NMSleepFlag_MON : 13|2@0+ (1,0) [0|0] ""  CLOCK,HUD,H_U,DATC,CCP,KMA_TMU,CUBIS,TMU,IPM,RSE_R,RRC,CGW,RSE_L,AMP,EDT,SWRC,IBOX,CLU,FHCU,ASD,AVM,KBD
 SG_ NMCommandCode_MON : 10|3@0+ (1,0) [0|0] ""  CLOCK,HUD,H_U,DATC,CCP,KMA_TMU,CUBIS,TMU,IPM,RSE_R,RRC,CGW,RSE_L,AMP,EDT,SWRC,IBOX,CLU,FHCU,ASD,AVM,KBD

BO_ 1104 NM_AVM: 8 AVM
 SG_ Destination_AVM : 7|8@0+ (1,0) [0|0] ""  CLOCK,HUD,H_U,DATC,CCP,KMA_TMU,CUBIS,TMU,IPM,RSE_R,RRC,CGW,RSE_L,AMP,EDT,SWRC,IBOX,CLU,FHCU,ASD,MON,KBD
 SG_ NMSleepFlag_AVM : 13|2@0+ (1,0) [0|0] ""  CLOCK,HUD,H_U,DATC,CCP,KMA_TMU,CUBIS,TMU,IPM,RSE_R,RRC,CGW,RSE_L,AMP,EDT,SWRC,IBOX,CLU,FHCU,ASD,MON,KBD
 SG_ NMCommandCode_AVM : 10|3@0+ (1,0) [0|0] ""  CLOCK,HUD,H_U,DATC,CCP,KMA_TMU,CUBIS,TMU,IPM,RSE_R,RRC,CGW,RSE_L,AMP,EDT,SWRC,IBOX,CLU,FHCU,ASD,MON,KBD

BO_ 1090 NM_KBD: 8 KBD
 SG_ Destination_KBD : 7|8@0+ (1,0) [0|0] ""  CLOCK,HUD,H_U,DATC,CCP,KMA_TMU,CUBIS,TMU,IPM,RSE_R,RRC,CGW,RSE_L,AMP,EDT,SWRC,IBOX,CLU,FHCU,ASD,MON,AVM
 SG_ NMSleepFlag_KBD : 13|2@0+ (1,0) [0|0] ""  CLOCK,HUD,H_U,DATC,CCP,KMA_TMU,CUBIS,TMU,IPM,RSE_R,RRC,CGW,RSE_L,AMP,EDT,SWRC,IBOX,CLU,FHCU,ASD,MON,AVM
 SG_ NMCommandCode_KBD : 10|3@0+ (1,0) [0|0] ""  CLOCK,HUD,H_U,DATC,CCP,KMA_TMU,CUBIS,TMU,IPM,RSE_R,RRC,CGW,RSE_L,AMP,EDT,SWRC,IBOX,CLU,FHCU,ASD,MON,AVM
###########################################################################################################################################################################################################################################################################

VERSION ""  hyundai_2015_ccan.dbc

NS_ :

BS_:

BU_: IAP ODS _4WD BCM HUD DATC MDPS AAF_Tester AEMC SMK _4WD EPB CUBIS MTS TMU EVP CGW TPMS LPI DI_BOX SPAS EMS LCA TCU IBOX FATC AFLS FPCM SCC AHLS AVM ABS SNV OPI PGS SAS AAF Dummy LDWS_LKAS LVR ESC PSB CLU ECS ACU REA

BO_ 852 LVR11: 7 LVR
 SG_ CF_Lvr_GearInf : 0|4@1+ (1.0,0.0) [0.0|15.0] ""  CLU,TCU
 SG_ CF_Lvr_PRelStat : 4|1@1+ (1.0,0.0) [0.0|1.0] ""  BCM,CLU,SMK,TCU
 SG_ CF_Lvr_BkeAct : 5|1@1+ (1.0,0.0) [0.0|1.0] ""  TCU
 SG_ CF_Lvr_NFnStat : 6|1@1+ (1.0,0.0) [0.0|1.0] ""  CLU
 SG_ CF_Lvr_PosInf : 8|4@1+ (1.0,0.0) [0.0|15.0] ""  TCU
 SG_ CF_Lvr_PosCpl : 12|4@1+ (1.0,0.0) [0.0|15.0] ""  TCU
 SG_ CF_Lvr_UlkButStat : 18|2@1+ (1.0,0.0) [0.0|3.0] ""  TCU
 SG_ CF_Lvr_PNStat : 20|2@1+ (1.0,0.0) [0.0|3.0] ""  CLU
 SG_ CF_Lvr_ShtLkStat : 24|4@1+ (1.0,0.0) [0.0|15.0] ""  TCU
 SG_ CF_Lvr_ShfErrInf : 28|20@1+ (1.0,0.0) [0.0|8191.0] ""  CLU,TCU
 SG_ CF_Lvr_AC : 48|4@1+ (1.0,0.0) [0.0|15.0] ""  TCU
 SG_ CF_Lvr_CS : 52|4@1+ (1.0,0.0) [0.0|15.0] ""  TCU

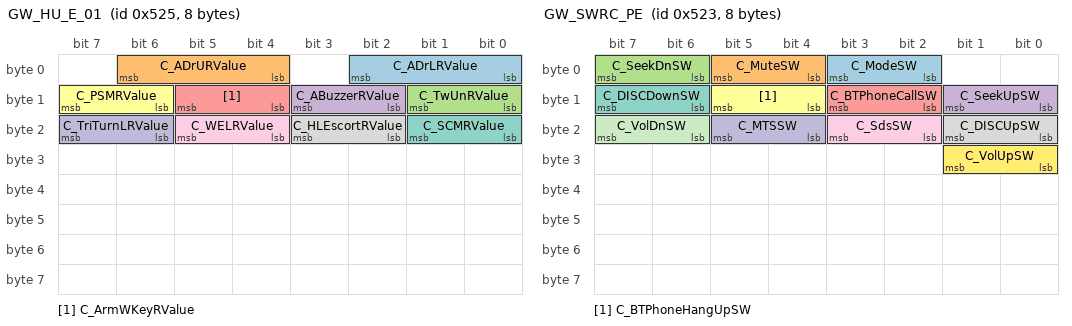
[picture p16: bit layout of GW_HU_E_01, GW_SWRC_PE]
BO_ 1317 GW_HU_E_01: 8 BCM
 SG_ C_ADrLRValue : 0|3@1+ (1.0,0.0) [0.0|7.0] ""  CLU
 SG_ C_ADrURValue : 4|3@1+ (1.0,0.0) [0.0|7.0] ""  CLU
 SG_ C_TwUnRValue : 8|2@1+ (1.0,0.0) [0.0|3.0] ""  CLU
 SG_ C_ABuzzerRValue : 10|2@1+ (1.0,0.0) [0.0|3.0] ""  CLU
 SG_ C_ArmWKeyRValue : 12|2@1+ (1.0,0.0) [0.0|3.0] ""  CLU
 SG_ C_PSMRValue : 14|2@1+ (1.0,0.0) [0.0|3.0] ""  CLU
 SG_ C_SCMRValue : 16|2@1+ (1.0,0.0) [0.0|3.0] ""  CLU
 SG_ C_HLEscortRValue : 18|2@1+ (1.0,0.0) [0.0|3.0] ""  CLU
 SG_ C_WELRValue : 20|2@1+ (1.0,0.0) [0.0|3.0] ""  CLU
 SG_ C_TriTurnLRValue : 22|2@1+ (1.0,0.0) [0.0|3.0] ""  CLU

BO_ 1316 GW_HU_E_00: 8 BCM
 SG_ C_ADrLUNValueConf : 0|2@1+ (1.0,0.0) [0.0|3.0] ""  CLU
 SG_ C_TwUnNValueConf : 2|2@1+ (1.0,0.0) [0.0|3.0] ""  CLU
 SG_ C_AlarmNValueConf : 4|2@1+ (1.0,0.0) [0.0|3.0] ""  CLU
 SG_ C_PSMNValueConf : 6|2@1+ (1.0,0.0) [0.0|3.0] ""  CLU
 SG_ C_SCMNValueConf : 8|2@1+ (1.0,0.0) [0.0|3.0] ""  CLU
 SG_ C_HLEscortNValueConf : 10|2@1+ (1.0,0.0) [0.0|3.0] ""  CLU
 SG_ C_WELNValueConf : 12|2@1+ (1.0,0.0) [0.0|3.0] ""  CLU
 SG_ C_TriTurnLNValueConf : 14|2@1+ (1.0,0.0) [0.0|3.0] ""  CLU

BO_ 1315 GW_SWRC_PE: 8 BCM
 SG_ C_ModeSW : 2|2@1+ (1.0,0.0) [0.0|3.0] ""  CLU
 SG_ C_MuteSW : 4|2@1+ (1.0,0.0) [0.0|3.0] ""  CLU
 SG_ C_SeekDnSW : 6|2@1+ (1.0,0.0) [0.0|3.0] ""  CLU
 SG_ C_SeekUpSW : 8|2@1+ (1.0,0.0) [0.0|3.0] ""  CLU
 SG_ C_BTPhoneCallSW : 10|2@1+ (1.0,0.0) [0.0|3.0] ""  CLU
 SG_ C_BTPhoneHangUpSW : 12|2@1+ (1.0,0.0) [0.0|3.0] ""  CLU
 SG_ C_DISCDownSW : 14|2@1+ (1.0,0.0) [0.0|3.0] ""  CLU
 SG_ C_DISCUpSW : 16|2@1+ (1.0,0.0) [0.0|3.0] ""  CLU
 SG_ C_SdsSW : 18|2@1+ (1.0,0.0) [0.0|3.0] ""  CLU
 SG_ C_MTSSW : 20|2@1+ (1.0,0.0) [0.0|3.0] ""  CLU
 SG_ C_VolDnSW : 22|2@1+ (1.0,0.0) [0.0|3.0] ""  CLU
 SG_ C_VolUpSW : 24|2@1+ (1.0,0.0) [0.0|3.0] ""  CLU

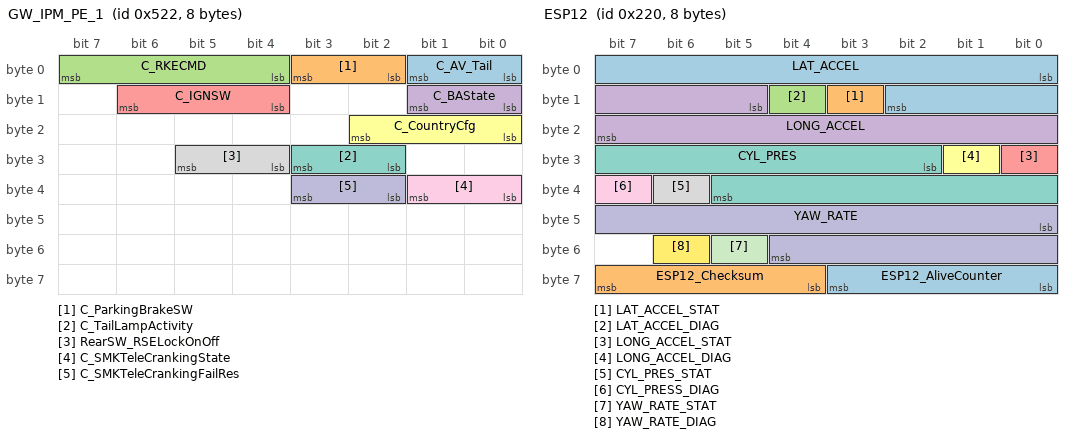
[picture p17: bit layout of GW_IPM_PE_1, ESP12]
BO_ 1314 GW_IPM_PE_1: 8 BCM
 SG_ C_AV_Tail : 0|2@1+ (1.0,0.0) [0.0|3.0] ""  CLU
 SG_ C_ParkingBrakeSW : 2|2@1+ (1.0,0.0) [0.0|3.0] ""  CLU
 SG_ C_RKECMD : 4|4@1+ (1.0,0.0) [0.0|15.0] ""  CLU
 SG_ C_BAState : 8|2@1+ (1.0,0.0) [0.0|3.0] ""  CLU
 SG_ C_IGNSW : 12|3@1+ (1.0,0.0) [0.0|7.0] ""  CLU
 SG_ C_CountryCfg : 16|3@1+ (1.0,0.0) [0.0|7.0] ""  CLU
 SG_ C_TailLampActivity : 26|2@1+ (1.0,0.0) [0.0|3.0] ""  CLU
 SG_ RearSW_RSELockOnOff : 28|2@1+ (1.0,0.0) [0.0|3.0] ""  CLU
 SG_ C_SMKTeleCrankingState : 32|2@1+ (1.0,0.0) [0.0|3.0] ""  CLU
 SG_ C_SMKTeleCrankingFailRes : 34|2@1+ (1.0,0.0) [0.0|3.0] ""  CLU

BO_ 1057 SCC12: 8 SCC
 SG_ CF_VSM_Prefill : 0|1@1+ (1.0,0.0) [0.0|1.0] ""  ESC
 SG_ CF_VSM_DecCmdAct : 1|1@1+ (1.0,0.0) [0.0|1.0] ""  ESC
 SG_ CF_VSM_HBACmd : 2|2@1+ (1.0,0.0) [0.0|3.0] ""  ESC
 SG_ CF_VSM_Warn : 4|2@1+ (1.0,0.0) [0.0|3.0] ""  CLU,ESC,IAP
 SG_ CF_VSM_Stat : 6|2@1+ (1.0,0.0) [0.0|3.0] ""  CLU,ESC,PSB
 SG_ CF_VSM_BeltCmd : 8|3@1+ (1.0,0.0) [0.0|7.0] ""  ESC,PSB
 SG_ ACCFailInfo : 11|2@1+ (1.0,0.0) [0.0|3.0] ""  CLU,CUBIS,ESC,IBOX
 SG_ ACCMode : 13|2@1+ (1.0,0.0) [0.0|3.0] ""  CLU,ESC,IBOX,TCU
 SG_ StopReq : 15|1@1+ (1.0,0.0) [0.0|1.0] ""  EPB,ESC
 SG_ CR_VSM_DecCmd : 16|8@1+ (0.01,0.0) [0.0|2.55] "g"  ESC
 SG_ aReqMax : 24|11@1+ (0.01,-10.23) [-10.23|10.24] "m/s^2"  EMS,ESC,TCU
 SG_ TakeOverReq : 35|1@1+ (1.0,0.0) [0.0|1.0] ""  CLU,ESC,TCU
 SG_ PreFill : 36|1@1+ (1.0,0.0) [0.0|1.0] ""  ESC,TCU
 SG_ aReqMin : 37|11@1+ (0.01,-10.23) [-10.23|10.24] "m/s^2"  EMS,ESC,TCU
 SG_ CF_VSM_ConfMode : 48|2@1+ (1.0,0.0) [0.0|3.0] ""  CLU,ESC
 SG_ AEB_Failinfo : 50|2@1+ (1.0,0.0) [0.0|3.0] ""  CLU,ESC
 SG_ AEB_Status : 52|2@1+ (1.0,0.0) [0.0|3.0] ""  CLU,ESC
 SG_ AEB_CmdAct : 54|1@1+ (1.0,0.0) [0.0|1.0] ""  ESC
 SG_ AEB_StopReq : 55|1@1+ (1.0,0.0) [0.0|1.0] ""  CLU,ESC
 SG_ CR_VSM_Alive : 56|4@1+ (1.0,0.0) [0.0|15.0] ""  ESC,PSB
 SG_ CR_VSM_ChkSum : 60|4@1+ (1.0,0.0) [0.0|15.0] ""  ESC,PSB

BO_ 1313 GW_DDM_PE: 8 BCM
 SG_ C_DRVDoorStatus : 0|2@1+ (1.0,0.0) [0.0|3.0] ""  CLU
 SG_ C_ASTDoorStatus : 2|2@1+ (1.0,0.0) [0.0|3.0] ""  CLU
 SG_ C_RLDoorStatus : 4|2@1+ (1.0,0.0) [0.0|3.0] ""  CLU
 SG_ C_RRDoorStatus : 6|2@1+ (1.0,0.0) [0.0|3.0] ""  CLU
 SG_ C_TrunkStatus : 8|2@1+ (1.0,0.0) [0.0|3.0] ""  CLU
 SG_ C_OSMirrorStatus : 10|2@1+ (1.0,0.0) [0.0|3.0] ""  CLU

BO_ 1056 SCC11: 8 SCC
 SG_ MainMode_ACC : 0|1@1+ (1.0,0.0) [0.0|1.0] ""  CLU,EMS,ESC
 SG_ SCCInfoDisplay : 1|3@1+ (1.0,0.0) [0.0|7.0] ""  CLU,ESC
 SG_ AliveCounterACC : 4|4@1+ (1.0,0.0) [0.0|15.0] ""  CLU,EMS,ESC,TCU
 SG_ VSetDis : 8|8@1+ (1.0,0.0) [0.0|255.0] "km/h or MPH"  CLU,ESC,TCU
 SG_ ObjValid : 16|1@1+ (1.0,0.0) [0.0|1.0] ""  CLU,ESC,TCU
 SG_ DriverAlertDisplay : 17|2@1+ (1.0,0.0) [0.0|3.0] ""  CLU,ESC
 SG_ TauGapSet : 19|3@1+ (1.0,0.0) [0.0|7.0] ""  CLU,ESC,TCU
 SG_ ACC_ObjStatus : 22|2@1+ (1.0,0.0) [0.0|3.0] ""  ABS,ESC
 SG_ ACC_ObjLatPos : 24|9@1+ (0.1,-20.0) [-20.0|31.1] "m"  ABS,ESC
 SG_ ACC_ObjDist : 33|11@1+ (0.1,0.0) [0.0|204.7] "m"  ABS,ESC
 SG_ ACC_ObjRelSpd : 44|12@1+ (0.1,-170.0) [-170.0|239.5] "m/s"  ABS,ESC
 SG_ Navi_SCC_Curve_Status : 56|2@1+ (1.0,0.0) [0.0|3.0] ""  CLU
 SG_ Navi_SCC_Curve_Act : 58|2@1+ (1.0,0.0) [0.0|3.0] ""  CLU
 SG_ Navi_SCC_Camera_Act : 60|2@1+ (1.0,0.0) [0.0|3.0] ""  CLU
 SG_ Navi_SCC_Camera_Status : 62|2@1+ (1.0,0.0) [0.0|3.0] ""  CLU

BO_ 1312 CGW3: 8 BCM
 SG_ CR_Photosensor_LH : 0|8@1+ (78.125,0.0) [0.0|20000.0] ""  DATC,DATC
 SG_ CR_Photosensor_RH : 10|8@1+ (78.125,0.0) [0.0|20000.0] ""  DATC,DATC
 SG_ CF_Hoodsw_memory : 22|2@1+ (1.0,0.0) [0.0|3.0] ""  EMS,EMS
 SG_ C_MirOutTempSns : 24|8@1+ (0.5,-40.5) [-40.0|60.0] "deg"  AAF,CLU,DATC,EMS,SPAS,AAF,DATC,EMS,SPAS

BO_ 544 ESP12: 8 ESC
 SG_ LAT_ACCEL : 0|11@1+ (0.01,-10.23) [-10.23|10.24] "m/s^2"  _4WD,ECS,IBOX,LCA,LDWS_LKAS,MDPS,PSB,SCC,TCU
 SG_ LAT_ACCEL_STAT : 11|1@1+ (1.0,0.0) [0.0|1.0] ""  _4WD,IBOX,LDWS_LKAS,MDPS,PSB,SCC,TCU
 SG_ LAT_ACCEL_DIAG : 12|1@1+ (1.0,0.0) [0.0|1.0] ""  _4WD,IBOX,LDWS_LKAS,MDPS,PSB,SCC,TCU
 SG_ LONG_ACCEL : 13|11@1+ (0.01,-10.23) [-10.23|10.24] "m/s^2"  _4WD,ECS,EMS,EPB,IBOX,LCA,LDWS_LKAS,PSB,SCC,SPAS,TCU
 SG_ LONG_ACCEL_STAT : 24|1@1+ (1.0,0.0) [0.0|1.0] ""  _4WD,EMS,EPB,IBOX,LDWS_LKAS,PSB,SCC,SPAS,TCU
 SG_ LONG_ACCEL_DIAG : 25|1@1+ (1.0,0.0) [0.0|1.0] ""  _4WD,EMS,EPB,IBOX,LDWS_LKAS,PSB,SCC,SPAS,TCU
 SG_ CYL_PRES : 26|12@1+ (0.1,0.0) [0.0|409.5] "Bar"  _4WD,ECS,EMS,EPB,IBOX,LDWS_LKAS,PSB,SCC,TCU
 SG_ CYL_PRES_STAT : 38|1@1+ (1.0,0.0) [0.0|1.0] ""  _4WD,ECS,EMS,EPB,IBOX,LDWS_LKAS,PSB,SCC,TCU
 SG_ CYL_PRESS_DIAG : 39|1@1+ (1.0,0.0) [0.0|1.0] ""  _4WD,ECS,EMS,EPB,IBOX,PSB,SCC,TCU
 SG_ YAW_RATE : 40|13@1+ (0.01,-40.95) [-40.95|40.96] ""  _4WD,AFLS,IBOX,LCA,LDWS_LKAS,MDPS,PSB,SCC,SPAS,TCU
 SG_ YAW_RATE_STAT : 53|1@1+ (1.0,0.0) [0.0|1.0] ""  _4WD,AFLS,IBOX,LCA,LDWS_LKAS,MDPS,PSB,SCC,SPAS,TCU
 SG_ YAW_RATE_DIAG : 54|1@1+ (1.0,0.0) [0.0|1.0] ""  _4WD,AFLS,IBOX,LCA,LDWS_LKAS,MDPS,PSB,SCC,SPAS,TCU
 SG_ ESP12_AliveCounter : 56|4@1+ (1.0,0.0) [0.0|15.0] ""  _4WD,EMS,LPI,TCU,TMU
 SG_ ESP12_Checksum : 60|4@1+ (1.0,0.0) [0.0|15.0] ""  _4WD,EMS,LPI,TCU,TMU

BO_ 1307 CLU16: 8 CLU
 SG_ CF_Clu_TirePressUnitNValueSet : 0|3@1+ (1.0,0.0) [0.0|7.0] ""  TPMS
 SG_ CF_Clu_SlifNValueSet : 3|2@1+ (1.0,0.0) [0.0|3.0] ""  LDWS_LKAS
 SG_ CF_Clu_RearWiperNValueSet : 12|2@1+ (1.0,0.0) [0.0|3.0] ""  BCM

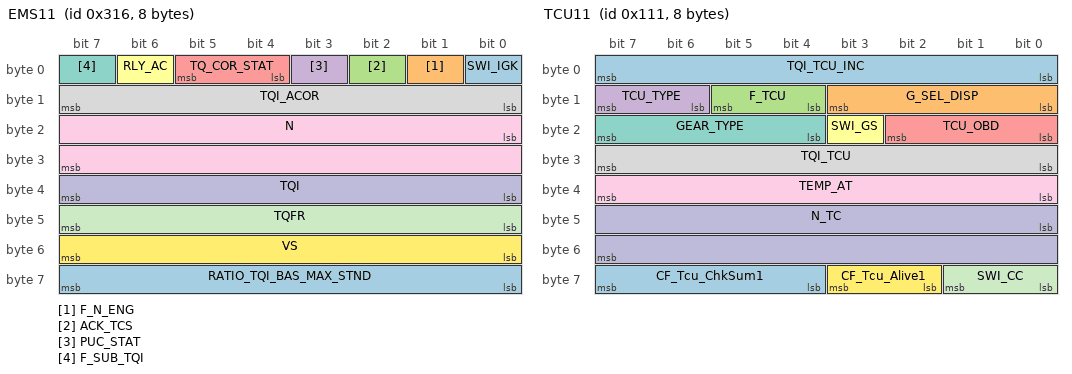
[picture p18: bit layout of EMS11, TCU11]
BO_ 790 EMS11: 8 EMS
 SG_ SWI_IGK : 0|1@1+ (1.0,0.0) [0.0|1.0] ""  _4WD,ABS,ACU,AHLS,CUBIS,DI_BOX,ECS,EPB,ESC,IBOX,LDWS_LKAS,MDPS,REA,SAS,SCC,TCU
 SG_ F_N_ENG : 1|1@1+ (1.0,0.0) [0.0|1.0] ""  _4WD,ACU,AFLS,CLU,CUBIS,DATC,ECS,EPB,ESC,IBOX,MDPS,SCC,TCU
 SG_ ACK_TCS : 2|1@1+ (1.0,0.0) [0.0|1.0] ""  ESC,IBOX
 SG_ PUC_STAT : 3|1@1+ (1.0,0.0) [0.0|1.0] ""  _4WD,CLU,DATC,IBOX,TCU
 SG_ TQ_COR_STAT : 4|2@1+ (1.0,0.0) [0.0|3.0] ""  _4WD,ESC,IBOX,TCU
 SG_ RLY_AC : 6|1@1+ (1.0,0.0) [0.0|1.0] ""  DATC,IBOX,TCU
 SG_ F_SUB_TQI : 7|1@1+ (1.0,0.0) [0.0|1.0] ""  _4WD,ECS,EPB,ESC,IBOX,TCU
 SG_ TQI_ACOR : 8|8@1+ (0.390625,0.0) [0.0|99.6094] "%"  _4WD,EPB,ESC,IBOX,TCU
 SG_ N : 16|16@1+ (0.25,0.0) [0.0|16383.75] "rpm"  _4WD,ACU,AFLS,CLU,CUBIS,DATC,ECS,EPB,ESC,FPCM,IBOX,MDPS,SCC,TCU
 SG_ TQI : 32|8@1+ (0.390625,0.0) [0.0|99.6094] "%"  _4WD,ECS,EPB,ESC,IBOX,TCU
 SG_ TQFR : 40|8@1+ (0.390625,0.0) [0.0|99.6094] "%"  _4WD,EPB,ESC,IBOX,TCU
 SG_ VS : 48|8@1+ (1.0,0.0) [0.0|254.0] "km/h"  _4WD,AAF,ACU,AHLS,BCM,CLU,DATC,ECS,EPB,IBOX,LCA,LDWS_LKAS,LVR,MDPS,ODS,SCC,SMK,SPAS,TCU,TPMS
 SG_ RATIO_TQI_BAS_MAX_STND : 56|8@1+ (0.0078,0.0) [0.0|2.0] ""  _4WD,IBOX,TCU

BO_ 1301 CLU14: 8 CLU
 SG_ CF_Clu_ADrUNValueSet : 0|3@1+ (1.0,0.0) [0.0|7.0] ""  BCM
 SG_ CF_Clu_ADrLNValueSet : 3|3@1+ (1.0,0.0) [0.0|7.0] ""  BCM
 SG_ CF_Clu_EscortHLNValueSet : 6|2@1+ (1.0,0.0) [0.0|3.0] ""  BCM
 SG_ CF_Clu_DoorLSNValueSet : 8|3@1+ (1.0,0.0) [0.0|7.0] ""  BCM
 SG_ CF_Clu_PSMNValueSet : 11|3@1+ (1.0,0.0) [0.0|7.0] ""  BCM
 SG_ CF_Clu_TTUnlockNValueSet : 14|2@1+ (1.0,0.0) [0.0|3.0] ""  BCM
 SG_ CF_Clu_PTGMNValueSet : 16|2@1+ (1.0,0.0) [0.0|3.0] ""  BCM
 SG_ CF_Clu_SCMNValueSet : 18|2@1+ (1.0,0.0) [0.0|3.0] ""  BCM
 SG_ CF_Clu_WlightNValueSet : 20|2@1+ (1.0,0.0) [0.0|3.0] ""  BCM
 SG_ CF_Clu_TempUnitNValueSet : 22|2@1+ (1.0,0.0) [0.0|3.0] ""  BCM,DATC
 SG_ CF_Clu_MoodLpNValueSet : 24|3@1+ (1.0,0.0) [0.0|7.0] ""  BCM
 SG_ CF_Clu_TrfChgSet : 27|2@1+ (1.0,0.0) [0.0|3.0] ""  AFLS
 SG_ CF_Clu_OTTurnNValueSet : 29|3@1+ (1.0,0.0) [0.0|7.0] ""  BCM
 SG_ CF_Clu_LcaNValueSet : 32|2@1+ (1.0,0.0) [0.0|3.0] ""  LCA
 SG_ CF_Clu_RctaNValueSet : 34|2@1+ (1.0,0.0) [0.0|3.0] ""  LCA
 SG_ CF_Clu_RcwNValueSet : 36|2@1+ (1.0,0.0) [0.0|3.0] ""  LCA
 SG_ CF_Clu_EscOffNValueSet : 38|3@1+ (1.0,0.0) [0.0|7.0] ""  ESC
 SG_ CF_Clu_SccNaviCrvNValueSet : 41|2@1+ (1.0,0.0) [0.0|3.0] ""  SCC
 SG_ CF_Clu_SccNaviCamNValueSet : 43|2@1+ (1.0,0.0) [0.0|3.0] ""  SCC
 SG_ CF_Clu_SccAebNValueSet : 45|2@1+ (1.0,0.0) [0.0|3.0] ""  SCC
 SG_ CF_Clu_LkasModeNValueSet : 47|2@1+ (1.0,0.0) [0.0|3.0] ""  LDWS_LKAS
 SG_ CF_Clu_FcwNValueSet : 51|2@1+ (1.0,0.0) [0.0|3.0] ""  LDWS_LKAS
 SG_ CF_Clu_PasSpkrLvNValueSet : 53|3@1+ (1.0,0.0) [0.0|7.0] ""  BCM
 SG_ CF_Clu_SccDrvModeNValueSet : 56|3@1+ (1.0,0.0) [0.0|7.0] ""  SCC
 SG_ CF_Clu_HAnBNValueSet : 59|2@1+ (1.0,0.0) [0.0|3.0] ""  BCM
 SG_ CF_Clu_HfreeTrunkTgNValueSet : 61|3@1+ (1.0,0.0) [0.0|7.0] ""  BCM

BO_ 275 TCU13: 8 TCU
 SG_ N_TGT_LUP : 0|8@1+ (10.0,500.0) [500.0|3040.0] "rpm"  EMS,IBOX
 SG_ SLOPE_TCU : 8|6@1+ (0.5,-16.0) [-16.0|15.5] "%"  CLU,CUBIS,EMS,IBOX
 SG_ CF_Tcu_InhCda : 14|1@1+ (1.0,0.0) [0.0|1.0] ""  EMS,IBOX
 SG_ CF_Tcu_IsgInhib : 15|1@1+ (1.0,0.0) [0.0|1.0] ""  EMS,IBOX
 SG_ CF_Tcu_BkeOnReq : 16|2@1+ (1.0,0.0) [0.0|3.0] ""  EMS,IBOX
 SG_ CF_Tcu_NCStat : 18|2@1+ (1.0,0.0) [0.0|3.0] ""  EMS,IBOX
 SG_ CF_Tcu_TarGr : 20|4@1+ (1.0,0.0) [0.0|15.0] ""  _4WD,CLU,DATC,EMS,EPB,ESC,IBOX,SCC
 SG_ CF_Tcu_ShfPatt : 24|4@1+ (1.0,0.0) [0.0|15.0] ""  CLU,CUBIS,EMS,IBOX
 SG_ CF_Tcu_InhVis : 28|1@1+ (1.0,0.0) [0.0|1.0] ""  EMS,IBOX
 SG_ CF_Tcu_PRelReq : 29|1@1+ (1.0,0.0) [0.0|1.0] ""  IBOX,LVR
 SG_ CF_Tcu_ITPhase : 30|1@1+ (1.0,0.0) [0.0|1.0] ""  EMS,IBOX
 SG_ CF_Tcu_ActEcoRdy : 31|1@1+ (1.0,0.0) [0.0|1.0] ""  EMS,IBOX
 SG_ CF_Tcu_TqGrdLim : 32|8@1+ (10.0,0.0) [0.0|2540.0] "Nm/s"  EMS,IBOX
 SG_ CR_Tcu_IsgTgtRPM : 40|8@1+ (20.0,0.0) [0.0|3500.0] "rpm"  EMS,IBOX
 SG_ CF_Tcu_SptRdy : 48|1@1+ (1.0,0.0) [0.0|1.0] ""  CLU,IBOX
 SG_ CF_Tcu_SbwPInfo : 56|1@1+ (1.0,0.0) [0.0|1.0] ""  EMS,IBOX
 SG_ CF_Tcu_Alive3 : 58|2@1+ (1.0,0.0) [0.0|3.0] ""  EMS,IBOX
 SG_ CF_Tcu_ChkSum3 : 60|4@1+ (1.0,0.0) [0.0|15.0] ""  EMS,IBOX

BO_ 274 TCU12: 8 TCU
 SG_ ETL_TCU : 0|8@1+ (2.0,0.0) [0.0|508.0] "Nm"  EMS,IBOX
 SG_ CUR_GR : 8|4@1+ (1.0,0.0) [0.0|15.0] ""  _4WD,EMS,ESC,IBOX,SCC,TPMS
 SG_ CF_Tcu_Alive : 12|2@1+ (1.0,0.0) [0.0|3.0] ""  EMS,ESC,IBOX,SCC
 SG_ CF_Tcu_ChkSum : 14|2@1+ (1.0,0.0) [0.0|3.0] ""  EMS,ESC,IBOX,SCC
 SG_ VS_TCU : 16|8@1+ (1.0,0.0) [0.0|254.0] "km/h"  BCM,CLU,DATC,EMS,IBOX,LCA,LVR,PGS,SMK,SNV
 SG_ FUEL_CUT_TCU : 28|1@1+ (1.0,0.0) [0.0|1.0] ""  EMS,IBOX
 SG_ INH_FUEL_CUT : 29|1@1+ (1.0,0.0) [0.0|1.0] ""  EMS,IBOX
 SG_ IDLE_UP_TCU : 30|1@1+ (1.0,0.0) [0.0|1.0] ""  EMS,IBOX
 SG_ N_INC_TCU : 31|1@1+ (1.0,0.0) [0.0|1.0] ""  EMS,IBOX
 SG_ SPK_RTD_TCU : 32|8@1+ (0.375,-23.625) [-15.0|15.0] ""  EMS,IBOX
 SG_ N_TC_RAW : 40|16@1+ (0.25,0.0) [0.0|16383.5] "rpm"  EMS,IBOX
 SG_ VS_TCU_DECIMAL : 56|8@1+ (0.0078125,0.0) [0.0|0.9921875] "km/h"  CLU,EMS,IBOX,LCA

BO_ 273 TCU11: 8 TCU
 SG_ TQI_TCU_INC : 0|8@1+ (0.390625,0.0) [0.0|99.609375] "%"  EMS,ESC,IBOX
 SG_ G_SEL_DISP : 8|4@1+ (1.0,0.0) [0.0|15.0] ""  _4WD,AFLS,AVM,BCM,CGW,CLU,CUBIS,ECS,EMS,EPB,ESC,IAP,IBOX,LCA,LDWS_LKAS,LVR,MDPS,PGS,SCC,SMK,SNV,SPAS,TPMS
 SG_ F_TCU : 12|2@1+ (1.0,0.0) [0.0|3.0] ""  EMS,ESC,IBOX
 SG_ TCU_TYPE : 14|2@1+ (1.0,0.0) [0.0|3.0] ""  _4WD,EMS,ESC,IBOX
 SG_ TCU_OBD : 16|3@1+ (1.0,0.0) [0.0|7.0] ""  EMS,ESC,IBOX
 SG_ SWI_GS : 19|1@1+ (1.0,0.0) [0.0|1.0] ""  _4WD,EMS,EPB,ESC,IBOX,SCC
 SG_ GEAR_TYPE : 20|4@1+ (1.0,0.0) [0.0|15.0] ""  _4WD,CLU,EMS,ESC,IBOX,SCC
 SG_ TQI_TCU : 24|8@1+ (0.390625,0.0) [0.0|99.609375] "%"  EMS,ESC,IBOX
 SG_ TEMP_AT : 32|8@1+ (1.0,-40.0) [-40.0|214.0] "deg"  AAF,CLU,CUBIS,EMS,ESC,IBOX
 SG_ N_TC : 40|16@1+ (0.25,0.0) [0.0|16383.5] "rpm"  _4WD,EMS,EPB,ESC,IBOX
 SG_ SWI_CC : 56|2@1+ (1.0,0.0) [0.0|3.0] ""  _4WD,CLU,EMS,ESC,IBOX
 SG_ CF_Tcu_Alive1 : 58|2@1+ (1.0,0.0) [0.0|3.0] ""  EMS,IBOX
 SG_ CF_Tcu_ChkSum1 : 60|4@1+ (1.0,0.0) [0.0|15.0] ""  EMS,IBOX

BO_ 16 ACU13: 8 ACU
 SG_ CF_Acu_CshAct : 0|1@1+ (1.0,0.0) [0.0|1.0] ""  CUBIS,IBOX,ODS

BO_ 1040 CGW_USM1: 8 BCM
 SG_ CF_Gway_ATTurnRValue : 0|2@1+ (1.0,0.0) [0.0|3.0] ""  CLU
 SG_ CF_Gway_PTGMRValue : 2|2@1+ (1.0,0.0) [0.0|3.0] ""  CLU
 SG_ CF_Gway_EscortHLRValue : 4|2@1+ (1.0,0.0) [0.0|3.0] ""  CLU
 SG_ CF_Gway_TTUnlockRValue : 6|2@1+ (1.0,0.0) [0.0|3.0] ""  CLU
 SG_ CF_Gway_ADrLRValue : 8|3@1+ (1.0,0.0) [0.0|7.0] ""  CLU
 SG_ CF_Gway_ADrURValue : 11|3@1+ (1.0,0.0) [0.0|7.0] ""  CLU
 SG_ CF_Gway_SCMRValue : 14|2@1+ (1.0,0.0) [0.0|3.0] ""  CLU
 SG_ CF_Gway_WlightRValue : 16|2@1+ (1.0,0.0) [0.0|3.0] ""  CLU
 SG_ CF_Gway_PSMRValue : 18|3@1+ (1.0,0.0) [0.0|7.0] ""  CLU
 SG_ CF_Gway_OTTurnRValue : 21|3@1+ (1.0,0.0) [0.0|7.0] ""  CLU
 SG_ CF_Gway_DrLockSoundRValue : 24|3@1+ (1.0,0.0) [0.0|7.0] ""  CLU
 SG_ CF_Gway_HAnBRValue : 27|3@1+ (1.0,0.0) [0.0|7.0] ""  CLU
 SG_ CF_Gway_MoodLpRValue : 30|2@1+ (1.0,0.0) [0.0|3.0] ""  CLU
 SG_ CF_Gway_HfreeTrunkRValue : 32|3@1+ (1.0,0.0) [0.0|7.0] ""  CLU
 SG_ CF_Gway_AutoLightRValue : 35|3@1+ (1.0,0.0) [0.0|7.0] ""  CLU
 SG_ CF_Gway_RearWiperRValue : 38|2@1+ (1.0,0.0) [0.0|3.0] ""  CLU
 SG_ CF_Gway_PasSpkrLvRValue : 40|3@1+ (1.0,0.0) [0.0|7.0] ""  CLU

BO_ 1292 CLU13: 8 CLU
 SG_ CF_Clu_LowfuelWarn : 0|2@1+ (1.0,0.0) [0.0|3.0] ""  BCM,FPCM,IBOX
 SG_ CF_Clu_RefDetMod : 2|1@1+ (1.0,0.0) [0.0|1.0] ""  IBOX
 SG_ CF_Clu_AvgFCU : 3|2@1+ (1.0,0.0) [0.0|3.0] ""  IBOX
 SG_ CF_Clu_AvsmCur : 5|1@1+ (1.0,0.0) [0.0|1.0] ""  ESC,SCC
 SG_ CF_Clu_AvgFCI : 6|10@1+ (0.1,0.0) [0.0|102.2] ""  IBOX
 SG_ CF_Clu_DrivingModeSwi : 16|2@1+ (1.0,0.0) [0.0|3.0] ""  DATC,ECS,EMS,ESC,IAP,MDPS,TCU
 SG_ CF_Clu_FuelDispLvl : 18|5@1+ (1.0,0.0) [0.0|31.0] ""  CGW,IBOX
 SG_ CF_Clu_FlexSteerSW : 23|1@1+ (1.0,0.0) [0.0|1.0] ""  MDPS
 SG_ CF_Clu_DTE : 24|10@1+ (1.0,0.0) [0.0|1023.0] ""  DATC
 SG_ CF_Clu_TripUnit : 34|2@1+ (1.0,0.0) [0.0|3.0] ""  DATC
 SG_ CF_Clu_SWL_Stat : 36|3@1+ (1.0,0.0) [0.0|7.0] ""  ACU,EMS
 SG_ CF_Clu_ActiveEcoSW : 39|1@1+ (1.0,0.0) [0.0|1.0] ""  DATC,EMS,TCU
 SG_ CF_Clu_EcoDriveInf : 40|3@1+ (1.0,0.0) [0.0|7.0] ""  CUBIS,EMS,IAP,IBOX
 SG_ CF_Clu_IsaMainSW : 43|1@1+ (1.0,0.0) [0.0|1.0] ""  EMS
 SG_ CF_Clu_LdwsLkasSW : 56|1@1+ (1.0,0.0) [0.0|1.0] ""  LDWS_LKAS
 SG_ CF_Clu_AltLStatus : 59|1@1+ (1.0,0.0) [0.0|1.0] ""  BCM,DATC,EMS
 SG_ CF_Clu_AliveCnt2 : 60|4@1+ (1.0,0.0) [0.0|15.0] ""  EMS,LDWS_LKAS

BO_ 1290 SCC13: 8 SCC
 SG_ SCCDrvModeRValue : 0|3@1+ (1.0,0.0) [0.0|7.0] ""  CLU
 SG_ SCC_Equip : 3|1@1+ (1.0,0.0) [0.0|1.0] ""  ESC
 SG_ AebDrvSetStatus : 4|3@1+ (1.0,0.0) [0.0|7.0] ""  CLU,ESC

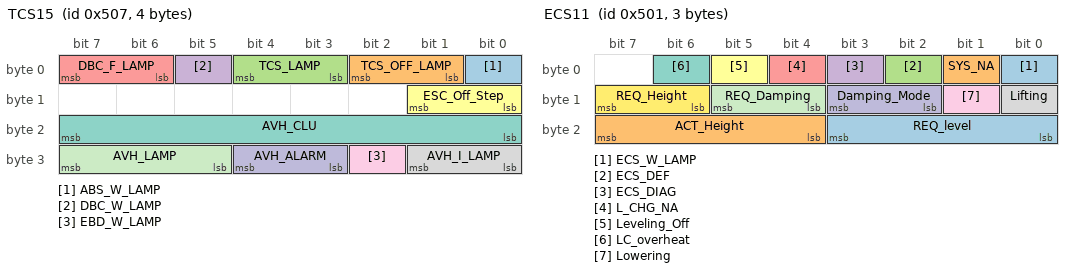
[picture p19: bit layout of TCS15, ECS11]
BO_ 1287 TCS15: 4 ESC
 SG_ ABS_W_LAMP : 0|1@1+ (1.0,0.0) [0.0|1.0] ""  _4WD,CLU,CUBIS,IBOX
 SG_ TCS_OFF_LAMP : 1|2@1+ (1.0,0.0) [0.0|1.0] ""  _4WD,ACU,CLU
 SG_ TCS_LAMP : 3|2@1+ (1.0,0.0) [0.0|3.0] ""  _4WD,ACU,CLU,CUBIS,IBOX,SCC
 SG_ DBC_W_LAMP : 5|1@1+ (1.0,0.0) [0.0|1.0] ""  _4WD,CLU
 SG_ DBC_F_LAMP : 6|2@1+ (1.0,0.0) [0.0|3.0] ""  _4WD,CLU
 SG_ ESC_Off_Step : 8|2@1+ (1.0,0.0) [0.0|3.0] ""  CLU
 SG_ AVH_CLU : 16|8@1+ (1.0,0.0) [0.0|255.0] ""  CLU,EPB
 SG_ AVH_I_LAMP : 24|2@1+ (1.0,0.0) [0.0|3.0] ""  EPB
 SG_ EBD_W_LAMP : 26|1@1+ (1.0,0.0) [0.0|1.0] ""  _4WD,CLU
 SG_ AVH_ALARM : 27|2@1+ (1.0,0.0) [0.0|3.0] ""  CLU
 SG_ AVH_LAMP : 29|3@1+ (1.0,0.0) [0.0|7.0] ""  CLU,EPB,SPAS

BO_ 1282 TCU14: 4 TCU
 SG_ CF_TCU_WarnMsg : 0|3@1+ (1.0,0.0) [0.0|7.0] ""  CLU
 SG_ CF_TCU_WarnImg : 3|1@1+ (1.0,0.0) [0.0|1.0] ""  CLU
 SG_ CF_TCU_WarnSnd : 4|1@1+ (1.0,0.0) [0.0|1.0] ""  CLU
 SG_ CF_Tcu_GSel_BlinkReq : 5|1@1+ (1.0,0.0) [0.0|1.0] ""  CLU,LVR
 SG_ CF_Tcu_StRelStat : 12|1@1+ (1.0,0.0) [0.0|1.0] ""  CLU,EMS,ESC
 SG_ CF_Tcu_DriWarn1 : 13|3@1+ (1.0,0.0) [0.0|7.0] ""  CLU,EMS,ESC
 SG_ CF_Tcu_DriWarn2 : 16|2@1+ (1.0,0.0) [0.0|3.0] ""  CLU,EMS,ESC

BO_ 1281 ECS11: 3 ECS
 SG_ ECS_W_LAMP : 0|1@1+ (1.0,0.0) [0.0|1.0] ""  CLU,CUBIS,IBOX
 SG_ SYS_NA : 1|1@1+ (1.0,0.0) [0.0|1.0] ""  CLU
 SG_ ECS_DEF : 2|1@1+ (1.0,0.0) [0.0|1.0] ""  CLU
 SG_ ECS_DIAG : 3|1@1+ (1.0,0.0) [0.0|1.0] ""  CLU
 SG_ L_CHG_NA : 4|1@1+ (1.0,0.0) [0.0|1.0] ""  CLU
 SG_ Leveling_Off : 5|1@1+ (1.0,0.0) [0.0|1.0] ""  CLU
 SG_ LC_overheat : 6|1@1+ (1.0,0.0) [0.0|1.0] ""  CLU
 SG_ Lifting : 8|1@1+ (1.0,0.0) [0.0|1.0] ""  CLU
 SG_ Lowering : 9|1@1+ (1.0,0.0) [0.0|1.0] ""  CLU
 SG_ Damping_Mode : 10|2@1+ (1.0,0.0) [0.0|3.0] ""  CLU
 SG_ REQ_Damping : 12|2@1+ (1.0,0.0) [0.0|3.0] ""  CLU
 SG_ REQ_Height : 14|2@1+ (1.0,0.0) [0.0|3.0] ""  CLU
 SG_ REQ_level : 16|4@1+ (1.0,0.0) [0.0|15.0] ""  CLU
 SG_ ACT_Height : 20|4@1+ (1.0,0.0) [0.0|15.0] ""  CLU

BO_ 1024 CLU_CFG11: 2 CLU
 SG_ Vehicle_Type : 0|16@1+ (1.0,0.0) [0.0|65536.0] ""  _4WD

BO_ 1280 ACU14: 1 ACU
 SG_ CF_SWL_Ind : 0|2@1+ (1.0,0.0) [0.0|3.0] ""  CLU
 SG_ CF_TTL_Ind : 2|2@1+ (1.0,0.0) [0.0|3.0] ""  CLU
 SG_ CF_SBR_Ind : 4|2@1+ (1.0,0.0) [0.0|3.0] ""  BCM,CLU

BO_ 512 EMS20: 6 EMS
 SG_ FCO : 0|16@1+ (0.128,0.0) [0.0|8388.48] "ul"  CLU,CUBIS,FPCM,IBOX
 SG_ CF_Ems_PumpTPres : 16|8@1+ (3.137254902,0.0) [0.0|800.0] "kPa"  FPCM,IBOX
 SG_ Split_Stat : 32|1@1+ (1.0,0.0) [0.0|1.0] ""  FPCM
